VERSION "dbc-export 1 2025.20.8"

NS_ :

BS_:

BU_: APP APS DAS EPAS3S EPASTS ESP GTW IBST IDB PARK RADC RCM RCM3 RCU TPMS USM

BO_ 1045 APP_backupDashCamStatus: 1 APP
 SG_ APP_backupDashCamFeedGood : 0|1@1+ (1,0) [0|1] "" Vector__XXX
 SG_ APP_backupDashCamFrameRate : 1|7@1+ (1,0) [0|127] "" Vector__XXX

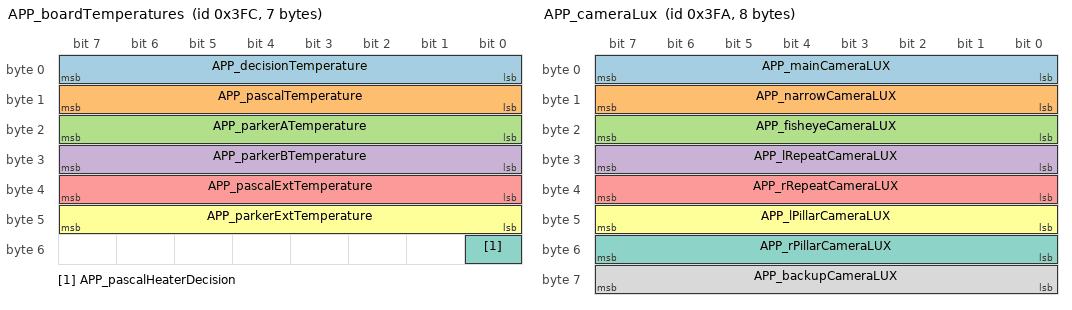
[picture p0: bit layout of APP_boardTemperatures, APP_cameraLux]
BO_ 1020 APP_boardTemperatures: 7 APP
 SG_ APP_decisionTemperature : 0|8@1+ (1,-128) [-128|127] "C" Vector__XXX
 SG_ APP_pascalTemperature : 8|8@1+ (1,-128) [-128|127] "C" Vector__XXX
 SG_ APP_parkerATemperature : 16|8@1+ (1,-128) [-128|127] "C" Vector__XXX
 SG_ APP_parkerBTemperature : 24|8@1+ (1,-128) [-128|127] "C" Vector__XXX
 SG_ APP_pascalExtTemperature : 32|8@1+ (1,-128) [-128|127] "C" Vector__XXX
 SG_ APP_parkerExtTemperature : 40|8@1+ (1,-128) [-128|127] "C" Vector__XXX
 SG_ APP_pascalHeaterDecision : 48|1@1+ (1,0) [0|1] "" Vector__XXX

BO_ 1018 APP_cameraLux: 8 APP
 SG_ APP_mainCameraLUX : 0|8@1+ (0.5,0) [0|127] "lux^0.5" Vector__XXX
 SG_ APP_narrowCameraLUX : 8|8@1+ (0.5,0) [0|127] "lux^0.5" Vector__XXX
 SG_ APP_fisheyeCameraLUX : 16|8@1+ (0.5,0) [0|127] "lux^0.5" Vector__XXX
 SG_ APP_lRepeatCameraLUX : 24|8@1+ (0.5,0) [0|127] "lux^0.5" Vector__XXX
 SG_ APP_rRepeatCameraLUX : 32|8@1+ (0.5,0) [0|127] "lux^0.5" Vector__XXX
 SG_ APP_lPillarCameraLUX : 40|8@1+ (0.5,0) [0|127] "lux^0.5" Vector__XXX
 SG_ APP_rPillarCameraLUX : 48|8@1+ (0.5,0) [0|127] "lux^0.5" Vector__XXX
 SG_ APP_backupCameraLUX : 56|8@1+ (0.5,0) [0|127] "lux^0.5" Vector__XXX

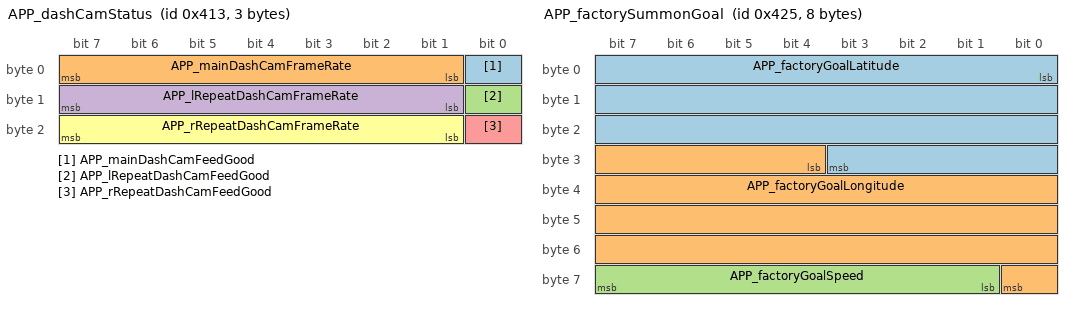
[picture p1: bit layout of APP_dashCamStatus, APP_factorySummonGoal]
BO_ 1043 APP_dashCamStatus: 3 APP
 SG_ APP_mainDashCamFeedGood : 0|1@1+ (1,0) [0|1] "" Vector__XXX
 SG_ APP_mainDashCamFrameRate : 1|7@1+ (1,0) [0|127] "" Vector__XXX
 SG_ APP_lRepeatDashCamFeedGood : 8|1@1+ (1,0) [0|1] "" Vector__XXX
 SG_ APP_lRepeatDashCamFrameRate : 9|7@1+ (1,0) [0|127] "" Vector__XXX
 SG_ APP_rRepeatDashCamFeedGood : 16|1@1+ (1,0) [0|1] "" Vector__XXX
 SG_ APP_rRepeatDashCamFrameRate : 17|7@1+ (1,0) [0|127] "" Vector__XXX

BO_ 1061 APP_factorySummonGoal: 8 APP
 SG_ APP_factoryGoalLatitude : 0|28@1- (1.0e-06,0) [-134.217728|134.217727] "deg" Vector__XXX
 SG_ APP_factoryGoalLongitude : 28|29@1- (1.0e-06,0) [-268.435456|268.435454] "deg" Vector__XXX
 SG_ APP_factoryGoalSpeed : 57|7@1+ (1,0) [0|100] "mph" Vector__XXX

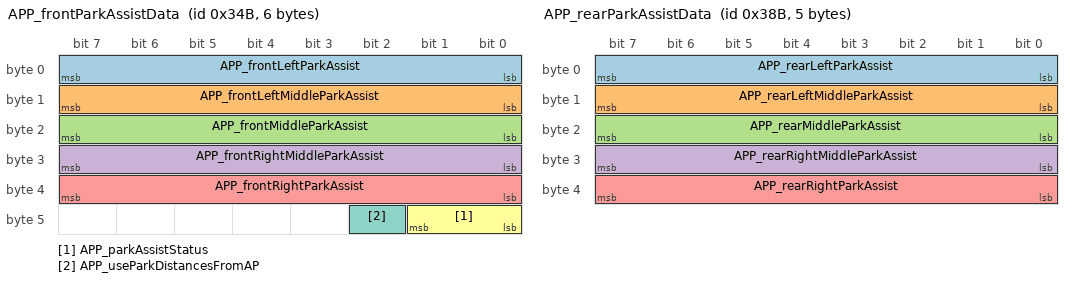
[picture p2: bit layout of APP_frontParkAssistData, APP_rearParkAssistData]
BO_ 843 APP_frontParkAssistData: 6 APP
 SG_ APP_frontLeftParkAssist : 0|8@1+ (1,0) [0|254] "cm" Vector__XXX
 SG_ APP_frontLeftMiddleParkAssist : 8|8@1+ (1,0) [0|254] "cm" Vector__XXX
 SG_ APP_frontMiddleParkAssist : 16|8@1+ (1,0) [0|254] "cm" Vector__XXX
 SG_ APP_frontRightMiddleParkAssist : 24|8@1+ (1,0) [0|254] "cm" Vector__XXX
 SG_ APP_frontRightParkAssist : 32|8@1+ (1,0) [0|254] "cm" Vector__XXX
 SG_ APP_parkAssistStatus : 40|2@1+ (1,0) [0|2] "" Vector__XXX
 SG_ APP_useParkDistancesFromAP : 42|1@1+ (1,0) [0|1] "" Vector__XXX

BO_ 1353 APP_info: 8 APP
 SG_ APP_infoIndex M : 0|8@1+ (1,0) [0|255] "" Vector__XXX
 SG_ APP_buildType m0 : 8|8@1+ (1,0) [0|255] "" Vector__XXX

BO_ 907 APP_rearParkAssistData: 5 APP
 SG_ APP_rearLeftParkAssist : 0|8@1+ (1,0) [0|254] "cm" Vector__XXX
 SG_ APP_rearLeftMiddleParkAssist : 8|8@1+ (1,0) [0|254] "cm" Vector__XXX
 SG_ APP_rearMiddleParkAssist : 16|8@1+ (1,0) [0|254] "cm" Vector__XXX
 SG_ APP_rearRightMiddleParkAssist : 24|8@1+ (1,0) [0|254] "cm" Vector__XXX
 SG_ APP_rearRightParkAssist : 32|8@1+ (1,0) [0|254] "cm" Vector__XXX

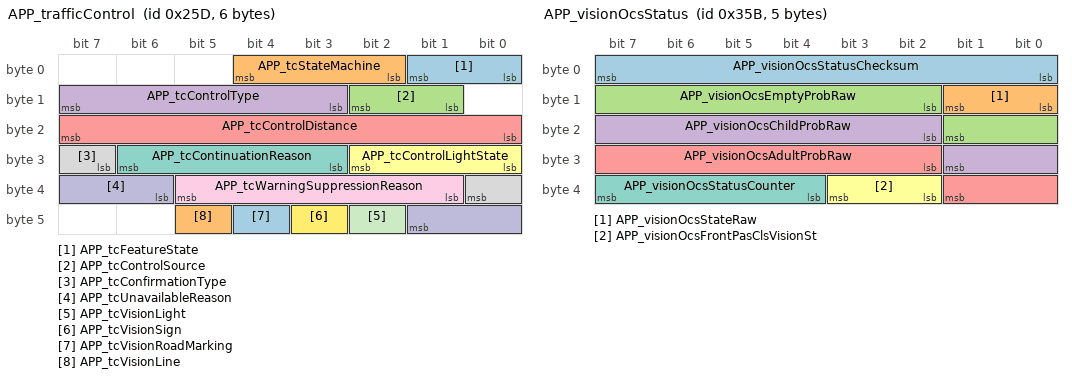
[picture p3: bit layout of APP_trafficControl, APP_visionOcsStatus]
BO_ 605 APP_trafficControl: 6 APP
 SG_ APP_tcFeatureState : 0|2@1+ (1,0) [0|3] "" Vector__XXX
 SG_ APP_tcStateMachine : 2|3@1+ (1,0) [0|7] "" Vector__XXX
 SG_ APP_tcControlSource : 9|2@1+ (1,0) [0|3] "" Vector__XXX
 SG_ APP_tcControlType : 11|5@1+ (1,0) [0|31] "" Vector__XXX
 SG_ APP_tcControlDistance : 16|8@1+ (1,0) [0|254] "m" Vector__XXX
 SG_ APP_tcControlLightState : 24|3@1+ (1,0) [0|7] "" Vector__XXX
 SG_ APP_tcContinuationReason : 27|4@1+ (1,0) [0|15] "" Vector__XXX
 SG_ APP_tcConfirmationType : 31|2@1+ (1,0) [0|3] "" Vector__XXX
 SG_ APP_tcWarningSuppressionReason : 33|5@1+ (1,0) [0|31] "" Vector__XXX
 SG_ APP_tcUnavailableReason : 38|4@1+ (1,0) [0|15] "" Vector__XXX
 SG_ APP_tcVisionLight : 42|1@1+ (1,0) [0|1] "" Vector__XXX
 SG_ APP_tcVisionSign : 43|1@1+ (1,0) [0|1] "" Vector__XXX
 SG_ APP_tcVisionRoadMarking : 44|1@1+ (1,0) [0|1] "" Vector__XXX
 SG_ APP_tcVisionLine : 45|1@1+ (1,0) [0|1] "" Vector__XXX

BO_ 859 APP_visionOcsStatus: 5 APP
 SG_ APP_visionOcsStatusChecksum : 0|8@1+ (1,0) [0|255] "" Vector__XXX
 SG_ APP_visionOcsStateRaw : 8|2@1+ (1,0) [0|3] "" Vector__XXX
 SG_ APP_visionOcsEmptyProbRaw : 10|8@1+ (0.004,0) [0|1.016] "points" Vector__XXX
 SG_ APP_visionOcsChildProbRaw : 18|8@1+ (0.004,0) [0|1.016] "points" Vector__XXX
 SG_ APP_visionOcsAdultProbRaw : 26|8@1+ (0.004,0) [0|1.016] "points" Vector__XXX
 SG_ APP_visionOcsFrontPasClsVisionSt : 34|2@1+ (1,0) [0|3] "" Vector__XXX
 SG_ APP_visionOcsStatusCounter : 36|4@1+ (1,0) [0|15] "" Vector__XXX

BO_ 809 APP_warningMatrix0: 8 APP
 SG_ APP_w001_DEPRECATED : 0|1@1+ (1,0) [0|1] "" Vector__XXX
 SG_ APP_w002_ldwDisabled : 1|1@1+ (1,0) [0|1] "" Vector__XXX
 SG_ APP_w003_isaDisabled : 2|1@1+ (1,0) [0|1] "" Vector__XXX
 SG_ APP_w004_accDisabled : 3|1@1+ (1,0) [0|1] "" Vector__XXX
 SG_ APP_w005_fcwCancelled : 4|1@1+ (1,0) [0|1] "" Vector__XXX
 SG_ APP_w006_aebCancelled : 5|1@1+ (1,0) [0|1] "" Vector__XXX
 SG_ APP_w007_ahlbDisabled : 6|1@1+ (1,0) [0|1] "" Vector__XXX
 SG_ APP_w008_parkDisabled : 7|1@1+ (1,0) [0|1] "" Vector__XXX
 SG_ APP_w009_aebFault : 8|1@1+ (1,0) [0|1] "" Vector__XXX
 SG_ APP_w010_radcCalibIssue : 9|1@1+ (1,0) [0|1] "" Vector__XXX
 SG_ APP_w011_scaEvent : 10|1@1+ (1,0) [0|1] "" Vector__XXX
 SG_ APP_w012_Cam_BootFailure : 11|1@1+ (1,0) [0|1] "" Vector__XXX
 SG_ APP_w013_Cam_Watchdog : 12|1@1+ (1,0) [0|1] "" Vector__XXX
 SG_ APP_w014_swAssert : 13|1@1+ (1,0) [0|1] "" Vector__XXX
 SG_ APP_w015_Camera_Failsafes : 14|1@1+ (1,0) [0|1] "" Vector__XXX
 SG_ APP_w016_aeb_e_event : 15|1@1+ (1,0) [0|1] "" Vector__XXX
 SG_ APP_w017_Cam_Msg_MIA : 16|1@1+ (1,0) [0|1] "" Vector__XXX
 SG_ APP_w018_ECU_Power_Issue : 17|1@1+ (1,0) [0|1] "" Vector__XXX
 SG_ APP_w019_ECU_Stack_Overflow : 18|1@1+ (1,0) [0|1] "" Vector__XXX
 SG_ APP_w020_ECU_checkstopError : 19|1@1+ (1,0) [0|1] "" Vector__XXX
 SG_ APP_w021_ECU_Temperature_Issue : 20|1@1+ (1,0) [0|1] "" Vector__XXX
 SG_ APP_w022_ECU_EEPROM_Failure : 21|1@1+ (1,0) [0|1] "" Vector__XXX
 SG_ APP_w023_ECU_Cam_Statemismatc : 22|1@1+ (1,0) [0|1] "" Vector__XXX
 SG_ APP_w024_ECU_Watchdog_Reset : 23|1@1+ (1,0) [0|1] "" Vector__XXX
 SG_ APP_w025_LC_Steering_Override : 24|1@1+ (1,0) [0|1] "" Vector__XXX
 SG_ APP_w026_ECU_timingIssue : 25|1@1+ (1,0) [0|1] "" Vector__XXX
 SG_ APP_w027_ECU_Reset_Fault : 26|1@1+ (1,0) [0|1] "" Vector__XXX
 SG_ APP_w028_spi_rx_error : 27|1@1+ (1,0) [0|1] "" Vector__XXX
 SG_ APP_w029_spi_tx_error : 28|1@1+ (1,0) [0|1] "" Vector__XXX
 SG_ APP_w030_Heater_Issue : 29|1@1+ (1,0) [0|1] "" Vector__XXX
 SG_ APP_w031_canRxError : 30|1@1+ (1,0) [0|1] "" Vector__XXX
 SG_ APP_w032_canTxError : 31|1@1+ (1,0) [0|1] "" Vector__XXX
 SG_ APP_w033_gtwMia : 32|1@1+ (1,0) [0|1] "" Vector__XXX
 SG_ APP_w034_sccmMia : 33|1@1+ (1,0) [0|1] "" Vector__XXX
 SG_ APP_w035_espMia : 34|1@1+ (1,0) [0|1] "" Vector__XXX
 SG_ APP_w036_bdyMia : 35|1@1+ (1,0) [0|1] "" Vector__XXX
 SG_ APP_w037_camTacIssue : 36|1@1+ (1,0) [0|1] "" Vector__XXX
 SG_ APP_w038_camFailure : 37|1@1+ (1,0) [0|1] "" Vector__XXX
 SG_ APP_w039_sdm_rcm_Mia : 38|1@1+ (1,0) [0|1] "" Vector__XXX
 SG_ APP_w040_autopilotAngleSaturated : 39|1@1+ (1,0) [0|1] "" Vector__XXX
 SG_ APP_w041_autopilotRateSaturated : 40|1@1+ (1,0) [0|1] "" Vector__XXX
 SG_ APP_w042_autopilotAborting : 41|1@1+ (1,0) [0|1] "" Vector__XXX
 SG_ APP_w043_camLongRunTime : 42|1@1+ (1,0) [0|1] "" Vector__XXX
 SG_ APP_w044_appMobileyeFailure : 43|1@1+ (1,0) [0|1] "" Vector__XXX
 SG_ APP_w045_radMia : 44|1@1+ (1,0) [0|1] "" Vector__XXX
 SG_ APP_w046_eepromRecordAbsent : 45|1@1+ (1,0) [0|1] "" Vector__XXX
 SG_ APP_w047_edrEvent : 46|1@1+ (1,0) [0|1] "" Vector__XXX
 SG_ APP_w048_APP_Features_Disabled : 47|1@1+ (1,0) [0|1] "" Vector__XXX
 SG_ APP_w049_eyeqVersionMismatch : 48|1@1+ (1,0) [0|1] "" Vector__XXX
 SG_ APP_w050_aeb_event : 49|1@1+ (1,0) [0|1] "" Vector__XXX
 SG_ APP_w051_radcEcuIssue : 50|1@1+ (1,0) [0|1] "" Vector__XXX
 SG_ APP_w052_radcSensorIssue : 51|1@1+ (1,0) [0|1] "" Vector__XXX
 SG_ APP_w053_radcCommIssue : 52|1@1+ (1,0) [0|1] "" Vector__XXX
 SG_ APP_w054_camAutofix : 53|1@1+ (1,0) [0|1] "" Vector__XXX
 SG_ APP_w055_radcVersionMismatch : 54|1@1+ (1,0) [0|1] "" Vector__XXX
 SG_ APP_w056_diMia : 55|1@1+ (1,0) [0|1] "" Vector__XXX
 SG_ APP_w057_mcuMia : 56|1@1+ (1,0) [0|1] "" Vector__XXX
 SG_ APP_w058_epbMia : 57|1@1+ (1,0) [0|1] "" Vector__XXX
 SG_ APP_w059_parkMia : 58|1@1+ (1,0) [0|1] "" Vector__XXX
 SG_ APP_w060_fcw_event : 59|1@1+ (1,0) [0|1] "" Vector__XXX
 SG_ APP_w061_airSuspensionMia : 60|1@1+ (1,0) [0|1] "" Vector__XXX
 SG_ APP_w062_radcAlignment : 61|1@1+ (1,0) [0|1] "" Vector__XXX
 SG_ APP_w063_parkVersionMismatch : 62|1@1+ (1,0) [0|1] "" Vector__XXX
 SG_ APP_w064_epasMia : 63|1@1+ (1,0) [0|1] "" Vector__XXX

BO_ 873 APP_warningMatrix1: 8 APP
 SG_ APP_w065_deserializerOvercurrent : 0|1@1+ (1,0) [0|1] "" Vector__XXX
 SG_ APP_w066_deserializerLockLost : 1|1@1+ (1,0) [0|1] "" Vector__XXX
 SG_ APP_w067_steeringAlignment : 2|1@1+ (1,0) [0|1] "" Vector__XXX
 SG_ APP_w068_vlInconsistency : 3|1@1+ (1,0) [0|1] "" Vector__XXX
 SG_ APP_w069_apcSpaceMasked : 4|1@1+ (1,0) [0|1] "" Vector__XXX
 SG_ APP_w070_apcIncompleteCal : 5|1@1+ (1,0) [0|1] "" Vector__XXX
 SG_ APP_w071_selfparkStarted : 6|1@1+ (1,0) [0|1] "" Vector__XXX
 SG_ APP_w072_selfparkComplete : 7|1@1+ (1,0) [0|1] "" Vector__XXX
 SG_ APP_w073_issueEscalatedLDW : 8|1@1+ (1,0) [0|1] "" Vector__XXX
 SG_ APP_w074_inPathStationaryObst : 9|1@1+ (1,0) [0|1] "" Vector__XXX
 SG_ APP_w075_scMia : 10|1@1+ (1,0) [0|1] "" Vector__XXX
 SG_ APP_w076_mobilEyeSetC : 11|1@1+ (1,0) [0|1] "" Vector__XXX
 SG_ APP_w077_pmmActive : 12|1@1+ (1,0) [0|1] "" Vector__XXX
 SG_ APP_w078_pmmActive2 : 13|1@1+ (1,0) [0|1] "" Vector__XXX
 SG_ APP_w079_edrAvailable : 14|1@1+ (1,0) [0|1] "" Vector__XXX
 SG_ APP_w080_accFailedActivation : 15|1@1+ (1,0) [0|1] "" Vector__XXX
 SG_ APP_w081_pmmActiveBraking : 16|1@1+ (1,0) [0|1] "" Vector__XXX
 SG_ APP_w082_inPathFSviolation : 17|1@1+ (1,0) [0|1] "" Vector__XXX
 SG_ APP_w083_inPathRADObject : 18|1@1+ (1,0) [0|1] "" Vector__XXX
 SG_ APP_w084_pmmIPSO : 19|1@1+ (1,0) [0|1] "" Vector__XXX
 SG_ APP_w085_pmmSteering : 20|1@1+ (1,0) [0|1] "" Vector__XXX
 SG_ APP_w086_robCollision : 21|1@1+ (1,0) [0|1] "" Vector__XXX
 SG_ APP_w087_DEPRECATED : 22|1@1+ (1,0) [0|1] "" Vector__XXX
 SG_ APP_w088_DEPRECATED : 23|1@1+ (1,0) [0|1] "" Vector__XXX
 SG_ APP_w089_DEPRECATED : 24|1@1+ (1,0) [0|1] "" Vector__XXX
 SG_ APP_w090_DEPRECATED : 25|1@1+ (1,0) [0|1] "" Vector__XXX
 SG_ APP_w091_DEPRECATED : 26|1@1+ (1,0) [0|1] "" Vector__XXX
 SG_ APP_w092_DEPRECATED : 27|1@1+ (1,0) [0|1] "" Vector__XXX
 SG_ APP_w093_DEPRECATED : 28|1@1+ (1,0) [0|1] "" Vector__XXX
 SG_ APP_w094_DEPRECATED : 29|1@1+ (1,0) [0|1] "" Vector__XXX
 SG_ APP_w095_DEPRECATED : 30|1@1+ (1,0) [0|1] "" Vector__XXX
 SG_ APP_w096_DEPRECATED : 31|1@1+ (1,0) [0|1] "" Vector__XXX
 SG_ APP_w097_DEPRECATED : 32|1@1+ (1,0) [0|1] "" Vector__XXX
 SG_ APP_w098_DEPRECATED : 33|1@1+ (1,0) [0|1] "" Vector__XXX
 SG_ APP_w099_DEPRECATED : 34|1@1+ (1,0) [0|1] "" Vector__XXX
 SG_ APP_w100_DEPRECATED : 35|1@1+ (1,0) [0|1] "" Vector__XXX
 SG_ APP_w101_DEPRECATED : 36|1@1+ (1,0) [0|1] "" Vector__XXX
 SG_ APP_w102_DEPRECATED : 37|1@1+ (1,0) [0|1] "" Vector__XXX
 SG_ APP_w103_robExperimentalAEB : 38|1@1+ (1,0) [0|1] "" Vector__XXX
 SG_ APP_w104_DEPRECATED : 39|1@1+ (1,0) [0|1] "" Vector__XXX
 SG_ APP_w105_DEPRECATED : 40|1@1+ (1,0) [0|1] "" Vector__XXX
 SG_ APP_w106_torsionBarOffset : 41|1@1+ (1,0) [0|1] "" Vector__XXX

BO_ 1065 APP_warningMatrix2: 8 APP
 SG_ APP_w129_mainCamExtNotCal : 0|1@1+ (1,0) [0|1] "" Vector__XXX
 SG_ APP_w130_narrowCamExtNotCal : 1|1@1+ (1,0) [0|1] "" Vector__XXX
 SG_ APP_w131_mainCamCalSaved : 2|1@1+ (1,0) [0|1] "" Vector__XXX
 SG_ APP_w132_narrowCamCalSaved : 3|1@1+ (1,0) [0|1] "" Vector__XXX
 SG_ APP_w133_mainCamInitFault : 4|1@1+ (1,0) [0|1] "" Vector__XXX
 SG_ APP_w134_narrowCamInitFault : 5|1@1+ (1,0) [0|1] "" Vector__XXX
 SG_ APP_w135_fisheyeCamInitFault : 6|1@1+ (1,0) [0|1] "" Vector__XXX
 SG_ APP_w136_lPillarCamInitFault : 7|1@1+ (1,0) [0|1] "" Vector__XXX
 SG_ APP_w137_rPillarCamInitFault : 8|1@1+ (1,0) [0|1] "" Vector__XXX
 SG_ APP_w138_lRepeatCamInitFault : 9|1@1+ (1,0) [0|1] "" Vector__XXX
 SG_ APP_w139_rRepeatCamInitFault : 10|1@1+ (1,0) [0|1] "" Vector__XXX
 SG_ APP_w140_backupCamInitFault : 11|1@1+ (1,0) [0|1] "" Vector__XXX
 SG_ APP_w141_ECU_Thermal_Issue : 12|1@1+ (1,0) [0|1] "" Vector__XXX
 SG_ APP_w142_fwdCamPitchProblem : 13|1@1+ (1,0) [0|1] "" Vector__XXX
 SG_ APP_w143_IDF_event : 14|1@1+ (1,0) [0|1] "" Vector__XXX
 SG_ APP_w144_fanctrldError : 15|1@1+ (1,0) [0|1] "" Vector__XXX
 SG_ APP_w145_camSelfCalIssue : 16|1@1+ (1,0) [0|1] "" Vector__XXX
 SG_ APP_w146_telemetryProblem : 17|1@1+ (1,0) [0|1] "" Vector__XXX
 SG_ APP_w147_selfieCamInitFault : 18|1@1+ (1,0) [0|1] "" Vector__XXX
 SG_ APP_w148_overlayActive : 19|1@1+ (1,0) [0|1] "" Vector__XXX
 SG_ APP_w149_diskFull : 20|1@1+ (1,0) [0|1] "" Vector__XXX
 SG_ APP_w150_diMiaPartyBus : 21|1@1+ (1,0) [0|1] "" Vector__XXX
 SG_ APP_w151_epasMiaPartyBus : 22|1@1+ (1,0) [0|1] "" Vector__XXX
 SG_ APP_w152_espMiaPartyBus : 23|1@1+ (1,0) [0|1] "" Vector__XXX
 SG_ APP_w153_rcmMiaPartyBus : 24|1@1+ (1,0) [0|1] "" Vector__XXX
 SG_ APP_w154_vcleftMiaPartyBus : 25|1@1+ (1,0) [0|1] "" Vector__XXX
 SG_ APP_w155_vcrightMiaPartyBus : 26|1@1+ (1,0) [0|1] "" Vector__XXX
 SG_ APP_w156_epblMiaVehBus : 27|1@1+ (1,0) [0|1] "" Vector__XXX
 SG_ APP_w157_sccmMiaVehBus : 28|1@1+ (1,0) [0|1] "" Vector__XXX
 SG_ APP_w158_vcfrontMiaVehBus : 29|1@1+ (1,0) [0|1] "" Vector__XXX
 SG_ APP_w159_vcleftMiaVehBus : 30|1@1+ (1,0) [0|1] "" Vector__XXX
 SG_ APP_w160_vcrightMiaVehBus : 31|1@1+ (1,0) [0|1] "" Vector__XXX
 SG_ APP_w161_backupCameraUnavailable : 32|1@1+ (1,0) [0|1] "" Vector__XXX
 SG_ APP_w162_mainCameraTypeError : 33|1@1+ (1,0) [0|1] "" Vector__XXX
 SG_ APP_w163_narrowCameraTypeError : 34|1@1+ (1,0) [0|1] "" Vector__XXX
 SG_ APP_w164_fisheyeCameraTypeError : 35|1@1+ (1,0) [0|1] "" Vector__XXX
 SG_ APP_w165_lPillarCameraTypeError : 36|1@1+ (1,0) [0|1] "" Vector__XXX
 SG_ APP_w166_rPillarCameraTypeError : 37|1@1+ (1,0) [0|1] "" Vector__XXX
 SG_ APP_w167_lRepeatCameraTypeError : 38|1@1+ (1,0) [0|1] "" Vector__XXX
 SG_ APP_w168_rRepeatCameraTypeError : 39|1@1+ (1,0) [0|1] "" Vector__XXX
 SG_ APP_w169_backupCameraTypeError : 40|1@1+ (1,0) [0|1] "" Vector__XXX
 SG_ APP_w170_selfieCameraTypeError : 41|1@1+ (1,0) [0|1] "" Vector__XXX
 SG_ APP_w171_appHighCoolantFlowReq : 42|1@1+ (1,0) [0|1] "" Vector__XXX
 SG_ APP_w172_fisheyeCamExtNotCal : 43|1@1+ (1,0) [0|1] "" Vector__XXX
 SG_ APP_w173_lPillarCamExtNotCal : 44|1@1+ (1,0) [0|1] "" Vector__XXX
 SG_ APP_w174_rPillarCamExtNotCal : 45|1@1+ (1,0) [0|1] "" Vector__XXX
 SG_ APP_w175_lRepeatCamExtNotCal : 46|1@1+ (1,0) [0|1] "" Vector__XXX
 SG_ APP_w176_rRepeatCamExtNotCal : 47|1@1+ (1,0) [0|1] "" Vector__XXX
 SG_ APP_w177_fisheyeCamCalSaved : 48|1@1+ (1,0) [0|1] "" Vector__XXX
 SG_ APP_w178_lPillarCamCalSaved : 49|1@1+ (1,0) [0|1] "" Vector__XXX
 SG_ APP_w179_rPillarCamCalSaved : 50|1@1+ (1,0) [0|1] "" Vector__XXX
 SG_ APP_w180_lRepeatCamCalSaved : 51|1@1+ (1,0) [0|1] "" Vector__XXX
 SG_ APP_w181_rRepeatCamCalSaved : 52|1@1+ (1,0) [0|1] "" Vector__XXX
 SG_ APP_w182_mainCameraStreamExit : 53|1@1+ (1,0) [0|1] "" Vector__XXX
 SG_ APP_w183_narrowCameraStreamExit : 54|1@1+ (1,0) [0|1] "" Vector__XXX
 SG_ APP_w184_fisheyeCameraStreamExit : 55|1@1+ (1,0) [0|1] "" Vector__XXX
 SG_ APP_w185_lPillarCameraStreamExit : 56|1@1+ (1,0) [0|1] "" Vector__XXX
 SG_ APP_w186_rPillarCameraStreamExit : 57|1@1+ (1,0) [0|1] "" Vector__XXX
 SG_ APP_w187_lRepeatCameraStreamExit : 58|1@1+ (1,0) [0|1] "" Vector__XXX
 SG_ APP_w188_rRepeatCameraStreamExit : 59|1@1+ (1,0) [0|1] "" Vector__XXX
 SG_ APP_w189_backupCameraStreamExit : 60|1@1+ (1,0) [0|1] "" Vector__XXX
 SG_ APP_w190_selfieCameraStreamExit : 61|1@1+ (1,0) [0|1] "" Vector__XXX
 SG_ APP_w191_autopilotAborting : 62|1@1+ (1,0) [0|1] "" Vector__XXX
 SG_ APP_w192_emergencySpeakerFail : 63|1@1+ (1,0) [0|1] "" Vector__XXX

BO_ 1097 APP_warningMatrix4: 8 APP
 SG_ APP_w257_brakeJerkEvent : 0|1@1+ (1,0) [0|1] "" Vector__XXX
 SG_ APP_w258_aebEvent : 1|1@1+ (1,0) [0|1] "" Vector__XXX
 SG_ APP_w259_aebOverrideEvent : 2|1@1+ (1,0) [0|1] "" Vector__XXX
 SG_ APP_w260_collisionWarningEvent : 3|1@1+ (1,0) [0|1] "" Vector__XXX
 SG_ APP_w261_pcieHardwareErrors : 4|1@1+ (1,0) [0|1] "" Vector__XXX
 SG_ APP_w262_apeCalibMode : 5|1@1+ (1,0) [0|1] "" Vector__XXX
 SG_ APP_w263_lssAbort : 6|1@1+ (1,0) [0|1] "" Vector__XXX
 SG_ APP_w264_lssFault : 7|1@1+ (1,0) [0|1] "" Vector__XXX
 SG_ APP_w265_drvOnNavUnavailable : 8|1@1+ (1,0) [0|1] "" Vector__XXX
 SG_ APP_w266_visionScheduleFallback : 9|1@1+ (1,0) [0|1] "" Vector__XXX
 SG_ APP_w267_benchtopEcu : 10|1@1+ (1,0) [0|1] "" Vector__XXX
 SG_ APP_w268_backupCamExtNotCal : 11|1@1+ (1,0) [0|1] "" Vector__XXX
 SG_ APP_w269_autopilotLimited : 12|1@1+ (1,0) [0|1] "" Vector__XXX
 SG_ APP_w270_blindspotRestricted : 13|1@1+ (1,0) [0|1] "" Vector__XXX
 SG_ APP_w271_laneChangeAborted : 14|1@1+ (1,0) [0|1] "" Vector__XXX
 SG_ APP_w272_laneChangeUnavailable : 15|1@1+ (1,0) [0|1] "" Vector__XXX
 SG_ APP_w273_lssEvent : 16|1@1+ (1,0) [0|1] "" Vector__XXX
 SG_ APP_w274_mainCameraStreamErr : 17|1@1+ (1,0) [0|1] "" Vector__XXX
 SG_ APP_w275_narrowCameraStreamErr : 18|1@1+ (1,0) [0|1] "" Vector__XXX
 SG_ APP_w276_fisheyeCameraStreamErr : 19|1@1+ (1,0) [0|1] "" Vector__XXX
 SG_ APP_w277_lPillarCameraStreamErr : 20|1@1+ (1,0) [0|1] "" Vector__XXX
 SG_ APP_w278_rPillarCameraStreamErr : 21|1@1+ (1,0) [0|1] "" Vector__XXX
 SG_ APP_w279_lRepeatCameraStreamErr : 22|1@1+ (1,0) [0|1] "" Vector__XXX
 SG_ APP_w280_rRepeatCameraStreamErr : 23|1@1+ (1,0) [0|1] "" Vector__XXX
 SG_ APP_w281_backupCameraStreamErr : 24|1@1+ (1,0) [0|1] "" Vector__XXX
 SG_ APP_w282_selfieCameraStreamErr : 25|1@1+ (1,0) [0|1] "" Vector__XXX
 SG_ APP_w283_enhancedSummonAbort : 26|1@1+ (1,0) [0|1] "" Vector__XXX
 SG_ APP_w284_gpsAntennaDisconnected : 27|1@1+ (1,0) [0|1] "" Vector__XXX
 SG_ APP_w285_gpsFaultReset : 28|1@1+ (1,0) [0|1] "" Vector__XXX
 SG_ APP_w286_gpsComIssue : 29|1@1+ (1,0) [0|1] "" Vector__XXX
 SG_ APP_w287_gpsFusionStatus : 30|1@1+ (1,0) [0|1] "" Vector__XXX
 SG_ APP_w288_trafficLightWarning : 31|1@1+ (1,0) [0|1] "" Vector__XXX
 SG_ APP_w289_dramCorrEccErrors : 32|1@1+ (1,0) [0|1] "" Vector__XXX
 SG_ APP_w290_dramUncorrEccErrors : 33|1@1+ (1,0) [0|1] "" Vector__XXX
 SG_ APP_w291_stopSignWarning : 34|1@1+ (1,0) [0|1] "" Vector__XXX
 SG_ APP_w293_mainCameraSyncFailed : 36|1@1+ (1,0) [0|1] "" Vector__XXX
 SG_ APP_w294_narrowCameraSyncFailed : 37|1@1+ (1,0) [0|1] "" Vector__XXX
 SG_ APP_w295_fisheyeCameraSyncFailed : 38|1@1+ (1,0) [0|1] "" Vector__XXX
 SG_ APP_w296_lPillarCameraSyncFailed : 39|1@1+ (1,0) [0|1] "" Vector__XXX
 SG_ APP_w297_rPillarCameraSyncFailed : 40|1@1+ (1,0) [0|1] "" Vector__XXX
 SG_ APP_w298_lRepeatCameraSyncFailed : 41|1@1+ (1,0) [0|1] "" Vector__XXX
 SG_ APP_w299_rRepeatCameraSyncFailed : 42|1@1+ (1,0) [0|1] "" Vector__XXX
 SG_ APP_w300_backupCameraSyncFailed : 43|1@1+ (1,0) [0|1] "" Vector__XXX
 SG_ APP_w301_selfieCameraSyncFailed : 44|1@1+ (1,0) [0|1] "" Vector__XXX
 SG_ APP_w302_vcfrontMiaPartyBus : 45|1@1+ (1,0) [0|1] "" Vector__XXX
 SG_ APP_w303_imuIrational : 46|1@1+ (1,0) [0|1] "" Vector__XXX
 SG_ APP_w304_lssCamBlockedStatus : 47|1@1+ (1,0) [0|1] "" Vector__XXX
 SG_ APP_w305_lssCamStreamExit : 48|1@1+ (1,0) [0|1] "" Vector__XXX
 SG_ APP_w306_lssUltrasonicsBlocked : 49|1@1+ (1,0) [0|1] "" Vector__XXX
 SG_ APP_w307_lssTurnSignalFault : 50|1@1+ (1,0) [0|1] "" Vector__XXX
 SG_ APP_w308_iboosterMia : 51|1@1+ (1,0) [0|1] "" Vector__XXX
 SG_ APP_w309_selfieDisabledOnCar : 52|1@1+ (1,0) [0|1] "" Vector__XXX
 SG_ APP_w310_eth0FrameErrors : 53|1@1+ (1,0) [0|1] "" Vector__XXX
 SG_ APP_w311_eth1FrameErrors : 54|1@1+ (1,0) [0|1] "" Vector__XXX
 SG_ APP_w312_mainCamTypeMismatch : 55|1@1+ (1,0) [0|1] "" Vector__XXX
 SG_ APP_w313_narrowCamTypeMismatch : 56|1@1+ (1,0) [0|1] "" Vector__XXX
 SG_ APP_w314_fisheyeCamTypeMismatch : 57|1@1+ (1,0) [0|1] "" Vector__XXX
 SG_ APP_w315_lPillarCamTypeMismatch : 58|1@1+ (1,0) [0|1] "" Vector__XXX
 SG_ APP_w316_rPillarCamTypeMismatch : 59|1@1+ (1,0) [0|1] "" Vector__XXX
 SG_ APP_w317_lRepeatCamTypeMismatch : 60|1@1+ (1,0) [0|1] "" Vector__XXX
 SG_ APP_w318_rRepeatCamTypeMismatch : 61|1@1+ (1,0) [0|1] "" Vector__XXX
 SG_ APP_w319_backupCamTypeMismatch : 62|1@1+ (1,0) [0|1] "" Vector__XXX
 SG_ APP_w320_selfieCamTypeMismatch : 63|1@1+ (1,0) [0|1] "" Vector__XXX

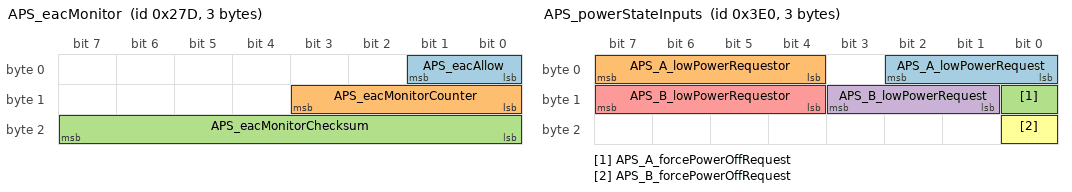
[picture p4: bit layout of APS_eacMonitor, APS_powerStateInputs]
BO_ 637 APS_eacMonitor: 3 APS
 SG_ APS_eacAllow : 0|2@1+ (1,0) [0|2] "" Vector__XXX
 SG_ APS_eacMonitorCounter : 8|4@1+ (1,0) [0|15] "" Vector__XXX
 SG_ APS_eacMonitorChecksum : 16|8@1+ (1,0) [0|255] "" Vector__XXX

BO_ 992 APS_powerStateInputs: 3 APS
 SG_ APS_A_lowPowerRequest : 0|3@1+ (1,0) [0|7] "" Vector__XXX
 SG_ APS_A_lowPowerRequestor : 4|4@1+ (1,0) [0|15] "" Vector__XXX
 SG_ APS_A_forcePowerOffRequest : 8|1@1+ (1,0) [0|1] "" Vector__XXX
 SG_ APS_B_lowPowerRequest : 9|3@1+ (1,0) [0|7] "" Vector__XXX
 SG_ APS_B_lowPowerRequestor : 12|4@1+ (1,0) [0|15] "" Vector__XXX
 SG_ APS_B_forcePowerOffRequest : 16|1@1+ (1,0) [0|1] "" Vector__XXX

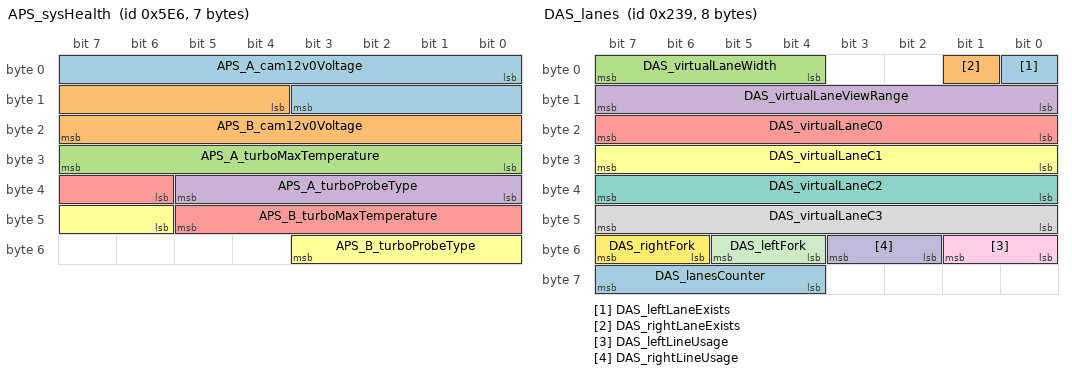
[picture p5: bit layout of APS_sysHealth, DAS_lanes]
BO_ 1510 APS_sysHealth: 7 APS
 SG_ APS_A_cam12v0Voltage : 0|12@1+ (0.0048,0) [0|19.44] "V" Vector__XXX
 SG_ APS_B_cam12v0Voltage : 12|12@1+ (0.0048,0) [0|19.44] "V" Vector__XXX
 SG_ APS_A_turboMaxTemperature : 24|8@1- (1,0) [-128|127] "degC" Vector__XXX
 SG_ APS_A_turboProbeType : 32|6@1+ (1,0) [0|62] "" Vector__XXX
 SG_ APS_B_turboMaxTemperature : 38|8@1- (1,0) [-128|127] "degC" Vector__XXX
 SG_ APS_B_turboProbeType : 46|6@1+ (1,0) [0|62] "" Vector__XXX

BO_ 811 APS_warningMatrix0: 8 APS
 SG_ APS_w001_DEPRECATED : 0|1@1+ (1,0) [0|1] "" Vector__XXX
 SG_ APS_w002_ldwDisabled : 1|1@1+ (1,0) [0|1] "" Vector__XXX
 SG_ APS_w003_isaDisabled : 2|1@1+ (1,0) [0|1] "" Vector__XXX
 SG_ APS_w004_accDisabled : 3|1@1+ (1,0) [0|1] "" Vector__XXX
 SG_ APS_w005_fcwCancelled : 4|1@1+ (1,0) [0|1] "" Vector__XXX
 SG_ APS_w006_aebCancelled : 5|1@1+ (1,0) [0|1] "" Vector__XXX
 SG_ APS_w007_ahlbDisabled : 6|1@1+ (1,0) [0|1] "" Vector__XXX
 SG_ APS_w008_parkDisabled : 7|1@1+ (1,0) [0|1] "" Vector__XXX
 SG_ APS_w009_aebFault : 8|1@1+ (1,0) [0|1] "" Vector__XXX
 SG_ APS_w010_radcCalibIssue : 9|1@1+ (1,0) [0|1] "" Vector__XXX
 SG_ APS_w011_scaEvent : 10|1@1+ (1,0) [0|1] "" Vector__XXX
 SG_ APS_w012_Cam_BootFailure : 11|1@1+ (1,0) [0|1] "" Vector__XXX
 SG_ APS_w013_Cam_Watchdog : 12|1@1+ (1,0) [0|1] "" Vector__XXX
 SG_ APS_w014_swAssert : 13|1@1+ (1,0) [0|1] "" Vector__XXX
 SG_ APS_w015_Camera_Failsafes : 14|1@1+ (1,0) [0|1] "" Vector__XXX
 SG_ APS_w016_aeb_e_event : 15|1@1+ (1,0) [0|1] "" Vector__XXX
 SG_ APS_w017_Cam_Msg_MIA : 16|1@1+ (1,0) [0|1] "" Vector__XXX
 SG_ APS_w018_ECU_Power_Issue : 17|1@1+ (1,0) [0|1] "" Vector__XXX
 SG_ APS_w019_ECU_Stack_Overflow : 18|1@1+ (1,0) [0|1] "" Vector__XXX
 SG_ APS_w020_ECU_checkstopError : 19|1@1+ (1,0) [0|1] "" Vector__XXX
 SG_ APS_w021_ECU_Temperature_Issue : 20|1@1+ (1,0) [0|1] "" Vector__XXX
 SG_ APS_w022_ECU_EEPROM_Failure : 21|1@1+ (1,0) [0|1] "" Vector__XXX
 SG_ APS_w023_ECU_Cam_Statemismatc : 22|1@1+ (1,0) [0|1] "" Vector__XXX
 SG_ APS_w024_ECU_Watchdog_Reset : 23|1@1+ (1,0) [0|1] "" Vector__XXX
 SG_ APS_w025_LC_Steering_Override : 24|1@1+ (1,0) [0|1] "" Vector__XXX
 SG_ APS_w026_ECU_timingIssue : 25|1@1+ (1,0) [0|1] "" Vector__XXX
 SG_ APS_w027_ECU_Reset_Fault : 26|1@1+ (1,0) [0|1] "" Vector__XXX
 SG_ APS_w028_spi_rx_error : 27|1@1+ (1,0) [0|1] "" Vector__XXX
 SG_ APS_w029_spi_tx_error : 28|1@1+ (1,0) [0|1] "" Vector__XXX
 SG_ APS_w030_Heater_Issue : 29|1@1+ (1,0) [0|1] "" Vector__XXX
 SG_ APS_w031_canRxError : 30|1@1+ (1,0) [0|1] "" Vector__XXX
 SG_ APS_w032_canTxError : 31|1@1+ (1,0) [0|1] "" Vector__XXX
 SG_ APS_w033_gtwMia : 32|1@1+ (1,0) [0|1] "" Vector__XXX
 SG_ APS_w034_sccmMia : 33|1@1+ (1,0) [0|1] "" Vector__XXX
 SG_ APS_w035_espMia : 34|1@1+ (1,0) [0|1] "" Vector__XXX
 SG_ APS_w036_bdyMia : 35|1@1+ (1,0) [0|1] "" Vector__XXX
 SG_ APS_w037_camTacIssue : 36|1@1+ (1,0) [0|1] "" Vector__XXX
 SG_ APS_w038_camFailure : 37|1@1+ (1,0) [0|1] "" Vector__XXX
 SG_ APS_w039_sdm_rcm_Mia : 38|1@1+ (1,0) [0|1] "" Vector__XXX
 SG_ APS_w040_autopilotAngleSaturated : 39|1@1+ (1,0) [0|1] "" Vector__XXX
 SG_ APS_w041_autopilotRateSaturated : 40|1@1+ (1,0) [0|1] "" Vector__XXX
 SG_ APS_w042_autopilotAborting : 41|1@1+ (1,0) [0|1] "" Vector__XXX
 SG_ APS_w043_camLongRunTime : 42|1@1+ (1,0) [0|1] "" Vector__XXX
 SG_ APS_w044_appMobileyeFailure : 43|1@1+ (1,0) [0|1] "" Vector__XXX
 SG_ APS_w045_radMia : 44|1@1+ (1,0) [0|1] "" Vector__XXX
 SG_ APS_w046_eepromRecordAbsent : 45|1@1+ (1,0) [0|1] "" Vector__XXX
 SG_ APS_w047_edrEvent : 46|1@1+ (1,0) [0|1] "" Vector__XXX
 SG_ APS_w048_DAS_Features_Disabled : 47|1@1+ (1,0) [0|1] "" Vector__XXX
 SG_ APS_w049_eyeqVersionMismatch : 48|1@1+ (1,0) [0|1] "" Vector__XXX
 SG_ APS_w050_aeb_event : 49|1@1+ (1,0) [0|1] "" Vector__XXX
 SG_ APS_w051_radcEcuIssue : 50|1@1+ (1,0) [0|1] "" Vector__XXX
 SG_ APS_w052_radcSensorIssue : 51|1@1+ (1,0) [0|1] "" Vector__XXX
 SG_ APS_w053_radcCommIssue : 52|1@1+ (1,0) [0|1] "" Vector__XXX
 SG_ APS_w054_camAutofix : 53|1@1+ (1,0) [0|1] "" Vector__XXX
 SG_ APS_w055_radcVersionMismatch : 54|1@1+ (1,0) [0|1] "" Vector__XXX
 SG_ APS_w056_diMia : 55|1@1+ (1,0) [0|1] "" Vector__XXX
 SG_ APS_w057_mcuMia : 56|1@1+ (1,0) [0|1] "" Vector__XXX
 SG_ APS_w058_epbMia : 57|1@1+ (1,0) [0|1] "" Vector__XXX
 SG_ APS_w059_parkMia : 58|1@1+ (1,0) [0|1] "" Vector__XXX
 SG_ APS_w060_fcw_event : 59|1@1+ (1,0) [0|1] "" Vector__XXX
 SG_ APS_w061_tasMia : 60|1@1+ (1,0) [0|1] "" Vector__XXX
 SG_ APS_w062_radcAlignment : 61|1@1+ (1,0) [0|1] "" Vector__XXX
 SG_ APS_w063_parkVersionMismatch : 62|1@1+ (1,0) [0|1] "" Vector__XXX
 SG_ APS_w064_epasMia : 63|1@1+ (1,0) [0|1] "" Vector__XXX

BO_ 876 APS_warningMatrix1: 8 APS
 SG_ APS_w065_deserializerOvercurrent : 0|1@1+ (1,0) [0|1] "" Vector__XXX
 SG_ APS_w066_deserializerLockLost : 1|1@1+ (1,0) [0|1] "" Vector__XXX
 SG_ APS_w067_steeringAlignment : 2|1@1+ (1,0) [0|1] "" Vector__XXX
 SG_ APS_w068_vlInconsistency : 3|1@1+ (1,0) [0|1] "" Vector__XXX
 SG_ APS_w069_apcSpaceMasked : 4|1@1+ (1,0) [0|1] "" Vector__XXX
 SG_ APS_w070_apcIncompleteCal : 5|1@1+ (1,0) [0|1] "" Vector__XXX
 SG_ APS_w071_selfparkStarted : 6|1@1+ (1,0) [0|1] "" Vector__XXX
 SG_ APS_w072_selfparkComplete : 7|1@1+ (1,0) [0|1] "" Vector__XXX
 SG_ APS_w073_issueEscalatedLDW : 8|1@1+ (1,0) [0|1] "" Vector__XXX
 SG_ APS_w074_inPathStationaryObst : 9|1@1+ (1,0) [0|1] "" Vector__XXX
 SG_ APS_w075_scMia : 10|1@1+ (1,0) [0|1] "" Vector__XXX
 SG_ APS_w076_mobilEyeSetC : 11|1@1+ (1,0) [0|1] "" Vector__XXX
 SG_ APS_w077_pmmActive : 12|1@1+ (1,0) [0|1] "" Vector__XXX
 SG_ APS_w078_pmmActive2 : 13|1@1+ (1,0) [0|1] "" Vector__XXX
 SG_ APS_w079_edrAvailable : 14|1@1+ (1,0) [0|1] "" Vector__XXX
 SG_ APS_w080_accFailedActivation : 15|1@1+ (1,0) [0|1] "" Vector__XXX
 SG_ APS_w081_pmmActiveBraking : 16|1@1+ (1,0) [0|1] "" Vector__XXX
 SG_ APS_w082_inPathFSviolation : 17|1@1+ (1,0) [0|1] "" Vector__XXX
 SG_ APS_w083_inPathRADObject : 18|1@1+ (1,0) [0|1] "" Vector__XXX
 SG_ APS_w084_pmmIPSO : 19|1@1+ (1,0) [0|1] "" Vector__XXX
 SG_ APS_w085_pmmSteering : 20|1@1+ (1,0) [0|1] "" Vector__XXX
 SG_ APS_w086_robCollision : 21|1@1+ (1,0) [0|1] "" Vector__XXX
 SG_ APS_w087_DEPRECATED : 22|1@1+ (1,0) [0|1] "" Vector__XXX
 SG_ APS_w088_DEPRECATED : 23|1@1+ (1,0) [0|1] "" Vector__XXX
 SG_ APS_w089_DEPRECATED : 24|1@1+ (1,0) [0|1] "" Vector__XXX
 SG_ APS_w090_DEPRECATED : 25|1@1+ (1,0) [0|1] "" Vector__XXX
 SG_ APS_w091_DEPRECATED : 26|1@1+ (1,0) [0|1] "" Vector__XXX
 SG_ APS_w092_DEPRECATED : 27|1@1+ (1,0) [0|1] "" Vector__XXX
 SG_ APS_w093_DEPRECATED : 28|1@1+ (1,0) [0|1] "" Vector__XXX
 SG_ APS_w094_DEPRECATED : 29|1@1+ (1,0) [0|1] "" Vector__XXX
 SG_ APS_w095_DEPRECATED : 30|1@1+ (1,0) [0|1] "" Vector__XXX
 SG_ APS_w096_DEPRECATED : 31|1@1+ (1,0) [0|1] "" Vector__XXX
 SG_ APS_w097_DEPRECATED : 32|1@1+ (1,0) [0|1] "" Vector__XXX
 SG_ APS_w098_DEPRECATED : 33|1@1+ (1,0) [0|1] "" Vector__XXX
 SG_ APS_w099_DEPRECATED : 34|1@1+ (1,0) [0|1] "" Vector__XXX
 SG_ APS_w100_DEPRECATED : 35|1@1+ (1,0) [0|1] "" Vector__XXX
 SG_ APS_w101_DEPRECATED : 36|1@1+ (1,0) [0|1] "" Vector__XXX
 SG_ APS_w102_DEPRECATED : 37|1@1+ (1,0) [0|1] "" Vector__XXX
 SG_ APS_w103_robExperimentalAEB : 38|1@1+ (1,0) [0|1] "" Vector__XXX
 SG_ APS_w104_DEPRECATED : 39|1@1+ (1,0) [0|1] "" Vector__XXX
 SG_ APS_w105_DEPRECATED : 40|1@1+ (1,0) [0|1] "" Vector__XXX
 SG_ APS_w106_torsionBarOffset : 41|1@1+ (1,0) [0|1] "" Vector__XXX

BO_ 1113 APS_warningMatrix2: 8 APS
 SG_ APS_w129_ECU_Power_Issue : 0|1@1+ (1,0) [0|1] "" Vector__XXX
 SG_ APS_w130_ECU_Thermal_Issue : 1|1@1+ (1,0) [0|1] "" Vector__XXX
 SG_ APS_w131_trap_exception : 2|1@1+ (1,0) [0|1] "" Vector__XXX
 SG_ APS_w132_appVersionMismatch : 3|1@1+ (1,0) [0|1] "" Vector__XXX
 SG_ APS_w133_ETHSwitchError : 4|1@1+ (1,0) [0|1] "" Vector__XXX
 SG_ APS_w134_appMia : 5|1@1+ (1,0) [0|1] "" Vector__XXX
 SG_ APS_w135_appCritical : 6|1@1+ (1,0) [0|1] "" Vector__XXX
 SG_ APS_w136_gpsDisabled : 7|1@1+ (1,0) [0|1] "" Vector__XXX
 SG_ APS_w137_gpsFaultReset : 8|1@1+ (1,0) [0|1] "" Vector__XXX
 SG_ APS_w138_gpsComIssue : 9|1@1+ (1,0) [0|1] "" Vector__XXX
 SG_ APS_w139_udpBufferOverflow : 10|1@1+ (1,0) [0|1] "" Vector__XXX
 SG_ APS_w140_vcfrontMiaVehicleBus : 11|1@1+ (1,0) [0|1] "" Vector__XXX
 SG_ APS_w141_rcmMiaPartyBus : 12|1@1+ (1,0) [0|1] "" Vector__XXX
 SG_ APS_w142_diMiaPartyBus : 13|1@1+ (1,0) [0|1] "" Vector__XXX
 SG_ APS_w143_espMiaPartyBus : 14|1@1+ (1,0) [0|1] "" Vector__XXX
 SG_ APS_w144_vcleftMiaPartyBus : 15|1@1+ (1,0) [0|1] "" Vector__XXX
 SG_ APS_w145_vcrightMiaPartyBus : 16|1@1+ (1,0) [0|1] "" Vector__XXX
 SG_ APS_w146_epas3pMiaPartyBus : 17|1@1+ (1,0) [0|1] "" Vector__XXX
 SG_ APS_w147_vcleftMiaVehBus : 18|1@1+ (1,0) [0|1] "" Vector__XXX
 SG_ APS_w148_vcrightMiaVehBus : 19|1@1+ (1,0) [0|1] "" Vector__XXX
 SG_ APS_w149_epblMiaVehBus : 20|1@1+ (1,0) [0|1] "" Vector__XXX
 SG_ APS_w150_sccmMiaVehBus : 21|1@1+ (1,0) [0|1] "" Vector__XXX
 SG_ APS_w151_apRecovered : 22|1@1+ (1,0) [0|1] "" Vector__XXX
 SG_ APS_w152_gpsFusionStatus : 23|1@1+ (1,0) [0|1] "" Vector__XXX
 SG_ APS_w153_eacInhibit : 24|1@1+ (1,0) [0|1] "" Vector__XXX
 SG_ APS_w155_ethLwipError : 26|1@1+ (1,0) [0|1] "" Vector__XXX
 SG_ APS_w156_lwipAssert : 27|1@1+ (1,0) [0|1] "" Vector__XXX
 SG_ APS_w157_autopilotReboot : 28|1@1+ (1,0) [0|1] "" Vector__XXX
 SG_ APS_w158_apbMia : 29|1@1+ (1,0) [0|1] "" Vector__XXX
 SG_ APS_w159_apbCritical : 30|1@1+ (1,0) [0|1] "" Vector__XXX
 SG_ APS_w160_apbVersionMismatch : 31|1@1+ (1,0) [0|1] "" Vector__XXX
 SG_ APS_w161_gpsAntennaDisconnected : 32|1@1+ (1,0) [0|1] "" Vector__XXX
 SG_ APS_w162_TurboA_DisRegPgoodErr : 33|1@1+ (1,0) [0|1] "" Vector__XXX
 SG_ APS_w163_TurboA_DisRegNFault : 34|1@1+ (1,0) [0|1] "" Vector__XXX
 SG_ APS_w164_TurboA_12VFuseFault : 35|1@1+ (1,0) [0|1] "" Vector__XXX
 SG_ APS_w165_TurboA_Temp_NOS : 36|1@1+ (1,0) [0|1] "" Vector__XXX
 SG_ APS_w166_TurboA_SMSLockStepErr : 37|1@1+ (1,0) [0|1] "" Vector__XXX
 SG_ APS_w167_TurboA_TMU_Throttle : 38|1@1+ (1,0) [0|1] "" Vector__XXX
 SG_ APS_w168_TurboA_SMS_WDOG : 39|1@1+ (1,0) [0|1] "" Vector__XXX
 SG_ APS_w169_TurboA_SCS_LKUP : 40|1@1+ (1,0) [0|1] "" Vector__XXX
 SG_ APS_w170_TurboA_A72_watchdog : 41|1@1+ (1,0) [0|1] "" Vector__XXX
 SG_ APS_w171_TurboA_SMS_taskUtilErr : 42|1@1+ (1,0) [0|1] "" Vector__XXX
 SG_ APS_w172_apFeaturesUnavailable : 43|1@1+ (1,0) [0|1] "" Vector__XXX
 SG_ APS_w178_TurboB_DisRegPgoodErr : 49|1@1+ (1,0) [0|1] "" Vector__XXX
 SG_ APS_w179_TurboB_DisRegNFault : 50|1@1+ (1,0) [0|1] "" Vector__XXX
 SG_ APS_w180_TurboB_12VFuseFault : 51|1@1+ (1,0) [0|1] "" Vector__XXX
 SG_ APS_w181_TurboB_Temp_NOS : 52|1@1+ (1,0) [0|1] "" Vector__XXX
 SG_ APS_w182_TurboB_SMSLockStepErr : 53|1@1+ (1,0) [0|1] "" Vector__XXX
 SG_ APS_w183_TurboB_TMU_Throttle : 54|1@1+ (1,0) [0|1] "" Vector__XXX
 SG_ APS_w184_TurboB_SMS_WDOG : 55|1@1+ (1,0) [0|1] "" Vector__XXX
 SG_ APS_w185_TurboB_SCS_LKUP : 56|1@1+ (1,0) [0|1] "" Vector__XXX
 SG_ APS_w186_TurboB_A72_watchdog : 57|1@1+ (1,0) [0|1] "" Vector__XXX
 SG_ APS_w187_TurboB_SMS_taskUtilErr : 58|1@1+ (1,0) [0|1] "" Vector__XXX
 SG_ APS_w188_otherTurboUartMIA : 59|1@1+ (1,0) [0|1] "" Vector__XXX
 SG_ APS_w189_vcfrontMiaPartyBus : 60|1@1+ (1,0) [0|1] "" Vector__XXX
 SG_ APS_w190_iboosterMia : 61|1@1+ (1,0) [0|1] "" Vector__XXX
 SG_ APS_w191_timesyncError : 62|1@1+ (1,0) [0|1] "" Vector__XXX
 SG_ APS_w192_CANFault : 63|1@1+ (1,0) [0|1] "" Vector__XXX

BO_ 848 APS_warningMatrix3: 8 APS
 SG_ APS_w193_camWindshieldUnclean : 0|1@1+ (1,0) [0|1] "" Vector__XXX
 SG_ APS_w194_accDriverResumeRqrd : 1|1@1+ (1,0) [0|1] "" Vector__XXX
 SG_ APS_w195_scwUnavailable : 2|1@1+ (1,0) [0|1] "" Vector__XXX
 SG_ APS_w196_stopSignWarning : 3|1@1+ (1,0) [0|1] "" Vector__XXX
 SG_ APS_w197_redLightWarning : 4|1@1+ (1,0) [0|1] "" Vector__XXX
 SG_ APS_w198_tsrUnavailable : 5|1@1+ (1,0) [0|1] "" Vector__XXX
 SG_ APS_w199_apcAbort : 6|1@1+ (1,0) [0|1] "" Vector__XXX
 SG_ APS_w200_lcSlowdown : 7|1@1+ (1,0) [0|1] "" Vector__XXX
 SG_ APS_w201_lcAborting : 8|1@1+ (1,0) [0|1] "" Vector__XXX
 SG_ APS_w202_scwNoisyEnvironment : 9|1@1+ (1,0) [0|1] "" Vector__XXX
 SG_ APS_w203_apcActivation : 10|1@1+ (1,0) [0|1] "" Vector__XXX
 SG_ APS_w204_apcFinalFront : 11|1@1+ (1,0) [0|1] "" Vector__XXX
 SG_ APS_w205_apcFinalRear : 12|1@1+ (1,0) [0|1] "" Vector__XXX
 SG_ APS_w206_autosteerNotEnabled : 13|1@1+ (1,0) [0|1] "" Vector__XXX
 SG_ APS_w207_autosteerUnavailable : 14|1@1+ (1,0) [0|1] "" Vector__XXX
 SG_ APS_w208_rackDetected : 15|1@1+ (1,0) [0|1] "" Vector__XXX
 SG_ APS_w209_autoSummonRequest : 16|1@1+ (1,0) [0|1] "" Vector__XXX
 SG_ APS_w210_camObstrcted : 17|1@1+ (1,0) [0|1] "" Vector__XXX
 SG_ APS_w211_accNoSeatBelt : 18|1@1+ (1,0) [0|1] "" Vector__XXX
 SG_ APS_w212_lcUnavailableStrikeOut : 19|1@1+ (1,0) [0|1] "" Vector__XXX
 SG_ APS_w213_autosteerStruckOut : 20|1@1+ (1,0) [0|1] "" Vector__XXX
 SG_ APS_w214_driverNotIntracting : 21|1@1+ (1,0) [0|1] "" Vector__XXX
 SG_ APS_w215_contDriverNotIntracting : 22|1@1+ (1,0) [0|1] "" Vector__XXX
 SG_ APS_w216_driverOverriding : 23|1@1+ (1,0) [0|1] "" Vector__XXX
 SG_ APS_w217_lcUnavailableSpeeding : 24|1@1+ (1,0) [0|1] "" Vector__XXX
 SG_ APS_w218_lcSpeedExceededLimit : 25|1@1+ (1,0) [0|1] "" Vector__XXX
 SG_ APS_w219_lcTempUnavailableSpeed : 26|1@1+ (1,0) [0|1] "" Vector__XXX
 SG_ APS_w220_lcTempUnavailableRoad : 27|1@1+ (1,0) [0|1] "" Vector__XXX
 SG_ APS_w221_accRadarBlind : 28|1@1+ (1,0) [0|1] "" Vector__XXX
 SG_ APS_w222_accCameraBlind : 29|1@1+ (1,0) [0|1] "" Vector__XXX
 SG_ APS_w223_accObjectInPath : 30|1@1+ (1,0) [0|1] "" Vector__XXX
 SG_ APS_w224_accCameraCalibration : 31|1@1+ (1,0) [0|1] "" Vector__XXX
 SG_ APS_w225_lcDegradedVisSpeedLmt : 32|1@1+ (1,0) [0|1] "" Vector__XXX
 SG_ APS_w226_lcCamCalNeededSpeedLmt : 33|1@1+ (1,0) [0|1] "" Vector__XXX
 SG_ APS_w227_virtualWallBlocked : 34|1@1+ (1,0) [0|1] "" Vector__XXX
 SG_ APS_w228_DEPRECATED : 35|1@1+ (1,0) [0|1] "" Vector__XXX
 SG_ APS_w229_alcUltrasoundDamaged : 36|1@1+ (1,0) [0|1] "" Vector__XXX
 SG_ APS_w230_alcUltrasoundBlocked : 37|1@1+ (1,0) [0|1] "" Vector__XXX
 SG_ APS_w231_idfEvent : 38|1@1+ (1,0) [0|1] "" Vector__XXX
 SG_ APS_w232_laneChangeRequested : 39|1@1+ (1,0) [0|1] "" Vector__XXX
 SG_ APS_w235_a72LoopDetected : 42|1@1+ (1,0) [0|1] "" Vector__XXX
 SG_ APS_w236_canSharedMemError : 43|1@1+ (1,0) [0|1] "" Vector__XXX
 SG_ APS_w237_faultMgrEventDetected : 44|1@1+ (1,0) [0|1] "" Vector__XXX
 SG_ APS_w238_resetReason : 45|1@1+ (1,0) [0|1] "" Vector__XXX
 SG_ APS_w241_ddrInitFailures : 48|1@1+ (1,0) [0|1] "" Vector__XXX
 SG_ APS_w242_tripMBISTFailure : 49|1@1+ (1,0) [0|1] "" Vector__XXX
 SG_ APS_w243_tripHWErrorStatus : 50|1@1+ (1,0) [0|1] "" Vector__XXX
 SG_ APS_w244_gpuHWFaultStatus : 51|1@1+ (1,0) [0|1] "" Vector__XXX
 SG_ APS_w245_eloopRxFromUnexpectedSo : 52|1@1+ (1,0) [0|1] "" Vector__XXX
 SG_ APS_w246_ethloopSwitchPortLinkDo : 53|1@1+ (1,0) [0|1] "" Vector__XXX
 SG_ APS_w247_ethernetFrameError : 54|1@1+ (1,0) [0|1] "" Vector__XXX
 SG_ APS_w248_ethloopSwitchPoorSqi : 55|1@1+ (1,0) [0|1] "" Vector__XXX
 SG_ APS_w249_ufsFailures : 56|1@1+ (1,0) [0|1] "" Vector__XXX
 SG_ APS_w250_ethloopSwitchMemUsageTo : 57|1@1+ (1,0) [0|1] "" Vector__XXX
 SG_ APS_w251_ethloopSwitchMemUsageTo : 58|1@1+ (1,0) [0|1] "" Vector__XXX
 SG_ APS_w252_ethSwitchPortLinkDown : 59|1@1+ (1,0) [0|1] "" Vector__XXX
 SG_ APS_w253_powerStateTimeout : 60|1@1+ (1,0) [0|1] "" Vector__XXX
 SG_ APS_w254_sleepStateTimeout : 61|1@1+ (1,0) [0|1] "" Vector__XXX
 SG_ APS_w255_bootHealth : 62|1@1+ (1,0) [0|1] "" Vector__XXX

BO_ 1465 DAS_alertLog: 8 DAS
 SG_ DAS_alertID M : 0|15@1+ (1,0) [0|32767] "" Vector__XXX
 SG_ DAS_alertState : 15|1@1+ (1,0) [0|1] "" Vector__XXX
 SG_ DAS_sw073_escalateLDWs m73 : 16|1@1+ (1,0) [0|1] "" Vector__XXX
 SG_ DAS_sw073_silentEscalatedLDW m73 : 17|1@1+ (1,0) [0|1] "" Vector__XXX
 SG_ DAS_sw073_escalateLDWreason m73 : 18|3@1+ (1,0) [0|7] "" Vector__XXX
 SG_ DAS_sw073_rawMobileyeLDW m73 : 21|2@1+ (1,0) [0|3] "" Vector__XXX
 SG_ DAS_sw073_freespaceLDW m73 : 24|2@1+ (1,0) [0|3] "" Vector__XXX
 SG_ DAS_sw073_freespaceLeftC0 m73 : 26|7@1+ (0.2,-12.8) [-12.8|12.6] "m" Vector__XXX
 SG_ DAS_sw073_freespaceRightC0 m73 : 33|7@1+ (0.2,-12.8) [-12.8|12.6] "m" Vector__XXX
 SG_ DAS_sw073_freespaceLeftC1 m73 : 40|8@1+ (0.0016,-0.2) [-0.2|0.208] "rad" Vector__XXX
 SG_ DAS_sw073_freespaceRightC1 m73 : 48|8@1+ (0.0016,-0.2) [-0.2|0.208] "rad" Vector__XXX
 SG_ DAS_sw073_freespaceLeftFarZ m73 : 56|4@1+ (4,0) [0|60] "m" Vector__XXX
 SG_ DAS_sw073_freespaceRightFarZ m73 : 60|4@1+ (4,0) [0|60] "m" Vector__XXX
 SG_ DAS_sw230_sensor1Blocked m230 : 16|1@1+ (1,0) [0|1] "" Vector__XXX
 SG_ DAS_sw230_sensor2Blocked m230 : 17|1@1+ (1,0) [0|1] "" Vector__XXX
 SG_ DAS_sw230_sensor3Blocked m230 : 18|1@1+ (1,0) [0|1] "" Vector__XXX
 SG_ DAS_sw230_sensor4Blocked m230 : 19|1@1+ (1,0) [0|1] "" Vector__XXX
 SG_ DAS_sw230_sensor5Blocked m230 : 20|1@1+ (1,0) [0|1] "" Vector__XXX
 SG_ DAS_sw230_sensor6Blocked m230 : 21|1@1+ (1,0) [0|1] "" Vector__XXX
 SG_ DAS_sw230_sensor7Blocked m230 : 22|1@1+ (1,0) [0|1] "" Vector__XXX
 SG_ DAS_sw230_sensor8Blocked m230 : 23|1@1+ (1,0) [0|1] "" Vector__XXX
 SG_ DAS_sw230_sensor9Blocked m230 : 24|1@1+ (1,0) [0|1] "" Vector__XXX
 SG_ DAS_sw230_sensor10Blocked m230 : 25|1@1+ (1,0) [0|1] "" Vector__XXX
 SG_ DAS_sw230_sensor11Blocked m230 : 26|1@1+ (1,0) [0|1] "" Vector__XXX
 SG_ DAS_sw230_sensor12Blocked m230 : 27|1@1+ (1,0) [0|1] "" Vector__XXX

BO_ 1497 DAS_carLog: 8 DAS
 SG_ DAS_carLogMultiplexer M : 0|4@1+ (1,0) [0|15] "" Vector__XXX
 SG_ DAS_radarTarget5_dx m1 : 4|12@1+ (0.0625,0) [0|255.9375] "m" Vector__XXX
 SG_ DAS_radarTarget1_dx m1 : 24|12@1+ (0.0625,0) [0|255.9375] "m" Vector__XXX
 SG_ DAS_radarTarget1_VxRel m1 : 36|8@1+ (0.2,-25.6) [-25.6|25.4] "m/s" Vector__XXX
 SG_ DAS_mobileyeVehAebFlag m2 : 4|1@1+ (1,0) [0|1] "" Vector__XXX
 SG_ DAS_mobileyePedAebFlag m2 : 5|1@1+ (1,0) [0|1] "" Vector__XXX
 SG_ DAS_mobileyeIPSOapproved m2 : 6|1@1+ (1,0) [0|1] "" Vector__XXX
 SG_ DAS_fcmSteeringOverride m2 : 7|1@1+ (1,0) [0|1] "" Vector__XXX
 SG_ DAS_fcmCollisionStage3Checks m2 : 8|8@1+ (1,0) [0|255] "" Vector__XXX
 SG_ DAS_fcmThreatAssesmentMode m2 : 16|3@1+ (1,0) [0|7] "" Vector__XXX
 SG_ DAS_constructionArea m2 : 19|2@1+ (1,0) [0|3] "" Vector__XXX
 SG_ DAS_restrictionLowSpeedTraffic m2 : 21|1@1+ (1,0) [0|1] "" Vector__XXX
 SG_ DAS_associated_rad_object m2 : 22|2@1+ (1,0) [0|3] "" Vector__XXX
 SG_ DAS_LC_handsOnReason m2 : 24|6@1+ (1,0) [0|63] "" Vector__XXX
 SG_ DAS_ACC_camStatus m2 : 30|2@1+ (1,0) [0|3] "" Vector__XXX
 SG_ DAS_aeb_not_activating_reason m2 : 32|5@1+ (1,0) [0|31] "" Vector__XXX
 SG_ DAS_handsOnDetected m2 : 38|2@1+ (1,0) [1|3] "" Vector__XXX
 SG_ DAS_driveOnNavUnavailableReason m2 : 40|5@1+ (1,0) [0|31] "" Vector__XXX
 SG_ DAS_accUnavailableReason m2 : 46|7@1+ (1,0) [0|127] "" Vector__XXX
 SG_ DAS_pmmNotActivatingReason m2 : 53|5@1+ (1,0) [0|31] "" Vector__XXX
 SG_ DAS_desiredTarget_dx m3 : 16|8@1+ (0.5,0) [0|127] "m" Vector__XXX
 SG_ DAS_radarTarget2_dx m3 : 24|12@1+ (0.0625,0) [0|255.9375] "m" Vector__XXX
 SG_ DAS_radarTarget3_dx m3 : 36|12@1+ (0.0625,0) [0|255.9375] "m" Vector__XXX
 SG_ DAS_radarTarget4_dx m3 : 48|12@1+ (0.0625,0) [0|255.9375] "m" Vector__XXX
 SG_ DAS_closestInLaneTargetDx m4 : 4|12@1+ (0.0625,0) [0|255.9375] "m" Vector__XXX
 SG_ DAS_secondInLaneTargetDx m4 : 16|12@1+ (0.0625,0) [0|255.9375] "m" Vector__XXX
 SG_ DAS_closestLeftLaneTargetDx m4 : 28|12@1+ (0.0625,0) [0|255.9375] "m" Vector__XXX
 SG_ DAS_closestRightLaneTargetDx m4 : 40|12@1+ (0.0625,0) [0|255.9375] "m" Vector__XXX
 SG_ DAS_closestInLaneTargetVxRel m4 : 52|10@1+ (0.1,-51.1) [-51.1|51.2] "m/s" Vector__XXX

BO_ 1337 DAS_info: 8 DAS
 SG_ DAS_infoIndex M : 0|8@1+ (1,0) [0|255] "" Vector__XXX
 SG_ DAS_infoBuildType m10 : 8|8@1+ (1,0) [0|255] "" Vector__XXX
 SG_ DAS_infoBuildConfigID m10 : 16|16@1+ (1,0) [0|65535] "" Vector__XXX
 SG_ DAS_infoHardwareID m10 : 32|16@1+ (1,0) [0|65535] "" Vector__XXX
 SG_ DAS_infoComponentID m10 : 48|16@1+ (1,0) [0|65535] "" Vector__XXX
 SG_ DAS_infoPcbaID m11 : 16|8@1+ (1,0) [0|255] "" Vector__XXX
 SG_ DAS_infoAssemblyID m11 : 24|8@1+ (1,0) [0|255] "" Vector__XXX
 SG_ DAS_infoUsageID m11 : 32|16@1+ (1,0) [0|65535] "" Vector__XXX
 SG_ DAS_infoSubUsageID m11 : 48|16@1+ (1,0) [0|65535] "" Vector__XXX
 SG_ DAS_infoApplicationCRC m13 : 32|32@1+ (1,0) [0|4294967295] "" Vector__XXX
 SG_ DAS_infoAppGitHashBytes m17 : 8|56@1+ (1,0) [0|7.20575940379e+16] "" Vector__XXX
 SG_ DAS_infoBootGitHashBytes m18 : 8|56@1+ (1,0) [0|7.20575940379e+16] "" Vector__XXX

BO_ 569 DAS_lanes: 8 DAS
 SG_ DAS_leftLaneExists : 0|1@1+ (1,0) [0|1] "" Vector__XXX
 SG_ DAS_rightLaneExists : 1|1@1+ (1,0) [0|1] "" Vector__XXX
 SG_ DAS_virtualLaneWidth : 4|4@1+ (0.3125,2) [2|6.6875] "m" Vector__XXX
 SG_ DAS_virtualLaneViewRange : 8|8@1+ (1,0) [0|160] "m" Vector__XXX
 SG_ DAS_virtualLaneC0 : 16|8@1+ (0.035,-3.5) [-3.5|3.5] "m" Vector__XXX
 SG_ DAS_virtualLaneC1 : 24|8@1+ (0.0016,-0.2) [-0.2|0.2] "rad" Vector__XXX
 SG_ DAS_virtualLaneC2 : 32|8@1+ (2.0e-05,-0.0025) [-0.0025|0.0025] "m-1" Vector__XXX
 SG_ DAS_virtualLaneC3 : 40|8@1+ (2.4e-07,-3.0e-05) [-3.0e-05|3.0e-05] "m-2" Vector__XXX
 SG_ DAS_leftLineUsage : 48|2@1+ (1,0) [0|3] "" Vector__XXX
 SG_ DAS_rightLineUsage : 50|2@1+ (1,0) [0|3] "" Vector__XXX
 SG_ DAS_leftFork : 52|2@1+ (1,0) [0|3] "" Vector__XXX
 SG_ DAS_rightFork : 54|2@1+ (1,0) [0|3] "" Vector__XXX
 SG_ DAS_lanesCounter : 60|4@1+ (1,0) [0|15] "" Vector__XXX

BO_ 921 DAS_status: 8 DAS
 SG_ DAS_autopilotState : 0|4@1+ (1,0) [0|14] "" Vector__XXX
 SG_ DAS_blindSpotRearLeft : 4|2@1+ (1,0) [0|2] "" Vector__XXX
 SG_ DAS_blindSpotRearRight : 6|2@1+ (1,0) [0|2] "" Vector__XXX
 SG_ DAS_fusedSpeedLimit : 8|5@1+ (5,0) [5|150] "kph/mph" Vector__XXX
 SG_ DAS_suppressSpeedWarning : 13|1@1+ (1,0) [0|1] "" Vector__XXX
 SG_ DAS_summonObstacle : 14|1@1+ (1,0) [0|1] "" Vector__XXX
 SG_ DAS_summonClearedGate : 15|1@1+ (1,0) [0|1] "" Vector__XXX
 SG_ DAS_visionOnlySpeedLimit : 16|5@1+ (5,0) [5|150] "kph/mph" Vector__XXX
 SG_ DAS_heaterState : 21|1@1+ (1,0) [0|1] "" Vector__XXX
 SG_ DAS_forwardCollisionWarning : 22|2@1+ (1,0) [0|2] "" Vector__XXX
 SG_ DAS_autoparkReady : 24|1@1+ (1,0) [0|1] "" Vector__XXX
 SG_ DAS_autoParked : 25|1@1+ (1,0) [0|1] "" Vector__XXX
 SG_ DAS_autoparkActive : 26|1@1+ (1,0) [0|1] "" Vector__XXX
 SG_ DAS_summonFwdLeashReached : 27|1@1+ (1,0) [0|1] "" Vector__XXX
 SG_ DAS_summonRvsLeashReached : 28|1@1+ (1,0) [0|1] "" Vector__XXX
 SG_ DAS_lssState : 29|3@1+ (1,0) [0|7] "" Vector__XXX
 SG_ DAS_sideCollisionAvoid : 32|2@1+ (1,0) [0|2] "" Vector__XXX
 SG_ DAS_sideCollisionWarning : 34|2@1+ (1,0) [0|3] "" Vector__XXX
 SG_ DAS_sideCollisionInhibit : 36|1@1+ (1,0) [0|1] "" Vector__XXX
 SG_ DAS_laneDepartureWarning : 37|3@1+ (1,0) [0|7] "" Vector__XXX
 SG_ DAS_fleetSpeedState : 40|2@1+ (1,0) [0|3] "" Vector__XXX
 SG_ DAS_autopilotHandsOnState : 42|4@1+ (1,0) [0|14] "" Vector__XXX
 SG_ DAS_autoLaneChangeState : 46|5@1+ (1,0) [0|30] "" Vector__XXX
 SG_ DAS_summonAvailable : 51|1@1+ (1,0) [0|1] "" Vector__XXX
 SG_ DAS_statusCounter : 52|4@1+ (1,0) [0|15] "" Vector__XXX
 SG_ DAS_statusChecksum : 56|8@1+ (1,0) [0|255] "" Vector__XXX

BO_ 905 DAS_status2: 8 DAS
 SG_ DAS_accSpeedLimit : 0|9@1+ (0.4,0) [0|200] "mph" Vector__XXX
 SG_ DAS_versionIdentifier : 9|1@1+ (1,0) [0|1] "" Vector__XXX
 SG_ DAS_pmmObstacleSeverity : 10|3@1+ (1,0) [0|6] "" Vector__XXX
 SG_ DAS_pmmLoggingRequest : 13|1@1+ (1,0) [0|1] "" Vector__XXX
 SG_ DAS_activationFailureStatus : 14|2@1+ (1,0) [0|3] "" Vector__XXX
 SG_ DAS_pmmUltrasonicsFaultReason : 16|3@1+ (1,0) [0|7] "" Vector__XXX
 SG_ DAS_pmmRadarFaultReason : 19|2@1+ (1,0) [0|3] "" Vector__XXX
 SG_ DAS_pmmSysFaultReason : 21|3@1+ (1,0) [0|7] "" Vector__XXX
 SG_ DAS_pmmCameraFaultReason : 24|2@1+ (1,0) [0|3] "" Vector__XXX
 SG_ DAS_ACC_report : 26|5@1+ (1,0) [0|31] "" Vector__XXX
 SG_ DAS_relaxCruiseLimits : 31|1@1+ (1,0) [0|1] "" Vector__XXX
 SG_ DAS_csaState : 32|2@1+ (1,0) [0|3] "" Vector__XXX
 SG_ DAS_radarTelemetry : 34|2@1+ (1,0) [0|3] "" Vector__XXX
 SG_ DAS_robState : 36|2@1+ (1,0) [0|3] "" Vector__XXX
 SG_ DAS_driverInteractionLevel : 38|2@1+ (1,0) [0|3] "" Vector__XXX
 SG_ DAS_ppOffsetDesiredRamp : 40|8@1+ (0.01,-1.28) [-1.28|1.27] "m" Vector__XXX
 SG_ DAS_longCollisionWarning : 48|4@1+ (1,0) [0|14] "" Vector__XXX
 SG_ DAS_status2Counter : 52|4@1+ (1,0) [0|15] "" Vector__XXX
 SG_ DAS_status2Checksum : 56|8@1+ (1,0) [0|255] "" Vector__XXX

BO_ 586 DAS_visualDebug: 8 DAS
 SG_ DAS_autosteerVehiclesUsage : 4|2@1+ (1,0) [0|3] "" Vector__XXX
 SG_ DAS_autosteerHPPUsage : 6|2@1+ (1,0) [0|3] "" Vector__XXX
 SG_ DAS_autosteerNavigationUsage : 8|2@1+ (1,0) [0|3] "" Vector__XXX
 SG_ DAS_autosteerModelUsage : 10|2@1+ (1,0) [0|3] "" Vector__XXX
 SG_ DAS_autosteerBottsDotsUsage : 12|2@1+ (1,0) [0|3] "" Vector__XXX
 SG_ DAS_offsetSide : 14|2@1+ (1,0) [0|3] "" Vector__XXX
 SG_ DAS_roadSurfaceType : 16|2@1+ (1,0) [1|3] "" Vector__XXX
 SG_ DAS_autosteerHealthAnomalyLevel : 18|3@1+ (1,0) [0|7] "" Vector__XXX
 SG_ DAS_autosteerHealthState : 21|3@1+ (1,0) [0|7] "" Vector__XXX
 SG_ DAS_lastLinePreferenceReason : 24|4@1+ (1,0) [0|15] "" Vector__XXX
 SG_ DAS_plannerState : 28|4@1+ (1,0) [0|15] "" Vector__XXX
 SG_ DAS_lastAutosteerAbortReason : 32|6@1+ (1,0) [0|63] "" Vector__XXX
 SG_ DAS_devAppInterfaceEnabled : 38|1@1+ (1,0) [0|1] "" Vector__XXX
 SG_ DAS_navAvailable : 39|1@1+ (1,0) [0|1] "" Vector__XXX
 SG_ DAS_navDistance : 40|8@1+ (100,0) [0|25500] "km" Vector__XXX
 SG_ DAS_accSmartSpeedActive : 48|1@1+ (1,0) [0|1] "" Vector__XXX
 SG_ DAS_accSmartSpeedState : 49|3@1+ (1,0) [0|6] "" Vector__XXX
 SG_ DAS_ulcInProgress : 52|1@1+ (1,0) [0|1] "" Vector__XXX
 SG_ DAS_trafficAwareSetSpeedInUse : 53|1@1+ (1,0) [0|1] "" Vector__XXX
 SG_ DAS_isaSystemState : 54|2@1+ (1,0) [0|3] "" Vector__XXX
 SG_ DAS_behaviorType : 56|2@1+ (1,0) [0|3] "" Vector__XXX
 SG_ DAS_ulcType : 58|2@1+ (1,0) [0|3] "" Vector__XXX
 SG_ DAS_rearVehDetectedThisCycle : 60|1@1+ (1,0) [0|1] "" Vector__XXX
 SG_ DAS_rearLeftVehDetectedCurrent : 61|1@1+ (1,0) [0|1] "" Vector__XXX
 SG_ DAS_rearRightVehDetectedTrip : 62|1@1+ (1,0) [0|1] "" Vector__XXX
 SG_ DAS_rearLeftVehDetectedTrip : 63|1@1+ (1,0) [0|1] "" Vector__XXX

BO_ 810 DAS_warningMatrix0: 8 DAS
 SG_ DAS_w002_ldwDisabled : 1|1@1+ (1,0) [0|1] "" Vector__XXX
 SG_ DAS_w003_isaDisabled : 2|1@1+ (1,0) [0|1] "" Vector__XXX
 SG_ DAS_w004_accDisabled : 3|1@1+ (1,0) [0|1] "" Vector__XXX
 SG_ DAS_w005_fcwCancelled : 4|1@1+ (1,0) [0|1] "" Vector__XXX
 SG_ DAS_w006_aebCancelled : 5|1@1+ (1,0) [0|1] "" Vector__XXX
 SG_ DAS_w007_ahlbDisabled : 6|1@1+ (1,0) [0|1] "" Vector__XXX
 SG_ DAS_w008_parkDisabled : 7|1@1+ (1,0) [0|1] "" Vector__XXX
 SG_ DAS_w009_aebFault : 8|1@1+ (1,0) [0|1] "" Vector__XXX
 SG_ DAS_w010_radcCalibIssue : 9|1@1+ (1,0) [0|1] "" Vector__XXX
 SG_ DAS_w011_scaEvent : 10|1@1+ (1,0) [0|1] "" Vector__XXX
 SG_ DAS_w012_Cam_BootFailure : 11|1@1+ (1,0) [0|1] "" Vector__XXX
 SG_ DAS_w013_Cam_Watchdog : 12|1@1+ (1,0) [0|1] "" Vector__XXX
 SG_ DAS_w014_swAssert : 13|1@1+ (1,0) [0|1] "" Vector__XXX
 SG_ DAS_w015_Camera_Failsafes : 14|1@1+ (1,0) [0|1] "" Vector__XXX
 SG_ DAS_w016_aeb_e_event : 15|1@1+ (1,0) [0|1] "" Vector__XXX
 SG_ DAS_w017_Cam_Msg_MIA : 16|1@1+ (1,0) [0|1] "" Vector__XXX
 SG_ DAS_w018_ECU_Power_Issue : 17|1@1+ (1,0) [0|1] "" Vector__XXX
 SG_ DAS_w019_ECU_Stack_Overflow : 18|1@1+ (1,0) [0|1] "" Vector__XXX
 SG_ DAS_w020_ECU_checkstopError : 19|1@1+ (1,0) [0|1] "" Vector__XXX
 SG_ DAS_w021_ECU_Temperature_Issue : 20|1@1+ (1,0) [0|1] "" Vector__XXX
 SG_ DAS_w022_ECU_EEPROM_Failure : 21|1@1+ (1,0) [0|1] "" Vector__XXX
 SG_ DAS_w023_ECU_Cam_Statemismatc : 22|1@1+ (1,0) [0|1] "" Vector__XXX
 SG_ DAS_w024_ECU_Watchdog_Reset : 23|1@1+ (1,0) [0|1] "" Vector__XXX
 SG_ DAS_w025_LC_Steering_Override : 24|1@1+ (1,0) [0|1] "" Vector__XXX
 SG_ DAS_w026_ECU_timingIssue : 25|1@1+ (1,0) [0|1] "" Vector__XXX
 SG_ DAS_w027_ECU_Reset_Fault : 26|1@1+ (1,0) [0|1] "" Vector__XXX
 SG_ DAS_w028_spi_rx_error : 27|1@1+ (1,0) [0|1] "" Vector__XXX
 SG_ DAS_w029_spi_tx_error : 28|1@1+ (1,0) [0|1] "" Vector__XXX
 SG_ DAS_w030_Heater_Issue : 29|1@1+ (1,0) [0|1] "" Vector__XXX
 SG_ DAS_w031_canRxError : 30|1@1+ (1,0) [0|1] "" Vector__XXX
 SG_ DAS_w032_canTxError : 31|1@1+ (1,0) [0|1] "" Vector__XXX
 SG_ DAS_w033_gtwMia : 32|1@1+ (1,0) [0|1] "" Vector__XXX
 SG_ DAS_w034_sccmMia : 33|1@1+ (1,0) [0|1] "" Vector__XXX
 SG_ DAS_w035_espMia : 34|1@1+ (1,0) [0|1] "" Vector__XXX
 SG_ DAS_w036_bdyMia : 35|1@1+ (1,0) [0|1] "" Vector__XXX
 SG_ DAS_w037_camTacIssue : 36|1@1+ (1,0) [0|1] "" Vector__XXX
 SG_ DAS_w038_camFailure : 37|1@1+ (1,0) [0|1] "" Vector__XXX
 SG_ DAS_w039_sdm_rcm_Mia : 38|1@1+ (1,0) [0|1] "" Vector__XXX
 SG_ DAS_w040_autopilotAngleSaturated : 39|1@1+ (1,0) [0|1] "" Vector__XXX
 SG_ DAS_w041_autopilotRateSaturated : 40|1@1+ (1,0) [0|1] "" Vector__XXX
 SG_ DAS_w042_autopilotAborting : 41|1@1+ (1,0) [0|1] "" Vector__XXX
 SG_ DAS_w043_camLongRunTime : 42|1@1+ (1,0) [0|1] "" Vector__XXX
 SG_ DAS_w044_appMobileyeFailure : 43|1@1+ (1,0) [0|1] "" Vector__XXX
 SG_ DAS_w045_radMia : 44|1@1+ (1,0) [0|1] "" Vector__XXX
 SG_ DAS_w046_eepromRecordAbsent : 45|1@1+ (1,0) [0|1] "" Vector__XXX
 SG_ DAS_w047_edrEvent : 46|1@1+ (1,0) [0|1] "" Vector__XXX
 SG_ DAS_w048_DAS_Features_Disabled : 47|1@1+ (1,0) [0|1] "" Vector__XXX
 SG_ DAS_w049_eyeqVersionMismatch : 48|1@1+ (1,0) [0|1] "" Vector__XXX
 SG_ DAS_w050_aeb_event : 49|1@1+ (1,0) [0|1] "" Vector__XXX
 SG_ DAS_w051_radcEcuIssue : 50|1@1+ (1,0) [0|1] "" Vector__XXX
 SG_ DAS_w052_radcSensorIssue : 51|1@1+ (1,0) [0|1] "" Vector__XXX
 SG_ DAS_w053_radcCommIssue : 52|1@1+ (1,0) [0|1] "" Vector__XXX
 SG_ DAS_w054_camAutofix : 53|1@1+ (1,0) [0|1] "" Vector__XXX
 SG_ DAS_w055_radcVersionMismatch : 54|1@1+ (1,0) [0|1] "" Vector__XXX
 SG_ DAS_w056_diMia : 55|1@1+ (1,0) [0|1] "" Vector__XXX
 SG_ DAS_w057_mcuMia : 56|1@1+ (1,0) [0|1] "" Vector__XXX
 SG_ DAS_w058_epbMia : 57|1@1+ (1,0) [0|1] "" Vector__XXX
 SG_ DAS_w059_parkMia : 58|1@1+ (1,0) [0|1] "" Vector__XXX
 SG_ DAS_w060_fcw_event : 59|1@1+ (1,0) [0|1] "" Vector__XXX
 SG_ DAS_w061_airSuspensionMia : 60|1@1+ (1,0) [0|1] "" Vector__XXX
 SG_ DAS_w062_radcAlignment : 61|1@1+ (1,0) [0|1] "" Vector__XXX
 SG_ DAS_w063_parkVersionMismatch : 62|1@1+ (1,0) [0|1] "" Vector__XXX
 SG_ DAS_w064_epasMia : 63|1@1+ (1,0) [0|1] "" Vector__XXX

BO_ 874 DAS_warningMatrix1: 8 DAS
 SG_ DAS_w065_deserializerOvercurrent : 0|1@1+ (1,0) [0|1] "" Vector__XXX
 SG_ DAS_w066_deserializerLockLost : 1|1@1+ (1,0) [0|1] "" Vector__XXX
 SG_ DAS_w067_steeringAlignment : 2|1@1+ (1,0) [0|1] "" Vector__XXX
 SG_ DAS_w068_vlInconsistency : 3|1@1+ (1,0) [0|1] "" Vector__XXX
 SG_ DAS_w069_apcSpaceMasked : 4|1@1+ (1,0) [0|1] "" Vector__XXX
 SG_ DAS_w070_apcIncompleteCal : 5|1@1+ (1,0) [0|1] "" Vector__XXX
 SG_ DAS_w071_selfparkStarted : 6|1@1+ (1,0) [0|1] "" Vector__XXX
 SG_ DAS_w072_selfparkComplete : 7|1@1+ (1,0) [0|1] "" Vector__XXX
 SG_ DAS_w073_issueEscalatedLDW : 8|1@1+ (1,0) [0|1] "" Vector__XXX
 SG_ DAS_w074_inPathStationaryObst : 9|1@1+ (1,0) [0|1] "" Vector__XXX
 SG_ DAS_w075_scMia : 10|1@1+ (1,0) [0|1] "" Vector__XXX
 SG_ DAS_w076_mobilEyeSetC : 11|1@1+ (1,0) [0|1] "" Vector__XXX
 SG_ DAS_w077_pmmActive : 12|1@1+ (1,0) [0|1] "" Vector__XXX
 SG_ DAS_w078_pmmActive2 : 13|1@1+ (1,0) [0|1] "" Vector__XXX
 SG_ DAS_w079_edrAvailable : 14|1@1+ (1,0) [0|1] "" Vector__XXX
 SG_ DAS_w080_accFailedActivation : 15|1@1+ (1,0) [0|1] "" Vector__XXX
 SG_ DAS_w081_pmmActiveBraking : 16|1@1+ (1,0) [0|1] "" Vector__XXX
 SG_ DAS_w082_inPathFSviolation : 17|1@1+ (1,0) [0|1] "" Vector__XXX
 SG_ DAS_w083_inPathRADObject : 18|1@1+ (1,0) [0|1] "" Vector__XXX
 SG_ DAS_w084_pmmIPSO : 19|1@1+ (1,0) [0|1] "" Vector__XXX
 SG_ DAS_w085_pmmSteering : 20|1@1+ (1,0) [0|1] "" Vector__XXX
 SG_ DAS_w086_robCollision : 21|1@1+ (1,0) [0|1] "" Vector__XXX
 SG_ DAS_w087_DEPRECATED : 22|1@1+ (1,0) [0|1] "" Vector__XXX
 SG_ DAS_w088_DEPRECATED : 23|1@1+ (1,0) [0|1] "" Vector__XXX
 SG_ DAS_w089_DEPRECATED : 24|1@1+ (1,0) [0|1] "" Vector__XXX
 SG_ DAS_w090_DEPRECATED : 25|1@1+ (1,0) [0|1] "" Vector__XXX
 SG_ DAS_w091_DEPRECATED : 26|1@1+ (1,0) [0|1] "" Vector__XXX
 SG_ DAS_w092_DEPRECATED : 27|1@1+ (1,0) [0|1] "" Vector__XXX
 SG_ DAS_w093_DEPRECATED : 28|1@1+ (1,0) [0|1] "" Vector__XXX
 SG_ DAS_w094_DEPRECATED : 29|1@1+ (1,0) [0|1] "" Vector__XXX
 SG_ DAS_w095_DEPRECATED : 30|1@1+ (1,0) [0|1] "" Vector__XXX
 SG_ DAS_w096_DEPRECATED : 31|1@1+ (1,0) [0|1] "" Vector__XXX
 SG_ DAS_w097_DEPRECATED : 32|1@1+ (1,0) [0|1] "" Vector__XXX
 SG_ DAS_w098_DEPRECATED : 33|1@1+ (1,0) [0|1] "" Vector__XXX
 SG_ DAS_w099_DEPRECATED : 34|1@1+ (1,0) [0|1] "" Vector__XXX
 SG_ DAS_w100_DEPRECATED : 35|1@1+ (1,0) [0|1] "" Vector__XXX
 SG_ DAS_w101_DEPRECATED : 36|1@1+ (1,0) [0|1] "" Vector__XXX
 SG_ DAS_w102_DEPRECATED : 37|1@1+ (1,0) [0|1] "" Vector__XXX
 SG_ DAS_w103_robExperimentalAEB : 38|1@1+ (1,0) [0|1] "" Vector__XXX
 SG_ DAS_w104_DEPRECATED : 39|1@1+ (1,0) [0|1] "" Vector__XXX
 SG_ DAS_w105_DEPRECATED : 40|1@1+ (1,0) [0|1] "" Vector__XXX
 SG_ DAS_w106_torsionBarCalibrated : 41|1@1+ (1,0) [0|1] "" Vector__XXX

BO_TX_BU_ 1045 : APP;
BO_TX_BU_ 1020 : APP;
BO_TX_BU_ 1018 : APP;
BO_TX_BU_ 1043 : APP;
BO_TX_BU_ 1061 : APP;
BO_TX_BU_ 843 : APP;
BO_TX_BU_ 1353 : APP;
BO_TX_BU_ 907 : APP;
BO_TX_BU_ 605 : APP;
BO_TX_BU_ 859 : APP;
BO_TX_BU_ 809 : APP;
BO_TX_BU_ 873 : APP;
BO_TX_BU_ 1065 : APP;
BO_TX_BU_ 1097 : APP;
BO_TX_BU_ 637 : APS;
BO_TX_BU_ 992 : APS;
BO_TX_BU_ 1510 : APS;
BO_TX_BU_ 811 : APS;
BO_TX_BU_ 876 : APS;
BO_TX_BU_ 1113 : APS;
BO_TX_BU_ 848 : APS;
BO_TX_BU_ 1465 : DAS;
BO_TX_BU_ 1497 : DAS;
BO_TX_BU_ 1337 : DAS;
BO_TX_BU_ 569 : DAS;
BO_TX_BU_ 921 : DAS;
BO_TX_BU_ 905 : DAS;
BO_TX_BU_ 586 : DAS;
BO_TX_BU_ 810 : DAS;
BO_TX_BU_ 874 : DAS;

CM_ "Tesla Model 3 / Model Y CAN bus database; bus CH (chassis CAN); firmware 2025.20.8. Decoded CAN signal definitions (layout, scaling, units, value tables).";
CM_ BU_ APP "Driver assistance computer (primary)";
CM_ BU_ APS "Driver assistance computer (secondary)";
CM_ BU_ DAS "Driver assistance computer";
CM_ BU_ EPAS3S "Electric power steering (secondary)";
CM_ BU_ EPASTS "EPASTS ECU";
CM_ BU_ ESP "Electronic stability control";
CM_ BU_ GTW "Gateway";
CM_ BU_ IBST "Electric brake booster";
CM_ BU_ IDB "IDB ECU";
CM_ BU_ PARK "Parking assist sensors";
CM_ BU_ RADC "Radar";
CM_ BU_ RCM "Restraint control module";
CM_ BU_ RCM3 "RCM3 ECU";
CM_ BU_ RCU "RCU ECU";
CM_ BU_ TPMS "Tire pressure monitoring";
CM_ BU_ USM "USM ECU";
CM_ BO_ 1045 "Driver assistance computer (primary) message: backup dash cam status; frame length from the layout, not yet observed on a vehicle bus";
CM_ SG_ 1045 APP_backupDashCamFeedGood "Indicates if the backup dash cam stream is healthy.";
CM_ SG_ 1045 APP_backupDashCamFrameRate "The backup dash cam frame rate.";
CM_ BO_ 1020 "Driver assistance computer (primary) message: board temperatures; frame length from the layout, not yet observed on a vehicle bus";
CM_ SG_ 1020 APP_decisionTemperature "Rolling average of Parker and Pascal temperature.";
CM_ SG_ 1020 APP_pascalTemperature "Temperature of Autopilot GPU";
CM_ SG_ 1020 APP_parkerATemperature "Temperature of Autopilot CPU(1)";
CM_ SG_ 1020 APP_parkerBTemperature "Temperature of Autopilot CPU(1)";
CM_ SG_ 1020 APP_pascalExtTemperature "External temperature of Autopilot GPU";
CM_ SG_ 1020 APP_parkerExtTemperature "External temperature of Parker";
CM_ SG_ 1020 APP_pascalHeaterDecision "Pascal heater descision on/off";
CM_ BO_ 1018 "Driver assistance computer (primary) message: camera lux; frame length from the layout, not yet observed on a vehicle bus";
CM_ SG_ 1018 APP_mainCameraLUX "Amount of illuminance seen by the main camera; raw 255 = signal not available (SNA)";
CM_ SG_ 1018 APP_narrowCameraLUX "Driver assistance computer (primary): narrow camera LUX; raw 255 = signal not available (SNA)";
CM_ SG_ 1018 APP_fisheyeCameraLUX "Driver assistance computer (primary): fisheye camera LUX; raw 255 = signal not available (SNA)";
CM_ SG_ 1018 APP_lRepeatCameraLUX "Driver assistance computer (primary): l repeat camera LUX; raw 255 = signal not available (SNA)";
CM_ SG_ 1018 APP_rRepeatCameraLUX "Driver assistance computer (primary): r repeat camera LUX; raw 255 = signal not available (SNA)";
CM_ SG_ 1018 APP_lPillarCameraLUX "Driver assistance computer (primary): l pillar camera LUX; raw 255 = signal not available (SNA)";
CM_ SG_ 1018 APP_rPillarCameraLUX "Driver assistance computer (primary): r pillar camera LUX; raw 255 = signal not available (SNA)";
CM_ SG_ 1018 APP_backupCameraLUX "Driver assistance computer (primary): backup camera LUX; raw 255 = signal not available (SNA)";
CM_ BO_ 1043 "Driver assistance computer (primary) message: dash cam status; frame length from the layout, not yet observed on a vehicle bus";
CM_ SG_ 1043 APP_mainDashCamFeedGood "Indicates if the main dash cam stream is healthy.";
CM_ SG_ 1043 APP_mainDashCamFrameRate "The main dash cam frame rate.";
CM_ SG_ 1043 APP_lRepeatDashCamFeedGood "Indicates if the left repeater dash cam stream is healthy.";
CM_ SG_ 1043 APP_lRepeatDashCamFrameRate "The left repeater dash cam frame rate.";
CM_ SG_ 1043 APP_rRepeatDashCamFeedGood "Indicates if the right repeater dash cam stream is healthy.";
CM_ SG_ 1043 APP_rRepeatDashCamFrameRate "The right repeater dash cam frame rate.";
CM_ BO_ 1061 "Driver assistance computer (primary) message: factory summon goal; frame length from the layout, not yet observed on a vehicle bus";
CM_ SG_ 1061 APP_factoryGoalLatitude "Driver assistance computer (primary): factory goal latitude";
CM_ SG_ 1061 APP_factoryGoalLongitude "Driver assistance computer (primary): factory goal longitude";
CM_ SG_ 1061 APP_factoryGoalSpeed "Driver assistance computer (primary): factory goal speed";
CM_ BO_ 843 "Driver assistance computer (primary) message: front park assist data; frame length from the layout, not yet observed on a vehicle bus";
CM_ SG_ 843 APP_frontLeftParkAssist "Driver assistance computer (primary): front left park assist; raw 255 = signal not available (SNA)";
CM_ SG_ 843 APP_frontLeftMiddleParkAssist "Driver assistance computer (primary): front left middle park assist; raw 255 = signal not available (SNA)";
CM_ SG_ 843 APP_frontMiddleParkAssist "Driver assistance computer (primary): front middle park assist; raw 255 = signal not available (SNA)";
CM_ SG_ 843 APP_frontRightMiddleParkAssist "Driver assistance computer (primary): front right middle park assist; raw 255 = signal not available (SNA)";
CM_ SG_ 843 APP_frontRightParkAssist "Driver assistance computer (primary): front right park assist; raw 255 = signal not available (SNA)";
CM_ SG_ 843 APP_parkAssistStatus "Driver assistance computer (primary): park assist status; raw 3 = signal not available (SNA)";
CM_ SG_ 843 APP_useParkDistancesFromAP "Driver assistance computer (primary): use park distances from AP";
CM_ BO_ 1353 "Driver assistance computer (primary) message: info; frame length from the layout, not yet observed on a vehicle bus";
CM_ SG_ 1353 APP_infoIndex "Driver assistance computer (primary): info index";
CM_ SG_ 1353 APP_buildType "Driver assistance computer (primary): build type";
CM_ BO_ 907 "Driver assistance computer (primary) message: rear park assist data; frame length from the layout, not yet observed on a vehicle bus";
CM_ SG_ 907 APP_rearLeftParkAssist "Driver assistance computer (primary): rear left park assist; raw 255 = signal not available (SNA)";
CM_ SG_ 907 APP_rearLeftMiddleParkAssist "Driver assistance computer (primary): rear left middle park assist; raw 255 = signal not available (SNA)";
CM_ SG_ 907 APP_rearMiddleParkAssist "Driver assistance computer (primary): rear middle park assist; raw 255 = signal not available (SNA)";
CM_ SG_ 907 APP_rearRightMiddleParkAssist "Driver assistance computer (primary): rear right middle park assist; raw 255 = signal not available (SNA)";
CM_ SG_ 907 APP_rearRightParkAssist "Driver assistance computer (primary): rear right park assist; raw 255 = signal not available (SNA)";
CM_ BO_ 605 "Driver assistance computer (primary) message: traffic control; frame length from the layout, not yet observed on a vehicle bus";
CM_ SG_ 605 APP_tcFeatureState "The feature level state of stopping for traffic controls";
CM_ SG_ 605 APP_tcStateMachine "The traffic control state machine's internal control state.";
CM_ SG_ 605 APP_tcControlSource "The input data source for the traffic control object";
CM_ SG_ 605 APP_tcControlType "The specific type of traffic control, note not all are control worthy.";
CM_ SG_ 605 APP_tcControlDistance "The distance to the nearest critical traffic control object; raw 255 = signal not available (SNA)";
CM_ SG_ 605 APP_tcControlLightState "Driver assistance computer (primary): tc control light state";
CM_ SG_ 605 APP_tcContinuationReason "The reason the traffic control state machine entered the continue state.";
CM_ SG_ 605 APP_tcConfirmationType "The mechanism of how the driver confirmed the traffic control.";
CM_ SG_ 605 APP_tcWarningSuppressionReason "The suppression reason for the traffic control warning feature.";
CM_ SG_ 605 APP_tcUnavailableReason "The reason why the traffic control feature is currently unavailable.";
CM_ SG_ 605 APP_tcVisionLight "Whether or not the traffic light has a vision measurement.";
CM_ SG_ 605 APP_tcVisionSign "Whether or not the traffic sign has a vision measurement.";
CM_ SG_ 605 APP_tcVisionRoadMarking "Whether or not the road marking has a vision measurement.";
CM_ SG_ 605 APP_tcVisionLine "Whether or not the traffic control line has a vision measurement.";
CM_ BO_ 859 "Driver assistance computer (primary) message: vision ocs status; frame length from the layout, not yet observed on a vehicle bus";
CM_ SG_ 859 APP_visionOcsStatusChecksum "Driver assistance computer (primary): vision ocs status checksum";
CM_ SG_ 859 APP_visionOcsStateRaw "Reports classification state raw signal for front passenger from interior camera.";
CM_ SG_ 859 APP_visionOcsEmptyProbRaw "Driver assistance computer (primary): vision ocs empty prob raw; raw 255 = signal not available (SNA)";
CM_ SG_ 859 APP_visionOcsChildProbRaw "Driver assistance computer (primary): vision ocs child prob raw; raw 255 = signal not available (SNA)";
CM_ SG_ 859 APP_visionOcsAdultProbRaw "Driver assistance computer (primary): vision ocs adult prob raw; raw 255 = signal not available (SNA)";
CM_ SG_ 859 APP_visionOcsFrontPasClsVisionSt "Reports classification state of front passenger seat after Bayesian filter.";
CM_ SG_ 859 APP_visionOcsStatusCounter "Driver assistance computer (primary): vision ocs status counter";
CM_ BO_ 809 "Driver assistance computer (primary) message: warning matrix0; frame length from the layout, not yet observed on a vehicle bus";
CM_ SG_ 809 APP_w001_DEPRECATED "Driver assistance computer (primary): w001 DEPRECATED";
CM_ SG_ 809 APP_w002_ldwDisabled "Driver assistance computer (primary): w002 ldw disabled";
CM_ SG_ 809 APP_w003_isaDisabled "Driver assistance computer (primary): w003 isa disabled";
CM_ SG_ 809 APP_w004_accDisabled "Driver assistance computer (primary): w004 acc disabled";
CM_ SG_ 809 APP_w005_fcwCancelled "Driver assistance computer (primary): w005 fcw cancelled";
CM_ SG_ 809 APP_w006_aebCancelled "Driver assistance computer (primary): w006 aeb cancelled";
CM_ SG_ 809 APP_w007_ahlbDisabled "Driver assistance computer (primary): w007 ahlb disabled";
CM_ SG_ 809 APP_w008_parkDisabled "Driver assistance computer (primary): w008 park disabled";
CM_ SG_ 809 APP_w009_aebFault "Driver assistance computer (primary): w009 aeb fault";
CM_ SG_ 809 APP_w010_radcCalibIssue "Driver assistance computer (primary): w010 radc calib issue";
CM_ SG_ 809 APP_w011_scaEvent "Driver assistance computer (primary): w011 sca event";
CM_ SG_ 809 APP_w012_Cam_BootFailure "Driver assistance computer (primary): w012 cam boot failure";
CM_ SG_ 809 APP_w013_Cam_Watchdog "Driver assistance computer (primary): w013 cam watchdog";
CM_ SG_ 809 APP_w014_swAssert "Driver assistance computer (primary): w014 sw assert";
CM_ SG_ 809 APP_w015_Camera_Failsafes "Driver assistance computer (primary): w015 camera failsafes";
CM_ SG_ 809 APP_w016_aeb_e_event "Driver assistance computer (primary): w016 aeb e event";
CM_ SG_ 809 APP_w017_Cam_Msg_MIA "Driver assistance computer (primary): w017 cam msg MIA";
CM_ SG_ 809 APP_w018_ECU_Power_Issue "Driver assistance computer (primary): w018 ECU power issue";
CM_ SG_ 809 APP_w019_ECU_Stack_Overflow "Driver assistance computer (primary): w019 ECU stack overflow";
CM_ SG_ 809 APP_w020_ECU_checkstopError "Driver assistance computer (primary): w020 ECU checkstop error";
CM_ SG_ 809 APP_w021_ECU_Temperature_Issue "Driver assistance computer (primary): w021 ECU temperature issue";
CM_ SG_ 809 APP_w022_ECU_EEPROM_Failure "Driver assistance computer (primary): w022 ECU EEPROM failure";
CM_ SG_ 809 APP_w023_ECU_Cam_Statemismatc "Driver assistance computer (primary): w023 ECU cam statemismatc";
CM_ SG_ 809 APP_w024_ECU_Watchdog_Reset "Driver assistance computer (primary): w024 ECU watchdog reset";
CM_ SG_ 809 APP_w025_LC_Steering_Override "Driver assistance computer (primary): w025 LC steering override";
CM_ SG_ 809 APP_w026_ECU_timingIssue "Driver assistance computer (primary): w026 ECU timing issue";
CM_ SG_ 809 APP_w027_ECU_Reset_Fault "Driver assistance computer (primary): w027 ECU reset fault";
CM_ SG_ 809 APP_w028_spi_rx_error "Driver assistance computer (primary): w028 spi rx error";
CM_ SG_ 809 APP_w029_spi_tx_error "Driver assistance computer (primary): w029 spi tx error";
CM_ SG_ 809 APP_w030_Heater_Issue "Driver assistance computer (primary): w030 heater issue";
CM_ SG_ 809 APP_w031_canRxError "Driver assistance computer (primary): w031 can rx error";
CM_ SG_ 809 APP_w032_canTxError "Driver assistance computer (primary): w032 can tx error";
CM_ SG_ 809 APP_w033_gtwMia "Driver assistance computer (primary): w033 gtw mia";
CM_ SG_ 809 APP_w034_sccmMia "Driver assistance computer (primary): w034 sccm mia";
CM_ SG_ 809 APP_w035_espMia "Driver assistance computer (primary): w035 esp mia";
CM_ SG_ 809 APP_w036_bdyMia "Driver assistance computer (primary): w036 bdy mia";
CM_ SG_ 809 APP_w037_camTacIssue "Driver assistance computer (primary): w037 cam tac issue";
CM_ SG_ 809 APP_w038_camFailure "Driver assistance computer (primary): w038 cam failure";
CM_ SG_ 809 APP_w039_sdm_rcm_Mia "Driver assistance computer (primary): w039 sdm rcm mia";
CM_ SG_ 809 APP_w040_autopilotAngleSaturated "Driver assistance computer (primary): w040 autopilot angle saturated";
CM_ SG_ 809 APP_w041_autopilotRateSaturated "Driver assistance computer (primary): w041 autopilot rate saturated";
CM_ SG_ 809 APP_w042_autopilotAborting "Driver assistance computer (primary): w042 autopilot aborting";
CM_ SG_ 809 APP_w043_camLongRunTime "Driver assistance computer (primary): w043 cam long run time";
CM_ SG_ 809 APP_w044_appMobileyeFailure "Driver assistance computer (primary): w044 app mobileye failure";
CM_ SG_ 809 APP_w045_radMia "Driver assistance computer (primary): w045 rad mia";
CM_ SG_ 809 APP_w046_eepromRecordAbsent "Driver assistance computer (primary): w046 eeprom record absent";
CM_ SG_ 809 APP_w047_edrEvent "Driver assistance computer (primary): w047 edr event";
CM_ SG_ 809 APP_w048_APP_Features_Disabled "Driver assistance computer (primary): w048 APP features disabled";
CM_ SG_ 809 APP_w049_eyeqVersionMismatch "Driver assistance computer (primary): w049 eyeq version mismatch";
CM_ SG_ 809 APP_w050_aeb_event "Driver assistance computer (primary): w050 aeb event";
CM_ SG_ 809 APP_w051_radcEcuIssue "Driver assistance computer (primary): w051 radc ecu issue";
CM_ SG_ 809 APP_w052_radcSensorIssue "Driver assistance computer (primary): w052 radc sensor issue";
CM_ SG_ 809 APP_w053_radcCommIssue "Driver assistance computer (primary): w053 radc comm issue";
CM_ SG_ 809 APP_w054_camAutofix "Driver assistance computer (primary): w054 cam autofix";
CM_ SG_ 809 APP_w055_radcVersionMismatch "Driver assistance computer (primary): w055 radc version mismatch";
CM_ SG_ 809 APP_w056_diMia "Driver assistance computer (primary): w056 di mia";
CM_ SG_ 809 APP_w057_mcuMia "Driver assistance computer (primary): w057 mcu mia";
CM_ SG_ 809 APP_w058_epbMia "Driver assistance computer (primary): w058 epb mia";
CM_ SG_ 809 APP_w059_parkMia "Driver assistance computer (primary): w059 park mia";
CM_ SG_ 809 APP_w060_fcw_event "Driver assistance computer (primary): w060 fcw event";
CM_ SG_ 809 APP_w061_airSuspensionMia "Driver assistance computer (primary): w061 air suspension mia";
CM_ SG_ 809 APP_w062_radcAlignment "Driver assistance computer (primary): w062 radc alignment";
CM_ SG_ 809 APP_w063_parkVersionMismatch "Driver assistance computer (primary): w063 park version mismatch";
CM_ SG_ 809 APP_w064_epasMia "Driver assistance computer (primary): w064 epas mia";
CM_ BO_ 873 "Driver assistance computer (primary) message: warning matrix1; frame length from the layout, not yet observed on a vehicle bus";
CM_ SG_ 873 APP_w065_deserializerOvercurrent "Driver assistance computer (primary): w065 deserializer overcurrent";
CM_ SG_ 873 APP_w066_deserializerLockLost "Driver assistance computer (primary): w066 deserializer lock lost";
CM_ SG_ 873 APP_w067_steeringAlignment "Driver assistance computer (primary): w067 steering alignment";
CM_ SG_ 873 APP_w068_vlInconsistency "Driver assistance computer (primary): w068 vl inconsistency";
CM_ SG_ 873 APP_w069_apcSpaceMasked "Driver assistance computer (primary): w069 apc space masked";
CM_ SG_ 873 APP_w070_apcIncompleteCal "Driver assistance computer (primary): w070 apc incomplete cal";
CM_ SG_ 873 APP_w071_selfparkStarted "Driver assistance computer (primary): w071 selfpark started";
CM_ SG_ 873 APP_w072_selfparkComplete "Driver assistance computer (primary): w072 selfpark complete";
CM_ SG_ 873 APP_w073_issueEscalatedLDW "Driver assistance computer (primary): w073 issue escalated LDW";
CM_ SG_ 873 APP_w074_inPathStationaryObst "Driver assistance computer (primary): w074 in path stationary obst";
CM_ SG_ 873 APP_w075_scMia "Driver assistance computer (primary): w075 sc mia";
CM_ SG_ 873 APP_w076_mobilEyeSetC "Driver assistance computer (primary): w076 mobil eye set c";
CM_ SG_ 873 APP_w077_pmmActive "Driver assistance computer (primary): w077 pmm active";
CM_ SG_ 873 APP_w078_pmmActive2 "Driver assistance computer (primary): w078 pmm active2";
CM_ SG_ 873 APP_w079_edrAvailable "Driver assistance computer (primary): w079 edr available";
CM_ SG_ 873 APP_w080_accFailedActivation "Driver assistance computer (primary): w080 acc failed activation";
CM_ SG_ 873 APP_w081_pmmActiveBraking "Driver assistance computer (primary): w081 pmm active braking";
CM_ SG_ 873 APP_w082_inPathFSviolation "Driver assistance computer (primary): w082 in path f sviolation";
CM_ SG_ 873 APP_w083_inPathRADObject "Driver assistance computer (primary): w083 in path RAD object";
CM_ SG_ 873 APP_w084_pmmIPSO "Driver assistance computer (primary): w084 pmm IPSO";
CM_ SG_ 873 APP_w085_pmmSteering "Driver assistance computer (primary): w085 pmm steering";
CM_ SG_ 873 APP_w086_robCollision "Driver assistance computer (primary): w086 rob collision";
CM_ SG_ 873 APP_w087_DEPRECATED "Driver assistance computer (primary): w087 DEPRECATED";
CM_ SG_ 873 APP_w088_DEPRECATED "Driver assistance computer (primary): w088 DEPRECATED";
CM_ SG_ 873 APP_w089_DEPRECATED "Driver assistance computer (primary): w089 DEPRECATED";
CM_ SG_ 873 APP_w090_DEPRECATED "Driver assistance computer (primary): w090 DEPRECATED";
CM_ SG_ 873 APP_w091_DEPRECATED "Driver assistance computer (primary): w091 DEPRECATED";
CM_ SG_ 873 APP_w092_DEPRECATED "Driver assistance computer (primary): w092 DEPRECATED";
CM_ SG_ 873 APP_w093_DEPRECATED "Driver assistance computer (primary): w093 DEPRECATED";
CM_ SG_ 873 APP_w094_DEPRECATED "Driver assistance computer (primary): w094 DEPRECATED";
CM_ SG_ 873 APP_w095_DEPRECATED "Driver assistance computer (primary): w095 DEPRECATED";
CM_ SG_ 873 APP_w096_DEPRECATED "Driver assistance computer (primary): w096 DEPRECATED";
CM_ SG_ 873 APP_w097_DEPRECATED "Driver assistance computer (primary): w097 DEPRECATED";
CM_ SG_ 873 APP_w098_DEPRECATED "Driver assistance computer (primary): w098 DEPRECATED";
CM_ SG_ 873 APP_w099_DEPRECATED "Driver assistance computer (primary): w099 DEPRECATED";
CM_ SG_ 873 APP_w100_DEPRECATED "Driver assistance computer (primary): w100 DEPRECATED";
CM_ SG_ 873 APP_w101_DEPRECATED "Driver assistance computer (primary): w101 DEPRECATED";
CM_ SG_ 873 APP_w102_DEPRECATED "Driver assistance computer (primary): w102 DEPRECATED";
CM_ SG_ 873 APP_w103_robExperimentalAEB "Driver assistance computer (primary): w103 rob experimental AEB";
CM_ SG_ 873 APP_w104_DEPRECATED "Driver assistance computer (primary): w104 DEPRECATED";
CM_ SG_ 873 APP_w105_DEPRECATED "Driver assistance computer (primary): w105 DEPRECATED";
CM_ SG_ 873 APP_w106_torsionBarOffset "Driver assistance computer (primary): w106 torsion bar offset";
CM_ BO_ 1065 "Driver assistance computer (primary) message: warning matrix2; frame length from the layout, not yet observed on a vehicle bus";
CM_ SG_ 1065 APP_w129_mainCamExtNotCal "Driver assistance computer (primary): w129 main cam ext not cal";
CM_ SG_ 1065 APP_w130_narrowCamExtNotCal "Driver assistance computer (primary): w130 narrow cam ext not cal";
CM_ SG_ 1065 APP_w131_mainCamCalSaved "Driver assistance computer (primary): w131 main cam cal saved";
CM_ SG_ 1065 APP_w132_narrowCamCalSaved "Driver assistance computer (primary): w132 narrow cam cal saved";
CM_ SG_ 1065 APP_w133_mainCamInitFault "Driver assistance computer (primary): w133 main cam init fault";
CM_ SG_ 1065 APP_w134_narrowCamInitFault "Driver assistance computer (primary): w134 narrow cam init fault";
CM_ SG_ 1065 APP_w135_fisheyeCamInitFault "Driver assistance computer (primary): w135 fisheye cam init fault";
CM_ SG_ 1065 APP_w136_lPillarCamInitFault "Driver assistance computer (primary): w136 l pillar cam init fault";
CM_ SG_ 1065 APP_w137_rPillarCamInitFault "Driver assistance computer (primary): w137 r pillar cam init fault";
CM_ SG_ 1065 APP_w138_lRepeatCamInitFault "Driver assistance computer (primary): w138 l repeat cam init fault";
CM_ SG_ 1065 APP_w139_rRepeatCamInitFault "Driver assistance computer (primary): w139 r repeat cam init fault";
CM_ SG_ 1065 APP_w140_backupCamInitFault "Driver assistance computer (primary): w140 backup cam init fault";
CM_ SG_ 1065 APP_w141_ECU_Thermal_Issue "Driver assistance computer (primary): w141 ECU thermal issue";
CM_ SG_ 1065 APP_w142_fwdCamPitchProblem "Driver assistance computer (primary): w142 fwd cam pitch problem";
CM_ SG_ 1065 APP_w143_IDF_event "Driver assistance computer (primary): w143 IDF event";
CM_ SG_ 1065 APP_w144_fanctrldError "Driver assistance computer (primary): w144 fanctrld error";
CM_ SG_ 1065 APP_w145_camSelfCalIssue "Driver assistance computer (primary): w145 cam self cal issue";
CM_ SG_ 1065 APP_w146_telemetryProblem "Driver assistance computer (primary): w146 telemetry problem";
CM_ SG_ 1065 APP_w147_selfieCamInitFault "Driver assistance computer (primary): w147 selfie cam init fault";
CM_ SG_ 1065 APP_w148_overlayActive "Driver assistance computer (primary): w148 overlay active";
CM_ SG_ 1065 APP_w149_diskFull "Driver assistance computer (primary): w149 disk full";
CM_ SG_ 1065 APP_w150_diMiaPartyBus "Driver assistance computer (primary): w150 di mia party bus";
CM_ SG_ 1065 APP_w151_epasMiaPartyBus "Driver assistance computer (primary): w151 epas mia party bus";
CM_ SG_ 1065 APP_w152_espMiaPartyBus "Driver assistance computer (primary): w152 esp mia party bus";
CM_ SG_ 1065 APP_w153_rcmMiaPartyBus "Driver assistance computer (primary): w153 rcm mia party bus";
CM_ SG_ 1065 APP_w154_vcleftMiaPartyBus "Driver assistance computer (primary): w154 vcleft mia party bus";
CM_ SG_ 1065 APP_w155_vcrightMiaPartyBus "Driver assistance computer (primary): w155 vcright mia party bus";
CM_ SG_ 1065 APP_w156_epblMiaVehBus "Driver assistance computer (primary): w156 epbl mia veh bus";
CM_ SG_ 1065 APP_w157_sccmMiaVehBus "Driver assistance computer (primary): w157 sccm mia veh bus";
CM_ SG_ 1065 APP_w158_vcfrontMiaVehBus "Driver assistance computer (primary): w158 vcfront mia veh bus";
CM_ SG_ 1065 APP_w159_vcleftMiaVehBus "Driver assistance computer (primary): w159 vcleft mia veh bus";
CM_ SG_ 1065 APP_w160_vcrightMiaVehBus "Driver assistance computer (primary): w160 vcright mia veh bus";
CM_ SG_ 1065 APP_w161_backupCameraUnavailable "Driver assistance computer (primary): w161 backup camera unavailable";
CM_ SG_ 1065 APP_w162_mainCameraTypeError "Driver assistance computer (primary): w162 main camera type error";
CM_ SG_ 1065 APP_w163_narrowCameraTypeError "Driver assistance computer (primary): w163 narrow camera type error";
CM_ SG_ 1065 APP_w164_fisheyeCameraTypeError "Driver assistance computer (primary): w164 fisheye camera type error";
CM_ SG_ 1065 APP_w165_lPillarCameraTypeError "Driver assistance computer (primary): w165 l pillar camera type error";
CM_ SG_ 1065 APP_w166_rPillarCameraTypeError "Driver assistance computer (primary): w166 r pillar camera type error";
CM_ SG_ 1065 APP_w167_lRepeatCameraTypeError "Driver assistance computer (primary): w167 l repeat camera type error";
CM_ SG_ 1065 APP_w168_rRepeatCameraTypeError "Driver assistance computer (primary): w168 r repeat camera type error";
CM_ SG_ 1065 APP_w169_backupCameraTypeError "Driver assistance computer (primary): w169 backup camera type error";
CM_ SG_ 1065 APP_w170_selfieCameraTypeError "Driver assistance computer (primary): w170 selfie camera type error";
CM_ SG_ 1065 APP_w171_appHighCoolantFlowReq "Driver assistance computer (primary): w171 app high coolant flow req";
CM_ SG_ 1065 APP_w172_fisheyeCamExtNotCal "Driver assistance computer (primary): w172 fisheye cam ext not cal";
CM_ SG_ 1065 APP_w173_lPillarCamExtNotCal "Driver assistance computer (primary): w173 l pillar cam ext not cal";
CM_ SG_ 1065 APP_w174_rPillarCamExtNotCal "Driver assistance computer (primary): w174 r pillar cam ext not cal";
CM_ SG_ 1065 APP_w175_lRepeatCamExtNotCal "Driver assistance computer (primary): w175 l repeat cam ext not cal";
CM_ SG_ 1065 APP_w176_rRepeatCamExtNotCal "Driver assistance computer (primary): w176 r repeat cam ext not cal";
CM_ SG_ 1065 APP_w177_fisheyeCamCalSaved "Driver assistance computer (primary): w177 fisheye cam cal saved";
CM_ SG_ 1065 APP_w178_lPillarCamCalSaved "Driver assistance computer (primary): w178 l pillar cam cal saved";
CM_ SG_ 1065 APP_w179_rPillarCamCalSaved "Driver assistance computer (primary): w179 r pillar cam cal saved";
CM_ SG_ 1065 APP_w180_lRepeatCamCalSaved "Driver assistance computer (primary): w180 l repeat cam cal saved";
CM_ SG_ 1065 APP_w181_rRepeatCamCalSaved "Driver assistance computer (primary): w181 r repeat cam cal saved";
CM_ SG_ 1065 APP_w182_mainCameraStreamExit "Driver assistance computer (primary): w182 main camera stream exit";
CM_ SG_ 1065 APP_w183_narrowCameraStreamExit "Driver assistance computer (primary): w183 narrow camera stream exit";
CM_ SG_ 1065 APP_w184_fisheyeCameraStreamExit "Driver assistance computer (primary): w184 fisheye camera stream exit";
CM_ SG_ 1065 APP_w185_lPillarCameraStreamExit "Driver assistance computer (primary): w185 l pillar camera stream exit";
CM_ SG_ 1065 APP_w186_rPillarCameraStreamExit "Driver assistance computer (primary): w186 r pillar camera stream exit";
CM_ SG_ 1065 APP_w187_lRepeatCameraStreamExit "Driver assistance computer (primary): w187 l repeat camera stream exit";
CM_ SG_ 1065 APP_w188_rRepeatCameraStreamExit "Driver assistance computer (primary): w188 r repeat camera stream exit";
CM_ SG_ 1065 APP_w189_backupCameraStreamExit "Driver assistance computer (primary): w189 backup camera stream exit";
CM_ SG_ 1065 APP_w190_selfieCameraStreamExit "Driver assistance computer (primary): w190 selfie camera stream exit";
CM_ SG_ 1065 APP_w191_autopilotAborting "Driver assistance computer (primary): w191 autopilot aborting";
CM_ SG_ 1065 APP_w192_emergencySpeakerFail "Driver assistance computer (primary): w192 emergency speaker fail";
CM_ BO_ 1097 "Driver assistance computer (primary) message: warning matrix4; frame length from the layout, not yet observed on a vehicle bus";
CM_ SG_ 1097 APP_w257_brakeJerkEvent "Driver assistance computer (primary): w257 brake jerk event";
CM_ SG_ 1097 APP_w258_aebEvent "Driver assistance computer (primary): w258 aeb event";
CM_ SG_ 1097 APP_w259_aebOverrideEvent "Driver assistance computer (primary): w259 aeb override event";
CM_ SG_ 1097 APP_w260_collisionWarningEvent "Driver assistance computer (primary): w260 collision warning event";
CM_ SG_ 1097 APP_w261_pcieHardwareErrors "Driver assistance computer (primary): w261 pcie hardware errors";
CM_ SG_ 1097 APP_w262_apeCalibMode "Driver assistance computer (primary): w262 ape calib mode";
CM_ SG_ 1097 APP_w263_lssAbort "Driver assistance computer (primary): w263 lss abort";
CM_ SG_ 1097 APP_w264_lssFault "Driver assistance computer (primary): w264 lss fault";
CM_ SG_ 1097 APP_w265_drvOnNavUnavailable "Driver assistance computer (primary): w265 drv on nav unavailable";
CM_ SG_ 1097 APP_w266_visionScheduleFallback "Driver assistance computer (primary): w266 vision schedule fallback";
CM_ SG_ 1097 APP_w267_benchtopEcu "Driver assistance computer (primary): w267 benchtop ecu";
CM_ SG_ 1097 APP_w268_backupCamExtNotCal "Driver assistance computer (primary): w268 backup cam ext not cal";
CM_ SG_ 1097 APP_w269_autopilotLimited "Driver assistance computer (primary): w269 autopilot limited";
CM_ SG_ 1097 APP_w270_blindspotRestricted "Driver assistance computer (primary): w270 blindspot restricted";
CM_ SG_ 1097 APP_w271_laneChangeAborted "Driver assistance computer (primary): w271 lane change aborted";
CM_ SG_ 1097 APP_w272_laneChangeUnavailable "Driver assistance computer (primary): w272 lane change unavailable";
CM_ SG_ 1097 APP_w273_lssEvent "Driver assistance computer (primary): w273 lss event";
CM_ SG_ 1097 APP_w274_mainCameraStreamErr "Driver assistance computer (primary): w274 main camera stream err";
CM_ SG_ 1097 APP_w275_narrowCameraStreamErr "Driver assistance computer (primary): w275 narrow camera stream err";
CM_ SG_ 1097 APP_w276_fisheyeCameraStreamErr "Driver assistance computer (primary): w276 fisheye camera stream err";
CM_ SG_ 1097 APP_w277_lPillarCameraStreamErr "Driver assistance computer (primary): w277 l pillar camera stream err";
CM_ SG_ 1097 APP_w278_rPillarCameraStreamErr "Driver assistance computer (primary): w278 r pillar camera stream err";
CM_ SG_ 1097 APP_w279_lRepeatCameraStreamErr "Driver assistance computer (primary): w279 l repeat camera stream err";
CM_ SG_ 1097 APP_w280_rRepeatCameraStreamErr "Driver assistance computer (primary): w280 r repeat camera stream err";
CM_ SG_ 1097 APP_w281_backupCameraStreamErr "Driver assistance computer (primary): w281 backup camera stream err";
CM_ SG_ 1097 APP_w282_selfieCameraStreamErr "Driver assistance computer (primary): w282 selfie camera stream err";
CM_ SG_ 1097 APP_w283_enhancedSummonAbort "Driver assistance computer (primary): w283 enhanced summon abort";
CM_ SG_ 1097 APP_w284_gpsAntennaDisconnected "Driver assistance computer (primary): w284 gps antenna disconnected";
CM_ SG_ 1097 APP_w285_gpsFaultReset "Driver assistance computer (primary): w285 gps fault reset";
CM_ SG_ 1097 APP_w286_gpsComIssue "Driver assistance computer (primary): w286 gps com issue";
CM_ SG_ 1097 APP_w287_gpsFusionStatus "Driver assistance computer (primary): w287 gps fusion status";
CM_ SG_ 1097 APP_w288_trafficLightWarning "Driver assistance computer (primary): w288 traffic light warning";
CM_ SG_ 1097 APP_w289_dramCorrEccErrors "Driver assistance computer (primary): w289 dram corr ecc errors";
CM_ SG_ 1097 APP_w290_dramUncorrEccErrors "Driver assistance computer (primary): w290 dram uncorr ecc errors";
CM_ SG_ 1097 APP_w291_stopSignWarning "Driver assistance computer (primary): w291 stop sign warning";
CM_ SG_ 1097 APP_w293_mainCameraSyncFailed "Driver assistance computer (primary): w293 main camera sync failed";
CM_ SG_ 1097 APP_w294_narrowCameraSyncFailed "Driver assistance computer (primary): w294 narrow camera sync failed";
CM_ SG_ 1097 APP_w295_fisheyeCameraSyncFailed "Driver assistance computer (primary): w295 fisheye camera sync failed";
CM_ SG_ 1097 APP_w296_lPillarCameraSyncFailed "Driver assistance computer (primary): w296 l pillar camera sync failed";
CM_ SG_ 1097 APP_w297_rPillarCameraSyncFailed "Driver assistance computer (primary): w297 r pillar camera sync failed";
CM_ SG_ 1097 APP_w298_lRepeatCameraSyncFailed "Driver assistance computer (primary): w298 l repeat camera sync failed";
CM_ SG_ 1097 APP_w299_rRepeatCameraSyncFailed "Driver assistance computer (primary): w299 r repeat camera sync failed";
CM_ SG_ 1097 APP_w300_backupCameraSyncFailed "Driver assistance computer (primary): w300 backup camera sync failed";
CM_ SG_ 1097 APP_w301_selfieCameraSyncFailed "Driver assistance computer (primary): w301 selfie camera sync failed";
CM_ SG_ 1097 APP_w302_vcfrontMiaPartyBus "Driver assistance computer (primary): w302 vcfront mia party bus";
CM_ SG_ 1097 APP_w303_imuIrational "Driver assistance computer (primary): w303 imu irational";
CM_ SG_ 1097 APP_w304_lssCamBlockedStatus "Driver assistance computer (primary): w304 lss cam blocked status";
CM_ SG_ 1097 APP_w305_lssCamStreamExit "Driver assistance computer (primary): w305 lss cam stream exit";
CM_ SG_ 1097 APP_w306_lssUltrasonicsBlocked "Driver assistance computer (primary): w306 lss ultrasonics blocked";
CM_ SG_ 1097 APP_w307_lssTurnSignalFault "Driver assistance computer (primary): w307 lss turn signal fault";
CM_ SG_ 1097 APP_w308_iboosterMia "Driver assistance computer (primary): w308 ibooster mia";
CM_ SG_ 1097 APP_w309_selfieDisabledOnCar "Driver assistance computer (primary): w309 selfie disabled on car";
CM_ SG_ 1097 APP_w310_eth0FrameErrors "Driver assistance computer (primary): w310 eth0 frame errors";
CM_ SG_ 1097 APP_w311_eth1FrameErrors "Driver assistance computer (primary): w311 eth1 frame errors";
CM_ SG_ 1097 APP_w312_mainCamTypeMismatch "Driver assistance computer (primary): w312 main cam type mismatch";
CM_ SG_ 1097 APP_w313_narrowCamTypeMismatch "Driver assistance computer (primary): w313 narrow cam type mismatch";
CM_ SG_ 1097 APP_w314_fisheyeCamTypeMismatch "Driver assistance computer (primary): w314 fisheye cam type mismatch";
CM_ SG_ 1097 APP_w315_lPillarCamTypeMismatch "Driver assistance computer (primary): w315 l pillar cam type mismatch";
CM_ SG_ 1097 APP_w316_rPillarCamTypeMismatch "Driver assistance computer (primary): w316 r pillar cam type mismatch";
CM_ SG_ 1097 APP_w317_lRepeatCamTypeMismatch "Driver assistance computer (primary): w317 l repeat cam type mismatch";
CM_ SG_ 1097 APP_w318_rRepeatCamTypeMismatch "Driver assistance computer (primary): w318 r repeat cam type mismatch";
CM_ SG_ 1097 APP_w319_backupCamTypeMismatch "Driver assistance computer (primary): w319 backup cam type mismatch";
CM_ SG_ 1097 APP_w320_selfieCamTypeMismatch "Driver assistance computer (primary): w320 selfie cam type mismatch";
CM_ BO_ 637 "Driver assistance computer (secondary) message: eac monitor; frame length from the layout, not yet observed on a vehicle bus";
CM_ SG_ 637 APS_eacAllow "Indicates whether or not the Aurix external angle control (EAC) monitor logic currently allows angle control for Autopilot functions; raw 3 = signal not available (SNA)";
CM_ SG_ 637 APS_eacMonitorCounter "Driver assistance computer (secondary): eac monitor counter";
CM_ SG_ 637 APS_eacMonitorChecksum "Driver assistance computer (secondary): eac monitor checksum";
CM_ BO_ 992 "Driver assistance computer (secondary) message: power state inputs; frame length from the layout, not yet observed on a vehicle bus";
CM_ SG_ 992 APS_A_lowPowerRequest "Indicates Autopilot Secondary Processor (APS) low power state request presence.";
CM_ SG_ 992 APS_A_lowPowerRequestor "Indicates who initiated the Autopilot Secondary Processor (APS) low power request.";
CM_ SG_ 992 APS_A_forcePowerOffRequest "Driver assistance computer (secondary): a force power off request";
CM_ SG_ 992 APS_B_lowPowerRequest "Indicates Autopilot Secondary Processor (APS) low power state request presence.";
CM_ SG_ 992 APS_B_lowPowerRequestor "Indicates who initiated the Autopilot Secondary Processor (APS) low power request.";
CM_ SG_ 992 APS_B_forcePowerOffRequest "Driver assistance computer (secondary): b force power off request";
CM_ BO_ 1510 "Driver assistance computer (secondary) message: sys health; frame length from the layout, not yet observed on a vehicle bus";
CM_ SG_ 1510 APS_A_cam12v0Voltage "Measures the 12V camera power supply voltage for Autopilot Secondary Processor (APS) Turbo A; raw 4095 = signal not available (SNA)";
CM_ SG_ 1510 APS_B_cam12v0Voltage "Measures the 12V camera power supply voltage for Autopilot Secondary Processor (APS) Turbo B; raw 4095 = signal not available (SNA)";
CM_ SG_ 1510 APS_A_turboMaxTemperature "Reports the maximum temperature recorded by Autopilot Secondary Processor (APS) unit A; raw 128 = signal not available (SNA)";
CM_ SG_ 1510 APS_A_turboProbeType "Driver assistance computer (secondary): a turbo probe type; raw 63 = signal not available (SNA)";
CM_ SG_ 1510 APS_B_turboMaxTemperature "Reports the maximum temperature recorded by Autopilot Secondary Processor (APS) unit B; raw 128 = signal not available (SNA)";
CM_ SG_ 1510 APS_B_turboProbeType "Driver assistance computer (secondary): b turbo probe type; raw 63 = signal not available (SNA)";
CM_ BO_ 811 "Driver assistance computer (secondary) message: warning matrix0; frame length from the layout, not yet observed on a vehicle bus";
CM_ SG_ 811 APS_w001_DEPRECATED "Driver assistance computer (secondary): w001 DEPRECATED";
CM_ SG_ 811 APS_w002_ldwDisabled "Driver assistance computer (secondary): w002 ldw disabled";
CM_ SG_ 811 APS_w003_isaDisabled "Driver assistance computer (secondary): w003 isa disabled";
CM_ SG_ 811 APS_w004_accDisabled "Driver assistance computer (secondary): w004 acc disabled";
CM_ SG_ 811 APS_w005_fcwCancelled "Driver assistance computer (secondary): w005 fcw cancelled";
CM_ SG_ 811 APS_w006_aebCancelled "Driver assistance computer (secondary): w006 aeb cancelled";
CM_ SG_ 811 APS_w007_ahlbDisabled "Driver assistance computer (secondary): w007 ahlb disabled";
CM_ SG_ 811 APS_w008_parkDisabled "Driver assistance computer (secondary): w008 park disabled";
CM_ SG_ 811 APS_w009_aebFault "Driver assistance computer (secondary): w009 aeb fault";
CM_ SG_ 811 APS_w010_radcCalibIssue "Driver assistance computer (secondary): w010 radc calib issue";
CM_ SG_ 811 APS_w011_scaEvent "Driver assistance computer (secondary): w011 sca event";
CM_ SG_ 811 APS_w012_Cam_BootFailure "Driver assistance computer (secondary): w012 cam boot failure";
CM_ SG_ 811 APS_w013_Cam_Watchdog "Driver assistance computer (secondary): w013 cam watchdog";
CM_ SG_ 811 APS_w014_swAssert "Driver assistance computer (secondary): w014 sw assert";
CM_ SG_ 811 APS_w015_Camera_Failsafes "Driver assistance computer (secondary): w015 camera failsafes";
CM_ SG_ 811 APS_w016_aeb_e_event "Driver assistance computer (secondary): w016 aeb e event";
CM_ SG_ 811 APS_w017_Cam_Msg_MIA "Driver assistance computer (secondary): w017 cam msg MIA";
CM_ SG_ 811 APS_w018_ECU_Power_Issue "Driver assistance computer (secondary): w018 ECU power issue";
CM_ SG_ 811 APS_w019_ECU_Stack_Overflow "Driver assistance computer (secondary): w019 ECU stack overflow";
CM_ SG_ 811 APS_w020_ECU_checkstopError "Driver assistance computer (secondary): w020 ECU checkstop error";
CM_ SG_ 811 APS_w021_ECU_Temperature_Issue "Driver assistance computer (secondary): w021 ECU temperature issue";
CM_ SG_ 811 APS_w022_ECU_EEPROM_Failure "Driver assistance computer (secondary): w022 ECU EEPROM failure";
CM_ SG_ 811 APS_w023_ECU_Cam_Statemismatc "Driver assistance computer (secondary): w023 ECU cam statemismatc";
CM_ SG_ 811 APS_w024_ECU_Watchdog_Reset "Driver assistance computer (secondary): w024 ECU watchdog reset";
CM_ SG_ 811 APS_w025_LC_Steering_Override "Driver assistance computer (secondary): w025 LC steering override";
CM_ SG_ 811 APS_w026_ECU_timingIssue "Driver assistance computer (secondary): w026 ECU timing issue";
CM_ SG_ 811 APS_w027_ECU_Reset_Fault "Driver assistance computer (secondary): w027 ECU reset fault";
CM_ SG_ 811 APS_w028_spi_rx_error "Driver assistance computer (secondary): w028 spi rx error";
CM_ SG_ 811 APS_w029_spi_tx_error "Driver assistance computer (secondary): w029 spi tx error";
CM_ SG_ 811 APS_w030_Heater_Issue "Driver assistance computer (secondary): w030 heater issue";
CM_ SG_ 811 APS_w031_canRxError "Driver assistance computer (secondary): w031 can rx error";
CM_ SG_ 811 APS_w032_canTxError "Driver assistance computer (secondary): w032 can tx error";
CM_ SG_ 811 APS_w033_gtwMia "Driver assistance computer (secondary): w033 gtw mia";
CM_ SG_ 811 APS_w034_sccmMia "Driver assistance computer (secondary): w034 sccm mia";
CM_ SG_ 811 APS_w035_espMia "Driver assistance computer (secondary): w035 esp mia";
CM_ SG_ 811 APS_w036_bdyMia "Driver assistance computer (secondary): w036 bdy mia";
CM_ SG_ 811 APS_w037_camTacIssue "Driver assistance computer (secondary): w037 cam tac issue";
CM_ SG_ 811 APS_w038_camFailure "Driver assistance computer (secondary): w038 cam failure";
CM_ SG_ 811 APS_w039_sdm_rcm_Mia "Driver assistance computer (secondary): w039 sdm rcm mia";
CM_ SG_ 811 APS_w040_autopilotAngleSaturated "Driver assistance computer (secondary): w040 autopilot angle saturated";
CM_ SG_ 811 APS_w041_autopilotRateSaturated "Driver assistance computer (secondary): w041 autopilot rate saturated";
CM_ SG_ 811 APS_w042_autopilotAborting "Driver assistance computer (secondary): w042 autopilot aborting";
CM_ SG_ 811 APS_w043_camLongRunTime "Driver assistance computer (secondary): w043 cam long run time";
CM_ SG_ 811 APS_w044_appMobileyeFailure "Driver assistance computer (secondary): w044 app mobileye failure";
CM_ SG_ 811 APS_w045_radMia "Driver assistance computer (secondary): w045 rad mia";
CM_ SG_ 811 APS_w046_eepromRecordAbsent "Driver assistance computer (secondary): w046 eeprom record absent";
CM_ SG_ 811 APS_w047_edrEvent "Driver assistance computer (secondary): w047 edr event";
CM_ SG_ 811 APS_w048_DAS_Features_Disabled "Driver assistance computer (secondary): w048 DAS features disabled";
CM_ SG_ 811 APS_w049_eyeqVersionMismatch "Driver assistance computer (secondary): w049 eyeq version mismatch";
CM_ SG_ 811 APS_w050_aeb_event "Driver assistance computer (secondary): w050 aeb event";
CM_ SG_ 811 APS_w051_radcEcuIssue "Driver assistance computer (secondary): w051 radc ecu issue";
CM_ SG_ 811 APS_w052_radcSensorIssue "Driver assistance computer (secondary): w052 radc sensor issue";
CM_ SG_ 811 APS_w053_radcCommIssue "Driver assistance computer (secondary): w053 radc comm issue";
CM_ SG_ 811 APS_w054_camAutofix "Driver assistance computer (secondary): w054 cam autofix";
CM_ SG_ 811 APS_w055_radcVersionMismatch "Driver assistance computer (secondary): w055 radc version mismatch";
CM_ SG_ 811 APS_w056_diMia "Driver assistance computer (secondary): w056 di mia";
CM_ SG_ 811 APS_w057_mcuMia "Driver assistance computer (secondary): w057 mcu mia";
CM_ SG_ 811 APS_w058_epbMia "Driver assistance computer (secondary): w058 epb mia";
CM_ SG_ 811 APS_w059_parkMia "Driver assistance computer (secondary): w059 park mia";
CM_ SG_ 811 APS_w060_fcw_event "Driver assistance computer (secondary): w060 fcw event";
CM_ SG_ 811 APS_w061_tasMia "Driver assistance computer (secondary): w061 tas mia";
CM_ SG_ 811 APS_w062_radcAlignment "Driver assistance computer (secondary): w062 radc alignment";
CM_ SG_ 811 APS_w063_parkVersionMismatch "Driver assistance computer (secondary): w063 park version mismatch";
CM_ SG_ 811 APS_w064_epasMia "Driver assistance computer (secondary): w064 epas mia";
CM_ BO_ 876 "Driver assistance computer (secondary) message: warning matrix1; frame length from the layout, not yet observed on a vehicle bus";
CM_ SG_ 876 APS_w065_deserializerOvercurrent "Driver assistance computer (secondary): w065 deserializer overcurrent";
CM_ SG_ 876 APS_w066_deserializerLockLost "Driver assistance computer (secondary): w066 deserializer lock lost";
CM_ SG_ 876 APS_w067_steeringAlignment "Driver assistance computer (secondary): w067 steering alignment";
CM_ SG_ 876 APS_w068_vlInconsistency "Driver assistance computer (secondary): w068 vl inconsistency";
CM_ SG_ 876 APS_w069_apcSpaceMasked "Driver assistance computer (secondary): w069 apc space masked";
CM_ SG_ 876 APS_w070_apcIncompleteCal "Driver assistance computer (secondary): w070 apc incomplete cal";
CM_ SG_ 876 APS_w071_selfparkStarted "Driver assistance computer (secondary): w071 selfpark started";
CM_ SG_ 876 APS_w072_selfparkComplete "Driver assistance computer (secondary): w072 selfpark complete";
CM_ SG_ 876 APS_w073_issueEscalatedLDW "Driver assistance computer (secondary): w073 issue escalated LDW";
CM_ SG_ 876 APS_w074_inPathStationaryObst "Driver assistance computer (secondary): w074 in path stationary obst";
CM_ SG_ 876 APS_w075_scMia "Driver assistance computer (secondary): w075 sc mia";
CM_ SG_ 876 APS_w076_mobilEyeSetC "Driver assistance computer (secondary): w076 mobil eye set c";
CM_ SG_ 876 APS_w077_pmmActive "Driver assistance computer (secondary): w077 pmm active";
CM_ SG_ 876 APS_w078_pmmActive2 "Driver assistance computer (secondary): w078 pmm active2";
CM_ SG_ 876 APS_w079_edrAvailable "Driver assistance computer (secondary): w079 edr available";
CM_ SG_ 876 APS_w080_accFailedActivation "Driver assistance computer (secondary): w080 acc failed activation";
CM_ SG_ 876 APS_w081_pmmActiveBraking "Driver assistance computer (secondary): w081 pmm active braking";
CM_ SG_ 876 APS_w082_inPathFSviolation "Driver assistance computer (secondary): w082 in path f sviolation";
CM_ SG_ 876 APS_w083_inPathRADObject "Driver assistance computer (secondary): w083 in path RAD object";
CM_ SG_ 876 APS_w084_pmmIPSO "Driver assistance computer (secondary): w084 pmm IPSO";
CM_ SG_ 876 APS_w085_pmmSteering "Driver assistance computer (secondary): w085 pmm steering";
CM_ SG_ 876 APS_w086_robCollision "Driver assistance computer (secondary): w086 rob collision";
CM_ SG_ 876 APS_w087_DEPRECATED "Driver assistance computer (secondary): w087 DEPRECATED";
CM_ SG_ 876 APS_w088_DEPRECATED "Driver assistance computer (secondary): w088 DEPRECATED";
CM_ SG_ 876 APS_w089_DEPRECATED "Driver assistance computer (secondary): w089 DEPRECATED";
CM_ SG_ 876 APS_w090_DEPRECATED "Driver assistance computer (secondary): w090 DEPRECATED";
CM_ SG_ 876 APS_w091_DEPRECATED "Driver assistance computer (secondary): w091 DEPRECATED";
CM_ SG_ 876 APS_w092_DEPRECATED "Driver assistance computer (secondary): w092 DEPRECATED";
CM_ SG_ 876 APS_w093_DEPRECATED "Driver assistance computer (secondary): w093 DEPRECATED";
CM_ SG_ 876 APS_w094_DEPRECATED "Driver assistance computer (secondary): w094 DEPRECATED";
CM_ SG_ 876 APS_w095_DEPRECATED "Driver assistance computer (secondary): w095 DEPRECATED";
CM_ SG_ 876 APS_w096_DEPRECATED "Driver assistance computer (secondary): w096 DEPRECATED";
CM_ SG_ 876 APS_w097_DEPRECATED "Driver assistance computer (secondary): w097 DEPRECATED";
CM_ SG_ 876 APS_w098_DEPRECATED "Driver assistance computer (secondary): w098 DEPRECATED";
CM_ SG_ 876 APS_w099_DEPRECATED "Driver assistance computer (secondary): w099 DEPRECATED";
CM_ SG_ 876 APS_w100_DEPRECATED "Driver assistance computer (secondary): w100 DEPRECATED";
CM_ SG_ 876 APS_w101_DEPRECATED "Driver assistance computer (secondary): w101 DEPRECATED";
CM_ SG_ 876 APS_w102_DEPRECATED "Driver assistance computer (secondary): w102 DEPRECATED";
CM_ SG_ 876 APS_w103_robExperimentalAEB "Driver assistance computer (secondary): w103 rob experimental AEB";
CM_ SG_ 876 APS_w104_DEPRECATED "Driver assistance computer (secondary): w104 DEPRECATED";
CM_ SG_ 876 APS_w105_DEPRECATED "Driver assistance computer (secondary): w105 DEPRECATED";
CM_ SG_ 876 APS_w106_torsionBarOffset "Driver assistance computer (secondary): w106 torsion bar offset";
CM_ BO_ 1113 "Driver assistance computer (secondary) message: warning matrix2; frame length from the layout, not yet observed on a vehicle bus";
CM_ SG_ 1113 APS_w129_ECU_Power_Issue "Driver assistance computer (secondary): w129 ECU power issue";
CM_ SG_ 1113 APS_w130_ECU_Thermal_Issue "Driver assistance computer (secondary): w130 ECU thermal issue";
CM_ SG_ 1113 APS_w131_trap_exception "Driver assistance computer (secondary): w131 trap exception";
CM_ SG_ 1113 APS_w132_appVersionMismatch "Driver assistance computer (secondary): w132 app version mismatch";
CM_ SG_ 1113 APS_w133_ETHSwitchError "Driver assistance computer (secondary): w133 ETH switch error";
CM_ SG_ 1113 APS_w134_appMia "Driver assistance computer (secondary): w134 app mia";
CM_ SG_ 1113 APS_w135_appCritical "Driver assistance computer (secondary): w135 app critical";
CM_ SG_ 1113 APS_w136_gpsDisabled "Driver assistance computer (secondary): w136 gps disabled";
CM_ SG_ 1113 APS_w137_gpsFaultReset "Driver assistance computer (secondary): w137 gps fault reset";
CM_ SG_ 1113 APS_w138_gpsComIssue "Driver assistance computer (secondary): w138 gps com issue";
CM_ SG_ 1113 APS_w139_udpBufferOverflow "Driver assistance computer (secondary): w139 udp buffer overflow";
CM_ SG_ 1113 APS_w140_vcfrontMiaVehicleBus "Driver assistance computer (secondary): w140 vcfront mia vehicle bus";
CM_ SG_ 1113 APS_w141_rcmMiaPartyBus "Driver assistance computer (secondary): w141 rcm mia party bus";
CM_ SG_ 1113 APS_w142_diMiaPartyBus "Driver assistance computer (secondary): w142 di mia party bus";
CM_ SG_ 1113 APS_w143_espMiaPartyBus "Driver assistance computer (secondary): w143 esp mia party bus";
CM_ SG_ 1113 APS_w144_vcleftMiaPartyBus "Driver assistance computer (secondary): w144 vcleft mia party bus";
CM_ SG_ 1113 APS_w145_vcrightMiaPartyBus "Driver assistance computer (secondary): w145 vcright mia party bus";
CM_ SG_ 1113 APS_w146_epas3pMiaPartyBus "Driver assistance computer (secondary): w146 epas3p mia party bus";
CM_ SG_ 1113 APS_w147_vcleftMiaVehBus "Driver assistance computer (secondary): w147 vcleft mia veh bus";
CM_ SG_ 1113 APS_w148_vcrightMiaVehBus "Driver assistance computer (secondary): w148 vcright mia veh bus";
CM_ SG_ 1113 APS_w149_epblMiaVehBus "Driver assistance computer (secondary): w149 epbl mia veh bus";
CM_ SG_ 1113 APS_w150_sccmMiaVehBus "Driver assistance computer (secondary): w150 sccm mia veh bus";
CM_ SG_ 1113 APS_w151_apRecovered "Driver assistance computer (secondary): w151 ap recovered";
CM_ SG_ 1113 APS_w152_gpsFusionStatus "Driver assistance computer (secondary): w152 gps fusion status";
CM_ SG_ 1113 APS_w153_eacInhibit "Driver assistance computer (secondary): w153 eac inhibit";
CM_ SG_ 1113 APS_w155_ethLwipError "Driver assistance computer (secondary): w155 eth lwip error";
CM_ SG_ 1113 APS_w156_lwipAssert "Driver assistance computer (secondary): w156 lwip assert";
CM_ SG_ 1113 APS_w157_autopilotReboot "Driver assistance computer (secondary): w157 autopilot reboot";
CM_ SG_ 1113 APS_w158_apbMia "Driver assistance computer (secondary): w158 apb mia";
CM_ SG_ 1113 APS_w159_apbCritical "Driver assistance computer (secondary): w159 apb critical";
CM_ SG_ 1113 APS_w160_apbVersionMismatch "Driver assistance computer (secondary): w160 apb version mismatch";
CM_ SG_ 1113 APS_w161_gpsAntennaDisconnected "Driver assistance computer (secondary): w161 gps antenna disconnected";
CM_ SG_ 1113 APS_w162_TurboA_DisRegPgoodErr "Driver assistance computer (secondary): w162 turbo a dis reg pgood err";
CM_ SG_ 1113 APS_w163_TurboA_DisRegNFault "Driver assistance computer (secondary): w163 turbo a dis reg n fault";
CM_ SG_ 1113 APS_w164_TurboA_12VFuseFault "Driver assistance computer (secondary): w164 turbo a 12 v fuse fault";
CM_ SG_ 1113 APS_w165_TurboA_Temp_NOS "Driver assistance computer (secondary): w165 turbo a temp NOS";
CM_ SG_ 1113 APS_w166_TurboA_SMSLockStepErr "Driver assistance computer (secondary): w166 turbo a SMS lock step err";
CM_ SG_ 1113 APS_w167_TurboA_TMU_Throttle "Driver assistance computer (secondary): w167 turbo a TMU throttle";
CM_ SG_ 1113 APS_w168_TurboA_SMS_WDOG "Driver assistance computer (secondary): w168 turbo a SMS WDOG";
CM_ SG_ 1113 APS_w169_TurboA_SCS_LKUP "Driver assistance computer (secondary): w169 turbo a SCS LKUP";
CM_ SG_ 1113 APS_w170_TurboA_A72_watchdog "Driver assistance computer (secondary): w170 turbo a A72 watchdog";
CM_ SG_ 1113 APS_w171_TurboA_SMS_taskUtilErr "Driver assistance computer (secondary): w171 turbo a SMS task util err";
CM_ SG_ 1113 APS_w172_apFeaturesUnavailable "Driver assistance computer (secondary): w172 ap features unavailable";
CM_ SG_ 1113 APS_w178_TurboB_DisRegPgoodErr "Driver assistance computer (secondary): w178 turbo b dis reg pgood err";
CM_ SG_ 1113 APS_w179_TurboB_DisRegNFault "Driver assistance computer (secondary): w179 turbo b dis reg n fault";
CM_ SG_ 1113 APS_w180_TurboB_12VFuseFault "Driver assistance computer (secondary): w180 turbo b 12 v fuse fault";
CM_ SG_ 1113 APS_w181_TurboB_Temp_NOS "Driver assistance computer (secondary): w181 turbo b temp NOS";
CM_ SG_ 1113 APS_w182_TurboB_SMSLockStepErr "Driver assistance computer (secondary): w182 turbo b SMS lock step err";
CM_ SG_ 1113 APS_w183_TurboB_TMU_Throttle "Driver assistance computer (secondary): w183 turbo b TMU throttle";
CM_ SG_ 1113 APS_w184_TurboB_SMS_WDOG "Driver assistance computer (secondary): w184 turbo b SMS WDOG";
CM_ SG_ 1113 APS_w185_TurboB_SCS_LKUP "Driver assistance computer (secondary): w185 turbo b SCS LKUP";
CM_ SG_ 1113 APS_w186_TurboB_A72_watchdog "Driver assistance computer (secondary): w186 turbo b A72 watchdog";
CM_ SG_ 1113 APS_w187_TurboB_SMS_taskUtilErr "Driver assistance computer (secondary): w187 turbo b SMS task util err";
CM_ SG_ 1113 APS_w188_otherTurboUartMIA "Driver assistance computer (secondary): w188 other turbo uart MIA";
CM_ SG_ 1113 APS_w189_vcfrontMiaPartyBus "Driver assistance computer (secondary): w189 vcfront mia party bus";
CM_ SG_ 1113 APS_w190_iboosterMia "Driver assistance computer (secondary): w190 ibooster mia";
CM_ SG_ 1113 APS_w191_timesyncError "Driver assistance computer (secondary): w191 timesync error";
CM_ SG_ 1113 APS_w192_CANFault "Driver assistance computer (secondary): w192 CAN fault";
CM_ BO_ 848 "Driver assistance computer (secondary) message: warning matrix3; frame length from the layout, not yet observed on a vehicle bus";
CM_ SG_ 848 APS_w193_camWindshieldUnclean "Driver assistance computer (secondary): w193 cam windshield unclean";
CM_ SG_ 848 APS_w194_accDriverResumeRqrd "Driver assistance computer (secondary): w194 acc driver resume rqrd";
CM_ SG_ 848 APS_w195_scwUnavailable "Driver assistance computer (secondary): w195 scw unavailable";
CM_ SG_ 848 APS_w196_stopSignWarning "Driver assistance computer (secondary): w196 stop sign warning";
CM_ SG_ 848 APS_w197_redLightWarning "Driver assistance computer (secondary): w197 red light warning";
CM_ SG_ 848 APS_w198_tsrUnavailable "Driver assistance computer (secondary): w198 tsr unavailable";
CM_ SG_ 848 APS_w199_apcAbort "Driver assistance computer (secondary): w199 apc abort";
CM_ SG_ 848 APS_w200_lcSlowdown "Driver assistance computer (secondary): w200 lc slowdown";
CM_ SG_ 848 APS_w201_lcAborting "Driver assistance computer (secondary): w201 lc aborting";
CM_ SG_ 848 APS_w202_scwNoisyEnvironment "Driver assistance computer (secondary): w202 scw noisy environment";
CM_ SG_ 848 APS_w203_apcActivation "Driver assistance computer (secondary): w203 apc activation";
CM_ SG_ 848 APS_w204_apcFinalFront "Driver assistance computer (secondary): w204 apc final front";
CM_ SG_ 848 APS_w205_apcFinalRear "Driver assistance computer (secondary): w205 apc final rear";
CM_ SG_ 848 APS_w206_autosteerNotEnabled "Driver assistance computer (secondary): w206 autosteer not enabled";
CM_ SG_ 848 APS_w207_autosteerUnavailable "Driver assistance computer (secondary): w207 autosteer unavailable";
CM_ SG_ 848 APS_w208_rackDetected "Driver assistance computer (secondary): w208 rack detected";
CM_ SG_ 848 APS_w209_autoSummonRequest "Driver assistance computer (secondary): w209 auto summon request";
CM_ SG_ 848 APS_w210_camObstrcted "Driver assistance computer (secondary): w210 cam obstrcted";
CM_ SG_ 848 APS_w211_accNoSeatBelt "Driver assistance computer (secondary): w211 acc no seat belt";
CM_ SG_ 848 APS_w212_lcUnavailableStrikeOut "Driver assistance computer (secondary): w212 lc unavailable strike out";
CM_ SG_ 848 APS_w213_autosteerStruckOut "Driver assistance computer (secondary): w213 autosteer struck out";
CM_ SG_ 848 APS_w214_driverNotIntracting "Driver assistance computer (secondary): w214 driver not intracting";
CM_ SG_ 848 APS_w215_contDriverNotIntracting "Driver assistance computer (secondary): w215 cont driver not intracting";
CM_ SG_ 848 APS_w216_driverOverriding "Driver assistance computer (secondary): w216 driver overriding";
CM_ SG_ 848 APS_w217_lcUnavailableSpeeding "Driver assistance computer (secondary): w217 lc unavailable speeding";
CM_ SG_ 848 APS_w218_lcSpeedExceededLimit "Driver assistance computer (secondary): w218 lc speed exceeded limit";
CM_ SG_ 848 APS_w219_lcTempUnavailableSpeed "Driver assistance computer (secondary): w219 lc temp unavailable speed";
CM_ SG_ 848 APS_w220_lcTempUnavailableRoad "Driver assistance computer (secondary): w220 lc temp unavailable road";
CM_ SG_ 848 APS_w221_accRadarBlind "Driver assistance computer (secondary): w221 acc radar blind";
CM_ SG_ 848 APS_w222_accCameraBlind "Driver assistance computer (secondary): w222 acc camera blind";
CM_ SG_ 848 APS_w223_accObjectInPath "Driver assistance computer (secondary): w223 acc object in path";
CM_ SG_ 848 APS_w224_accCameraCalibration "Driver assistance computer (secondary): w224 acc camera calibration";
CM_ SG_ 848 APS_w225_lcDegradedVisSpeedLmt "Driver assistance computer (secondary): w225 lc degraded vis speed lmt";
CM_ SG_ 848 APS_w226_lcCamCalNeededSpeedLmt "Driver assistance computer (secondary): w226 lc cam cal needed speed lmt";
CM_ SG_ 848 APS_w227_virtualWallBlocked "Driver assistance computer (secondary): w227 virtual wall blocked";
CM_ SG_ 848 APS_w228_DEPRECATED "Driver assistance computer (secondary): w228 DEPRECATED";
CM_ SG_ 848 APS_w229_alcUltrasoundDamaged "Driver assistance computer (secondary): w229 alc ultrasound damaged";
CM_ SG_ 848 APS_w230_alcUltrasoundBlocked "Driver assistance computer (secondary): w230 alc ultrasound blocked";
CM_ SG_ 848 APS_w231_idfEvent "Driver assistance computer (secondary): w231 idf event";
CM_ SG_ 848 APS_w232_laneChangeRequested "Driver assistance computer (secondary): w232 lane change requested";
CM_ SG_ 848 APS_w235_a72LoopDetected "Driver assistance computer (secondary): w235 a72 loop detected";
CM_ SG_ 848 APS_w236_canSharedMemError "Driver assistance computer (secondary): w236 can shared mem error";
CM_ SG_ 848 APS_w237_faultMgrEventDetected "Driver assistance computer (secondary): w237 fault mgr event detected";
CM_ SG_ 848 APS_w238_resetReason "Driver assistance computer (secondary): w238 reset reason";
CM_ SG_ 848 APS_w241_ddrInitFailures "Driver assistance computer (secondary): w241 ddr init failures";
CM_ SG_ 848 APS_w242_tripMBISTFailure "Driver assistance computer (secondary): w242 trip MBIST failure";
CM_ SG_ 848 APS_w243_tripHWErrorStatus "Driver assistance computer (secondary): w243 trip HW error status";
CM_ SG_ 848 APS_w244_gpuHWFaultStatus "Driver assistance computer (secondary): w244 gpu HW fault status";
CM_ SG_ 848 APS_w245_eloopRxFromUnexpectedSo "Driver assistance computer (secondary): w245 eloop rx from unexpected source MAC";
CM_ SG_ 848 APS_w246_ethloopSwitchPortLinkDo "Driver assistance computer (secondary): w246 ethloop switch port link down";
CM_ SG_ 848 APS_w247_ethernetFrameError "Driver assistance computer (secondary): w247 ethernet frame error";
CM_ SG_ 848 APS_w248_ethloopSwitchPoorSqi "Driver assistance computer (secondary): w248 ethloop switch poor sqi";
CM_ SG_ 848 APS_w249_ufsFailures "Driver assistance computer (secondary): w249 ufs failures";
CM_ SG_ 848 APS_w250_ethloopSwitchMemUsageTo "Driver assistance computer (secondary): w250 ethloop switch mem usage too high port2";
CM_ SG_ 848 APS_w251_ethloopSwitchMemUsageTo "Driver assistance computer (secondary): w251 ethloop switch mem usage too high port3";
CM_ SG_ 848 APS_w252_ethSwitchPortLinkDown "Driver assistance computer (secondary): w252 eth switch port link down";
CM_ SG_ 848 APS_w253_powerStateTimeout "Driver assistance computer (secondary): w253 power state timeout";
CM_ SG_ 848 APS_w254_sleepStateTimeout "Driver assistance computer (secondary): w254 sleep state timeout";
CM_ SG_ 848 APS_w255_bootHealth "Driver assistance computer (secondary): w255 boot health";
CM_ BO_ 1465 "Driver assistance computer message: alert log; frame length from the layout, not yet observed on a vehicle bus";
CM_ SG_ 1465 DAS_alertID "Driver assistance computer: alert ID";
CM_ SG_ 1465 DAS_alertState "Driver assistance computer: alert state";
CM_ SG_ 1465 DAS_sw073_escalateLDWs "Driver assistance computer: sw073 escalate LD ws";
CM_ SG_ 1465 DAS_sw073_silentEscalatedLDW "Driver assistance computer: sw073 silent escalated LDW";
CM_ SG_ 1465 DAS_sw073_escalateLDWreason "Driver assistance computer: sw073 escalate LD wreason";
CM_ SG_ 1465 DAS_sw073_rawMobileyeLDW "Driver assistance computer: sw073 raw mobileye LDW";
CM_ SG_ 1465 DAS_sw073_freespaceLDW "Driver assistance computer: sw073 freespace LDW";
CM_ SG_ 1465 DAS_sw073_freespaceLeftC0 "Driver assistance computer: sw073 freespace left C0";
CM_ SG_ 1465 DAS_sw073_freespaceRightC0 "Driver assistance computer: sw073 freespace right C0";
CM_ SG_ 1465 DAS_sw073_freespaceLeftC1 "Driver assistance computer: sw073 freespace left C1";
CM_ SG_ 1465 DAS_sw073_freespaceRightC1 "Driver assistance computer: sw073 freespace right C1";
CM_ SG_ 1465 DAS_sw073_freespaceLeftFarZ "Driver assistance computer: sw073 freespace left far z";
CM_ SG_ 1465 DAS_sw073_freespaceRightFarZ "Driver assistance computer: sw073 freespace right far z";
CM_ SG_ 1465 DAS_sw230_sensor1Blocked "Driver assistance computer: sw230 sensor1 blocked";
CM_ SG_ 1465 DAS_sw230_sensor2Blocked "Driver assistance computer: sw230 sensor2 blocked";
CM_ SG_ 1465 DAS_sw230_sensor3Blocked "Driver assistance computer: sw230 sensor3 blocked";
CM_ SG_ 1465 DAS_sw230_sensor4Blocked "Driver assistance computer: sw230 sensor4 blocked";
CM_ SG_ 1465 DAS_sw230_sensor5Blocked "Driver assistance computer: sw230 sensor5 blocked";
CM_ SG_ 1465 DAS_sw230_sensor6Blocked "Driver assistance computer: sw230 sensor6 blocked";
CM_ SG_ 1465 DAS_sw230_sensor7Blocked "Driver assistance computer: sw230 sensor7 blocked";
CM_ SG_ 1465 DAS_sw230_sensor8Blocked "Driver assistance computer: sw230 sensor8 blocked";
CM_ SG_ 1465 DAS_sw230_sensor9Blocked "Driver assistance computer: sw230 sensor9 blocked";
CM_ SG_ 1465 DAS_sw230_sensor10Blocked "Driver assistance computer: sw230 sensor10 blocked";
CM_ SG_ 1465 DAS_sw230_sensor11Blocked "Driver assistance computer: sw230 sensor11 blocked";
CM_ SG_ 1465 DAS_sw230_sensor12Blocked "Driver assistance computer: sw230 sensor12 blocked";
CM_ BO_ 1497 "Driver assistance computer message: car log; frame length from the layout, not yet observed on a vehicle bus";
CM_ SG_ 1497 DAS_carLogMultiplexer "Driver assistance computer: car log multiplexer";
CM_ SG_ 1497 DAS_radarTarget5_dx "Measures the longitudinal distance from the radar to the nearest in-path stationary radar target.";
CM_ SG_ 1497 DAS_radarTarget1_dx "The longitudinal distance from the radar to radar target 1 (closest in-path vehicle)";
CM_ SG_ 1497 DAS_radarTarget1_VxRel "Measures the relative longitudinal velocity to the Adaptive Cruise Control (ACC) radar target 1.";
CM_ SG_ 1497 DAS_mobileyeVehAebFlag "Driver assistance computer: mobileye veh aeb flag";
CM_ SG_ 1497 DAS_mobileyePedAebFlag "Driver assistance computer: mobileye ped aeb flag";
CM_ SG_ 1497 DAS_mobileyeIPSOapproved "Driver assistance computer: mobileye IPS oapproved";
CM_ SG_ 1497 DAS_fcmSteeringOverride "Driver assistance computer: fcm steering override";
CM_ SG_ 1497 DAS_fcmCollisionStage3Checks "Reports the cross checks in the forward collision monitor.";
CM_ SG_ 1497 DAS_fcmThreatAssesmentMode "Driver assistance computer: fcm threat assesment mode";
CM_ SG_ 1497 DAS_constructionArea "Identifies construction area using the output of the 'scene tag' neural net.";
CM_ SG_ 1497 DAS_restrictionLowSpeedTraffic "Reports lane change restriction for low speed traffic.";
CM_ SG_ 1497 DAS_associated_rad_object "Indicates which radar target is associated with the vision object for Forward Collision Mitigation (FCM).";
CM_ SG_ 1497 DAS_LC_handsOnReason "Detects which hands on reason triggered the visual or audible hands-on-warning.";
CM_ SG_ 1497 DAS_ACC_camStatus "Driver assistance computer: ACC cam status";
CM_ SG_ 1497 DAS_aeb_not_activating_reason "Indicates the underlying reason why the next gen LCM AEB did not activate (not yet relevant)";
CM_ SG_ 1497 DAS_handsOnDetected "Driver assistance computer: hands on detected; raw 0 = signal not available (SNA)";
CM_ SG_ 1497 DAS_driveOnNavUnavailableReason "The high level reason why Navigate on Autopilot is not available.";
CM_ SG_ 1497 DAS_accUnavailableReason "The high level reason why ACC is not available.";
CM_ SG_ 1497 DAS_pmmNotActivatingReason "The high level reason why PMM v2 is not activating.";
CM_ SG_ 1497 DAS_desiredTarget_dx "Measures the distance to lead vehicle, or vehicle in the ego lane; raw 255 = signal not available (SNA)";
CM_ SG_ 1497 DAS_radarTarget2_dx "Measures the longitudinal distance from the radar to radar target 2, the 2nd closest in-path vehicle.";
CM_ SG_ 1497 DAS_radarTarget3_dx "Measures the longitudinal distance from the radar to the nearest vehicle in the right lane.";
CM_ SG_ 1497 DAS_radarTarget4_dx "Measures the longitudinal distance from the radar to the nearest vehicle in the left lane.";
CM_ SG_ 1497 DAS_closestInLaneTargetDx "Measures the longitudinal distance from front fascia to closest in-path object.";
CM_ SG_ 1497 DAS_secondInLaneTargetDx "Measures the longitudinal distance from front fascia to 2nd closest in-path object.";
CM_ SG_ 1497 DAS_closestLeftLaneTargetDx "Measures the longitudinal distance from front fascia to closest object in the left lane.";
CM_ SG_ 1497 DAS_closestRightLaneTargetDx "Measures the longitudinal distance from front fascia to closest object in the right lane.";
CM_ SG_ 1497 DAS_closestInLaneTargetVxRel "Measures the relative longitudinal velocity of closest in-path object.";
CM_ BO_ 1337 "Driver assistance computer message: info; frame length from the layout, not yet observed on a vehicle bus";
CM_ SG_ 1337 DAS_infoIndex "Driver assistance computer: info index";
CM_ SG_ 1337 DAS_infoBuildType "Driver assistance computer: info build type";
CM_ SG_ 1337 DAS_infoBuildConfigID "Driver assistance computer: info build config ID";
CM_ SG_ 1337 DAS_infoHardwareID "Driver assistance computer: info hardware ID";
CM_ SG_ 1337 DAS_infoComponentID "Driver assistance computer: info component ID";
CM_ SG_ 1337 DAS_infoPcbaID "Driver assistance computer: info pcba ID";
CM_ SG_ 1337 DAS_infoAssemblyID "Driver assistance computer: info assembly ID";
CM_ SG_ 1337 DAS_infoUsageID "Driver assistance computer: info usage ID";
CM_ SG_ 1337 DAS_infoSubUsageID "Driver assistance computer: info sub usage ID";
CM_ SG_ 1337 DAS_infoApplicationCRC "Driver assistance computer: info application CRC";
CM_ SG_ 1337 DAS_infoAppGitHashBytes "Driver assistance computer: info app git hash bytes";
CM_ SG_ 1337 DAS_infoBootGitHashBytes "Driver assistance computer: info boot git hash bytes";
CM_ BO_ 569 "Driver assistance computer message: lanes; frame length from the layout, not yet observed on a vehicle bus";
CM_ SG_ 569 DAS_leftLaneExists "Driver assistance computer: left lane exists";
CM_ SG_ 569 DAS_rightLaneExists "Driver assistance computer: right lane exists";
CM_ SG_ 569 DAS_virtualLaneWidth "Driver assistance computer: virtual lane width";
CM_ SG_ 569 DAS_virtualLaneViewRange "Driver assistance computer: virtual lane view range";
CM_ SG_ 569 DAS_virtualLaneC0 "Driver assistance computer: virtual lane C0";
CM_ SG_ 569 DAS_virtualLaneC1 "Driver assistance computer: virtual lane C1";
CM_ SG_ 569 DAS_virtualLaneC2 "Driver assistance computer: virtual lane C2";
CM_ SG_ 569 DAS_virtualLaneC3 "Driver assistance computer: virtual lane C3";
CM_ SG_ 569 DAS_leftLineUsage "Driver assistance computer: left line usage";
CM_ SG_ 569 DAS_rightLineUsage "Driver assistance computer: right line usage";
CM_ SG_ 569 DAS_leftFork "Driver assistance computer: left fork";
CM_ SG_ 569 DAS_rightFork "Driver assistance computer: right fork";
CM_ SG_ 569 DAS_lanesCounter "Driver assistance computer: lanes counter";
CM_ BO_ 921 "Driver assistance computer message: status; frame length from the layout, not yet observed on a vehicle bus";
CM_ SG_ 921 DAS_autopilotState "Reports the high level autopilot state; raw 15 = signal not available (SNA)";
CM_ SG_ 921 DAS_blindSpotRearLeft "Reports rear left blind spot warning level; raw 3 = signal not available (SNA)";
CM_ SG_ 921 DAS_blindSpotRearRight "Reports rear right blind spot warning level; raw 3 = signal not available (SNA)";
CM_ SG_ 921 DAS_fusedSpeedLimit "Driver assistance computer: fused speed limit; raw 0 = signal not available (SNA)";
CM_ SG_ 921 DAS_suppressSpeedWarning "Driver assistance computer: suppress speed warning";
CM_ SG_ 921 DAS_summonObstacle "Driver assistance computer: summon obstacle";
CM_ SG_ 921 DAS_summonClearedGate "Driver assistance computer: summon cleared gate";
CM_ SG_ 921 DAS_visionOnlySpeedLimit "Driver assistance computer: vision only speed limit; raw 0 = signal not available (SNA)";
CM_ SG_ 921 DAS_heaterState "The state of the app which runs the front glass heater; raw 0 = signal not available (SNA)";
CM_ SG_ 921 DAS_forwardCollisionWarning "Driver assistance computer: forward collision warning; raw 3 = signal not available (SNA)";
CM_ SG_ 921 DAS_autoparkReady "Indicates if all the conditions for Autopark are met.";
CM_ SG_ 921 DAS_autoParked "Driver assistance computer: auto parked";
CM_ SG_ 921 DAS_autoparkActive "Reports whether Autopark is currently active.";
CM_ SG_ 921 DAS_summonFwdLeashReached "Driver assistance computer: summon fwd leash reached";
CM_ SG_ 921 DAS_summonRvsLeashReached "Driver assistance computer: summon rvs leash reached";
CM_ SG_ 921 DAS_lssState "Tracks lane support system state and whether it is controlling steering angle requests for LKA / ELKA.";
CM_ SG_ 921 DAS_sideCollisionAvoid "Reports if the side collision avoidance function is active on the left or right; raw 3 = signal not available (SNA)";
CM_ SG_ 921 DAS_sideCollisionWarning "Reports if the side collision warning function is active in the left or right.";
CM_ SG_ 921 DAS_sideCollisionInhibit "Driver assistance computer: side collision inhibit";
CM_ SG_ 921 DAS_laneDepartureWarning "Driver assistance computer: lane departure warning; raw 5 = signal not available (SNA)";
CM_ SG_ 921 DAS_fleetSpeedState "The state of the fleet speed algorithm.";
CM_ SG_ 921 DAS_autopilotHandsOnState "Reports the state of the hands on state machine; raw 15 = signal not available (SNA)";
CM_ SG_ 921 DAS_autoLaneChangeState "Reports the legacy Automatic Lane Change (ALC) state used to drive the instrument cluster User Interface (UI); raw 31 = signal not available (SNA)";
CM_ SG_ 921 DAS_summonAvailable "Driver assistance computer: summon available";
CM_ SG_ 921 DAS_statusCounter "Driver assistance computer: status counter";
CM_ SG_ 921 DAS_statusChecksum "Driver assistance computer: status checksum";
CM_ BO_ 905 "Driver assistance computer message: status2; frame length from the layout, not yet observed on a vehicle bus";
CM_ SG_ 905 DAS_accSpeedLimit "Reports the Adaptive Cruise Control (ACC) speed limit, which is derived from speed limits embedded in maps; raw 511 = signal not available (SNA)";
CM_ SG_ 905 DAS_versionIdentifier "Driver assistance computer: version identifier";
CM_ SG_ 905 DAS_pmmObstacleSeverity "Detects the output of the Pedal Misapplication Mitigation (PMM) function, which limits torque or applies the brake; raw 7 = signal not available (SNA)";
CM_ SG_ 905 DAS_pmmLoggingRequest "Driver assistance computer: pmm logging request";
CM_ SG_ 905 DAS_activationFailureStatus "Driver assistance computer: activation failure status";
CM_ SG_ 905 DAS_pmmUltrasonicsFaultReason "Reports if there is a reason Pedal Misapplication Mitigation (PMM) is disabled due to a condition with the ultrasonics.";
CM_ SG_ 905 DAS_pmmRadarFaultReason "Reports if there is a reason Pedal Misapplication Mitigation (PMM) is disabled due to a radar issue.";
CM_ SG_ 905 DAS_pmmSysFaultReason "Reports if there is a reason Pedal Misapplication Mitigation (PMM) is disabled due to a system malfunction.";
CM_ SG_ 905 DAS_pmmCameraFaultReason "Reports if there is a reason Pedal Misapplication Mitigation (PMM) is disabled due to camera issues.";
CM_ SG_ 905 DAS_ACC_report "Indicates what control target Traffic-Aware Cruise Control (TACC) is controlling for. Only relevant during TACC (not Autosteer).";
CM_ SG_ 905 DAS_relaxCruiseLimits "Indicates whether DI should relax accel limits";
CM_ SG_ 905 DAS_csaState "Reports the state of the curve speed adaption algorithm.";
CM_ SG_ 905 DAS_radarTelemetry "Driver assistance computer: radar telemetry";
CM_ SG_ 905 DAS_robState "Driver assistance computer: rob state";
CM_ SG_ 905 DAS_driverInteractionLevel "Driver assistance computer: driver interaction level";
CM_ SG_ 905 DAS_ppOffsetDesiredRamp "Driver assistance computer: pp offset desired ramp";
CM_ SG_ 905 DAS_longCollisionWarning "Driver assistance computer: long collision warning; raw 15 = signal not available (SNA)";
CM_ SG_ 905 DAS_status2Counter "Driver assistance computer: status2 counter";
CM_ SG_ 905 DAS_status2Checksum "Driver assistance computer: status2 checksum";
CM_ BO_ 586 "Driver assistance computer message: visual debug; frame length from the layout, not yet observed on a vehicle bus";
CM_ SG_ 586 DAS_autosteerVehiclesUsage "Driver assistance computer: autosteer vehicles usage";
CM_ SG_ 586 DAS_autosteerHPPUsage "Driver assistance computer: autosteer HPP usage";
CM_ SG_ 586 DAS_autosteerNavigationUsage "Driver assistance computer: autosteer navigation usage";
CM_ SG_ 586 DAS_autosteerModelUsage "Driver assistance computer: autosteer model usage";
CM_ SG_ 586 DAS_autosteerBottsDotsUsage "Driver assistance computer: autosteer botts dots usage";
CM_ SG_ 586 DAS_offsetSide "Driver assistance computer: offset side";
CM_ SG_ 586 DAS_roadSurfaceType "Driver assistance computer: road surface type; raw 0 = signal not available (SNA)";
CM_ SG_ 586 DAS_autosteerHealthAnomalyLevel "Driver assistance computer: autosteer health anomaly level";
CM_ SG_ 586 DAS_autosteerHealthState "Driver assistance computer: autosteer health state";
CM_ SG_ 586 DAS_lastLinePreferenceReason "Driver assistance computer: last line preference reason";
CM_ SG_ 586 DAS_plannerState "Driver assistance computer: planner state";
CM_ SG_ 586 DAS_lastAutosteerAbortReason "Driver assistance computer: last autosteer abort reason";
CM_ SG_ 586 DAS_devAppInterfaceEnabled "Driver assistance computer: dev app interface enabled";
CM_ SG_ 586 DAS_navAvailable "Driver assistance computer: nav available";
CM_ SG_ 586 DAS_navDistance "Driver assistance computer: nav distance";
CM_ SG_ 586 DAS_accSmartSpeedActive "Driver assistance computer: acc smart speed active";
CM_ SG_ 586 DAS_accSmartSpeedState "Driver assistance computer: acc smart speed state; raw 7 = signal not available (SNA)";
CM_ SG_ 586 DAS_ulcInProgress "Reports active lane changes that were not commanded.";
CM_ SG_ 586 DAS_trafficAwareSetSpeedInUse "Indicates that autopilot is using cruise set speed based on flow of traffic";
CM_ SG_ 586 DAS_isaSystemState "ISA system state";
CM_ SG_ 586 DAS_behaviorType "Driver assistance computer: behavior type";
CM_ SG_ 586 DAS_ulcType "Reports the underlying reason for the uncommanded lane change, whether for speed or route.";
CM_ SG_ 586 DAS_rearVehDetectedThisCycle "Driver assistance computer: rear veh detected this cycle";
CM_ SG_ 586 DAS_rearLeftVehDetectedCurrent "Driver assistance computer: rear left veh detected current";
CM_ SG_ 586 DAS_rearRightVehDetectedTrip "Driver assistance computer: rear right veh detected trip";
CM_ SG_ 586 DAS_rearLeftVehDetectedTrip "Driver assistance computer: rear left veh detected trip";
CM_ BO_ 810 "Driver assistance computer message: warning matrix0; frame length from the layout, not yet observed on a vehicle bus";
CM_ SG_ 810 DAS_w002_ldwDisabled "Driver assistance computer: w002 ldw disabled";
CM_ SG_ 810 DAS_w003_isaDisabled "Driver assistance computer: w003 isa disabled";
CM_ SG_ 810 DAS_w004_accDisabled "Driver assistance computer: w004 acc disabled";
CM_ SG_ 810 DAS_w005_fcwCancelled "Driver assistance computer: w005 fcw cancelled";
CM_ SG_ 810 DAS_w006_aebCancelled "Driver assistance computer: w006 aeb cancelled";
CM_ SG_ 810 DAS_w007_ahlbDisabled "Driver assistance computer: w007 ahlb disabled";
CM_ SG_ 810 DAS_w008_parkDisabled "Driver assistance computer: w008 park disabled";
CM_ SG_ 810 DAS_w009_aebFault "Driver assistance computer: w009 aeb fault";
CM_ SG_ 810 DAS_w010_radcCalibIssue "Driver assistance computer: w010 radc calib issue";
CM_ SG_ 810 DAS_w011_scaEvent "Driver assistance computer: w011 sca event";
CM_ SG_ 810 DAS_w012_Cam_BootFailure "Driver assistance computer: w012 cam boot failure";
CM_ SG_ 810 DAS_w013_Cam_Watchdog "Driver assistance computer: w013 cam watchdog";
CM_ SG_ 810 DAS_w014_swAssert "Driver assistance computer: w014 sw assert";
CM_ SG_ 810 DAS_w015_Camera_Failsafes "Driver assistance computer: w015 camera failsafes";
CM_ SG_ 810 DAS_w016_aeb_e_event "Driver assistance computer: w016 aeb e event";
CM_ SG_ 810 DAS_w017_Cam_Msg_MIA "Driver assistance computer: w017 cam msg MIA";
CM_ SG_ 810 DAS_w018_ECU_Power_Issue "Driver assistance computer: w018 ECU power issue";
CM_ SG_ 810 DAS_w019_ECU_Stack_Overflow "Driver assistance computer: w019 ECU stack overflow";
CM_ SG_ 810 DAS_w020_ECU_checkstopError "Driver assistance computer: w020 ECU checkstop error";
CM_ SG_ 810 DAS_w021_ECU_Temperature_Issue "Driver assistance computer: w021 ECU temperature issue";
CM_ SG_ 810 DAS_w022_ECU_EEPROM_Failure "Driver assistance computer: w022 ECU EEPROM failure";
CM_ SG_ 810 DAS_w023_ECU_Cam_Statemismatc "Driver assistance computer: w023 ECU cam statemismatc";
CM_ SG_ 810 DAS_w024_ECU_Watchdog_Reset "Driver assistance computer: w024 ECU watchdog reset";
CM_ SG_ 810 DAS_w025_LC_Steering_Override "Driver assistance computer: w025 LC steering override";
CM_ SG_ 810 DAS_w026_ECU_timingIssue "Driver assistance computer: w026 ECU timing issue";
CM_ SG_ 810 DAS_w027_ECU_Reset_Fault "Driver assistance computer: w027 ECU reset fault";
CM_ SG_ 810 DAS_w028_spi_rx_error "Driver assistance computer: w028 spi rx error";
CM_ SG_ 810 DAS_w029_spi_tx_error "Driver assistance computer: w029 spi tx error";
CM_ SG_ 810 DAS_w030_Heater_Issue "Driver assistance computer: w030 heater issue";
CM_ SG_ 810 DAS_w031_canRxError "Driver assistance computer: w031 can rx error";
CM_ SG_ 810 DAS_w032_canTxError "Driver assistance computer: w032 can tx error";
CM_ SG_ 810 DAS_w033_gtwMia "Driver assistance computer: w033 gtw mia";
CM_ SG_ 810 DAS_w034_sccmMia "Driver assistance computer: w034 sccm mia";
CM_ SG_ 810 DAS_w035_espMia "Driver assistance computer: w035 esp mia";
CM_ SG_ 810 DAS_w036_bdyMia "Driver assistance computer: w036 bdy mia";
CM_ SG_ 810 DAS_w037_camTacIssue "Driver assistance computer: w037 cam tac issue";
CM_ SG_ 810 DAS_w038_camFailure "Driver assistance computer: w038 cam failure";
CM_ SG_ 810 DAS_w039_sdm_rcm_Mia "Driver assistance computer: w039 sdm rcm mia";
CM_ SG_ 810 DAS_w040_autopilotAngleSaturated "Driver assistance computer: w040 autopilot angle saturated";
CM_ SG_ 810 DAS_w041_autopilotRateSaturated "Driver assistance computer: w041 autopilot rate saturated";
CM_ SG_ 810 DAS_w042_autopilotAborting "Driver assistance computer: w042 autopilot aborting";
CM_ SG_ 810 DAS_w043_camLongRunTime "Driver assistance computer: w043 cam long run time";
CM_ SG_ 810 DAS_w044_appMobileyeFailure "Driver assistance computer: w044 app mobileye failure";
CM_ SG_ 810 DAS_w045_radMia "Driver assistance computer: w045 rad mia";
CM_ SG_ 810 DAS_w046_eepromRecordAbsent "Driver assistance computer: w046 eeprom record absent";
CM_ SG_ 810 DAS_w047_edrEvent "Driver assistance computer: w047 edr event";
CM_ SG_ 810 DAS_w048_DAS_Features_Disabled "Driver assistance computer: w048 DAS features disabled";
CM_ SG_ 810 DAS_w049_eyeqVersionMismatch "Driver assistance computer: w049 eyeq version mismatch";
CM_ SG_ 810 DAS_w050_aeb_event "Driver assistance computer: w050 aeb event";
CM_ SG_ 810 DAS_w051_radcEcuIssue "Driver assistance computer: w051 radc ecu issue";
CM_ SG_ 810 DAS_w052_radcSensorIssue "Driver assistance computer: w052 radc sensor issue";
CM_ SG_ 810 DAS_w053_radcCommIssue "Driver assistance computer: w053 radc comm issue";
CM_ SG_ 810 DAS_w054_camAutofix "Driver assistance computer: w054 cam autofix";
CM_ SG_ 810 DAS_w055_radcVersionMismatch "Driver assistance computer: w055 radc version mismatch";
CM_ SG_ 810 DAS_w056_diMia "Driver assistance computer: w056 di mia";
CM_ SG_ 810 DAS_w057_mcuMia "Driver assistance computer: w057 mcu mia";
CM_ SG_ 810 DAS_w058_epbMia "Driver assistance computer: w058 epb mia";
CM_ SG_ 810 DAS_w059_parkMia "Driver assistance computer: w059 park mia";
CM_ SG_ 810 DAS_w060_fcw_event "Driver assistance computer: w060 fcw event";
CM_ SG_ 810 DAS_w061_airSuspensionMia "Driver assistance computer: w061 air suspension mia";
CM_ SG_ 810 DAS_w062_radcAlignment "Driver assistance computer: w062 radc alignment";
CM_ SG_ 810 DAS_w063_parkVersionMismatch "Driver assistance computer: w063 park version mismatch";
CM_ SG_ 810 DAS_w064_epasMia "Driver assistance computer: w064 epas mia";
CM_ BO_ 874 "Driver assistance computer message: warning matrix1; frame length from the layout, not yet observed on a vehicle bus";
CM_ SG_ 874 DAS_w065_deserializerOvercurrent "Driver assistance computer: w065 deserializer overcurrent";
CM_ SG_ 874 DAS_w066_deserializerLockLost "Driver assistance computer: w066 deserializer lock lost";
CM_ SG_ 874 DAS_w067_steeringAlignment "Driver assistance computer: w067 steering alignment";
CM_ SG_ 874 DAS_w068_vlInconsistency "Driver assistance computer: w068 vl inconsistency";
CM_ SG_ 874 DAS_w069_apcSpaceMasked "Driver assistance computer: w069 apc space masked";
CM_ SG_ 874 DAS_w070_apcIncompleteCal "Driver assistance computer: w070 apc incomplete cal";
CM_ SG_ 874 DAS_w071_selfparkStarted "Driver assistance computer: w071 selfpark started";
CM_ SG_ 874 DAS_w072_selfparkComplete "Driver assistance computer: w072 selfpark complete";
CM_ SG_ 874 DAS_w073_issueEscalatedLDW "Driver assistance computer: w073 issue escalated LDW";
CM_ SG_ 874 DAS_w074_inPathStationaryObst "Driver assistance computer: w074 in path stationary obst";
CM_ SG_ 874 DAS_w075_scMia "Driver assistance computer: w075 sc mia";
CM_ SG_ 874 DAS_w076_mobilEyeSetC "Driver assistance computer: w076 mobil eye set c";
CM_ SG_ 874 DAS_w077_pmmActive "Driver assistance computer: w077 pmm active";
CM_ SG_ 874 DAS_w078_pmmActive2 "Driver assistance computer: w078 pmm active2";
CM_ SG_ 874 DAS_w079_edrAvailable "Driver assistance computer: w079 edr available";
CM_ SG_ 874 DAS_w080_accFailedActivation "Driver assistance computer: w080 acc failed activation";
CM_ SG_ 874 DAS_w081_pmmActiveBraking "Driver assistance computer: w081 pmm active braking";
CM_ SG_ 874 DAS_w082_inPathFSviolation "Driver assistance computer: w082 in path f sviolation";
CM_ SG_ 874 DAS_w083_inPathRADObject "Driver assistance computer: w083 in path RAD object";
CM_ SG_ 874 DAS_w084_pmmIPSO "Driver assistance computer: w084 pmm IPSO";
CM_ SG_ 874 DAS_w085_pmmSteering "Driver assistance computer: w085 pmm steering";
CM_ SG_ 874 DAS_w086_robCollision "Driver assistance computer: w086 rob collision";
CM_ SG_ 874 DAS_w087_DEPRECATED "Driver assistance computer: w087 DEPRECATED";
CM_ SG_ 874 DAS_w088_DEPRECATED "Driver assistance computer: w088 DEPRECATED";
CM_ SG_ 874 DAS_w089_DEPRECATED "Driver assistance computer: w089 DEPRECATED";
CM_ SG_ 874 DAS_w090_DEPRECATED "Driver assistance computer: w090 DEPRECATED";
CM_ SG_ 874 DAS_w091_DEPRECATED "Driver assistance computer: w091 DEPRECATED";
CM_ SG_ 874 DAS_w092_DEPRECATED "Driver assistance computer: w092 DEPRECATED";
CM_ SG_ 874 DAS_w093_DEPRECATED "Driver assistance computer: w093 DEPRECATED";
CM_ SG_ 874 DAS_w094_DEPRECATED "Driver assistance computer: w094 DEPRECATED";
CM_ SG_ 874 DAS_w095_DEPRECATED "Driver assistance computer: w095 DEPRECATED";
CM_ SG_ 874 DAS_w096_DEPRECATED "Driver assistance computer: w096 DEPRECATED";
CM_ SG_ 874 DAS_w097_DEPRECATED "Driver assistance computer: w097 DEPRECATED";
CM_ SG_ 874 DAS_w098_DEPRECATED "Driver assistance computer: w098 DEPRECATED";
CM_ SG_ 874 DAS_w099_DEPRECATED "Driver assistance computer: w099 DEPRECATED";
CM_ SG_ 874 DAS_w100_DEPRECATED "Driver assistance computer: w100 DEPRECATED";
CM_ SG_ 874 DAS_w101_DEPRECATED "Driver assistance computer: w101 DEPRECATED";
CM_ SG_ 874 DAS_w102_DEPRECATED "Driver assistance computer: w102 DEPRECATED";
CM_ SG_ 874 DAS_w103_robExperimentalAEB "Driver assistance computer: w103 rob experimental AEB";
CM_ SG_ 874 DAS_w104_DEPRECATED "Driver assistance computer: w104 DEPRECATED";
CM_ SG_ 874 DAS_w105_DEPRECATED "Driver assistance computer: w105 DEPRECATED";
CM_ SG_ 874 DAS_w106_torsionBarCalibrated "Driver assistance computer: w106 torsion bar calibrated";
BA_DEF_ "BusType" STRING;
BA_DEF_ "DBName" STRING;
BA_DEF_ "Baudrate" INT 0 1000000;
BA_DEF_ "BaudrateCANFD" INT 0 16000000;
BA_DEF_ "Manufacturer" STRING;
BA_DEF_ "FirmwareVersion" STRING;
BA_DEF_ "VehicleModel" STRING;
BA_DEF_ BU_ "ECU" STRING;
BA_DEF_ BO_ "GenMsgCycleTime" INT 0 3600000;
BA_DEF_ BO_ "GenMsgSendType" ENUM "Cyclic","NotUsed","NotUsed","NotUsed","NotUsed","NotUsed","NotUsed","IfActive","NoMsgSendType","NotUsed";
BA_DEF_ BO_ "VFrameFormat" ENUM "StandardCAN","ExtendedCAN","reserved","J1939PG","reserved","reserved","reserved","reserved","reserved","reserved","reserved","reserved","reserved","reserved","StandardCAN_FD","ExtendedCAN_FD";
BA_DEF_ BO_ "CANFD_BRS" ENUM "0","1";
BA_DEF_ SG_ "GenSigSNA" STRING;
BA_DEF_ SG_ "SystemSignalLongSymbol" STRING;
BA_DEF_ SG_ "Confidence" ENUM "validated","plausible","layout-only","contradicted";
BA_DEF_DEF_ "BusType" "CAN";
BA_DEF_DEF_ "DBName" "";
BA_DEF_DEF_ "Baudrate" 500000;
BA_DEF_DEF_ "BaudrateCANFD" 2000000;
BA_DEF_DEF_ "Manufacturer" "";
BA_DEF_DEF_ "FirmwareVersion" "";
BA_DEF_DEF_ "VehicleModel" "";
BA_DEF_DEF_ "ECU" "";
BA_DEF_DEF_ "GenMsgCycleTime" 0;
BA_DEF_DEF_ "GenMsgSendType" "NoMsgSendType";
BA_DEF_DEF_ "VFrameFormat" "StandardCAN";
BA_DEF_DEF_ "CANFD_BRS" "1";
BA_DEF_DEF_ "GenSigSNA" "";
BA_DEF_DEF_ "SystemSignalLongSymbol" "";
BA_DEF_DEF_ "Confidence" "layout-only";
BA_ "DBName" "AllModels_CH";
BA_ "Manufacturer" "Tesla";
BA_ "FirmwareVersion" "2025.20.8";
BA_ "VehicleModel" "Model 3 / Model Y";
BA_ "ECU" BU_ APP "APP";
BA_ "ECU" BU_ APS "APS";
BA_ "ECU" BU_ DAS "DAS";
BA_ "ECU" BU_ EPAS3S "EPAS3S";
BA_ "ECU" BU_ EPASTS "EPASTS";
BA_ "ECU" BU_ ESP "ESP";
BA_ "ECU" BU_ GTW "GTW";
BA_ "ECU" BU_ IBST "IBST";
BA_ "ECU" BU_ IDB "IDB";
BA_ "ECU" BU_ PARK "PARK";
BA_ "ECU" BU_ RADC "RADC";
BA_ "ECU" BU_ RCM "RCM";
BA_ "ECU" BU_ RCM3 "RCM3";
BA_ "ECU" BU_ RCU "RCU";
BA_ "ECU" BU_ TPMS "TPMS";
BA_ "ECU" BU_ USM "USM";
BA_ "GenMsgCycleTime" BO_ 1045 500;
BA_ "GenMsgSendType" BO_ 1045 0;
BA_ "GenMsgCycleTime" BO_ 1020 1000;
BA_ "GenMsgSendType" BO_ 1020 0;
BA_ "GenMsgCycleTime" BO_ 1018 500;
BA_ "GenMsgSendType" BO_ 1018 0;
BA_ "GenMsgCycleTime" BO_ 1043 500;
BA_ "GenMsgSendType" BO_ 1043 0;
BA_ "GenMsgCycleTime" BO_ 1061 1000;
BA_ "GenMsgSendType" BO_ 1061 0;
BA_ "GenMsgCycleTime" BO_ 843 100;
BA_ "GenMsgSendType" BO_ 843 0;
BA_ "GenMsgCycleTime" BO_ 1353 1000;
BA_ "GenMsgSendType" BO_ 1353 0;
BA_ "GenMsgCycleTime" BO_ 907 100;
BA_ "GenMsgSendType" BO_ 907 0;
BA_ "GenMsgCycleTime" BO_ 605 500;
BA_ "GenMsgSendType" BO_ 605 0;
BA_ "GenMsgCycleTime" BO_ 859 100;
BA_ "GenMsgSendType" BO_ 859 0;
BA_ "GenMsgCycleTime" BO_ 809 1000;
BA_ "GenMsgSendType" BO_ 809 0;
BA_ "GenMsgCycleTime" BO_ 873 1000;
BA_ "GenMsgSendType" BO_ 873 0;
BA_ "GenMsgCycleTime" BO_ 1065 1000;
BA_ "GenMsgSendType" BO_ 1065 0;
BA_ "GenMsgCycleTime" BO_ 1097 1000;
BA_ "GenMsgSendType" BO_ 1097 0;
BA_ "GenMsgCycleTime" BO_ 637 100;
BA_ "GenMsgSendType" BO_ 637 0;
BA_ "GenMsgCycleTime" BO_ 992 100;
BA_ "GenMsgSendType" BO_ 992 0;
BA_ "GenMsgCycleTime" BO_ 1510 1000;
BA_ "GenMsgSendType" BO_ 1510 0;
BA_ "GenMsgCycleTime" BO_ 811 1000;
BA_ "GenMsgSendType" BO_ 811 0;
BA_ "GenMsgCycleTime" BO_ 876 1000;
BA_ "GenMsgSendType" BO_ 876 0;
BA_ "GenMsgCycleTime" BO_ 1113 1000;
BA_ "GenMsgSendType" BO_ 1113 0;
BA_ "GenMsgCycleTime" BO_ 848 1000;
BA_ "GenMsgSendType" BO_ 848 0;
BA_ "GenMsgCycleTime" BO_ 1497 333;
BA_ "GenMsgSendType" BO_ 1497 0;
BA_ "GenMsgCycleTime" BO_ 1337 1000;
BA_ "GenMsgSendType" BO_ 1337 0;
BA_ "GenMsgCycleTime" BO_ 569 100;
BA_ "GenMsgSendType" BO_ 569 0;
BA_ "GenMsgCycleTime" BO_ 921 500;
BA_ "GenMsgSendType" BO_ 921 0;
BA_ "GenMsgCycleTime" BO_ 905 500;
BA_ "GenMsgSendType" BO_ 905 0;
BA_ "GenMsgCycleTime" BO_ 586 100;
BA_ "GenMsgSendType" BO_ 586 0;
BA_ "GenMsgCycleTime" BO_ 810 1000;
BA_ "GenMsgSendType" BO_ 810 0;
BA_ "GenMsgCycleTime" BO_ 874 1000;
BA_ "GenMsgSendType" BO_ 874 0;
BA_ "Confidence" SG_ 1045 APP_backupDashCamFeedGood 0;
BA_ "Confidence" SG_ 1045 APP_backupDashCamFrameRate 0;
BA_ "Confidence" SG_ 1020 APP_decisionTemperature 0;
BA_ "Confidence" SG_ 1020 APP_pascalTemperature 0;
BA_ "Confidence" SG_ 1020 APP_parkerATemperature 0;
BA_ "Confidence" SG_ 1020 APP_parkerBTemperature 0;
BA_ "Confidence" SG_ 1020 APP_pascalExtTemperature 0;
BA_ "Confidence" SG_ 1020 APP_parkerExtTemperature 0;
BA_ "Confidence" SG_ 1020 APP_pascalHeaterDecision 0;
BA_ "Confidence" SG_ 1018 APP_mainCameraLUX 0;
BA_ "GenSigSNA" SG_ 1018 APP_mainCameraLUX "255";
BA_ "Confidence" SG_ 1018 APP_narrowCameraLUX 0;
BA_ "GenSigSNA" SG_ 1018 APP_narrowCameraLUX "255";
BA_ "Confidence" SG_ 1018 APP_fisheyeCameraLUX 0;
BA_ "GenSigSNA" SG_ 1018 APP_fisheyeCameraLUX "255";
BA_ "Confidence" SG_ 1018 APP_lRepeatCameraLUX 0;
BA_ "GenSigSNA" SG_ 1018 APP_lRepeatCameraLUX "255";
BA_ "Confidence" SG_ 1018 APP_rRepeatCameraLUX 0;
BA_ "GenSigSNA" SG_ 1018 APP_rRepeatCameraLUX "255";
BA_ "Confidence" SG_ 1018 APP_lPillarCameraLUX 0;
BA_ "GenSigSNA" SG_ 1018 APP_lPillarCameraLUX "255";
BA_ "Confidence" SG_ 1018 APP_rPillarCameraLUX 0;
BA_ "GenSigSNA" SG_ 1018 APP_rPillarCameraLUX "255";
BA_ "Confidence" SG_ 1018 APP_backupCameraLUX 0;
BA_ "GenSigSNA" SG_ 1018 APP_backupCameraLUX "255";
BA_ "Confidence" SG_ 1043 APP_mainDashCamFeedGood 0;
BA_ "Confidence" SG_ 1043 APP_mainDashCamFrameRate 0;
BA_ "Confidence" SG_ 1043 APP_lRepeatDashCamFeedGood 0;
BA_ "Confidence" SG_ 1043 APP_lRepeatDashCamFrameRate 0;
BA_ "Confidence" SG_ 1043 APP_rRepeatDashCamFeedGood 0;
BA_ "Confidence" SG_ 1043 APP_rRepeatDashCamFrameRate 0;
BA_ "Confidence" SG_ 1061 APP_factoryGoalLatitude 0;
BA_ "Confidence" SG_ 1061 APP_factoryGoalLongitude 0;
BA_ "Confidence" SG_ 1061 APP_factoryGoalSpeed 0;
BA_ "Confidence" SG_ 843 APP_frontLeftParkAssist 0;
BA_ "GenSigSNA" SG_ 843 APP_frontLeftParkAssist "255";
BA_ "Confidence" SG_ 843 APP_frontLeftMiddleParkAssist 0;
BA_ "GenSigSNA" SG_ 843 APP_frontLeftMiddleParkAssist "255";
BA_ "Confidence" SG_ 843 APP_frontMiddleParkAssist 0;
BA_ "GenSigSNA" SG_ 843 APP_frontMiddleParkAssist "255";
BA_ "Confidence" SG_ 843 APP_frontRightMiddleParkAssist 0;
BA_ "GenSigSNA" SG_ 843 APP_frontRightMiddleParkAssist "255";
BA_ "Confidence" SG_ 843 APP_frontRightParkAssist 0;
BA_ "GenSigSNA" SG_ 843 APP_frontRightParkAssist "255";
BA_ "Confidence" SG_ 843 APP_parkAssistStatus 0;
BA_ "GenSigSNA" SG_ 843 APP_parkAssistStatus "3";
BA_ "Confidence" SG_ 843 APP_useParkDistancesFromAP 0;
BA_ "Confidence" SG_ 1353 APP_infoIndex 1;
BA_ "Confidence" SG_ 1353 APP_buildType 0;
BA_ "Confidence" SG_ 907 APP_rearLeftParkAssist 0;
BA_ "GenSigSNA" SG_ 907 APP_rearLeftParkAssist "255";
BA_ "Confidence" SG_ 907 APP_rearLeftMiddleParkAssist 0;
BA_ "GenSigSNA" SG_ 907 APP_rearLeftMiddleParkAssist "255";
BA_ "Confidence" SG_ 907 APP_rearMiddleParkAssist 0;
BA_ "GenSigSNA" SG_ 907 APP_rearMiddleParkAssist "255";
BA_ "Confidence" SG_ 907 APP_rearRightMiddleParkAssist 0;
BA_ "GenSigSNA" SG_ 907 APP_rearRightMiddleParkAssist "255";
BA_ "Confidence" SG_ 907 APP_rearRightParkAssist 0;
BA_ "GenSigSNA" SG_ 907 APP_rearRightParkAssist "255";
BA_ "Confidence" SG_ 605 APP_tcFeatureState 0;
BA_ "Confidence" SG_ 605 APP_tcStateMachine 0;
BA_ "Confidence" SG_ 605 APP_tcControlSource 0;
BA_ "Confidence" SG_ 605 APP_tcControlType 0;
BA_ "Confidence" SG_ 605 APP_tcControlDistance 0;
BA_ "GenSigSNA" SG_ 605 APP_tcControlDistance "255";
BA_ "Confidence" SG_ 605 APP_tcControlLightState 0;
BA_ "Confidence" SG_ 605 APP_tcContinuationReason 0;
BA_ "Confidence" SG_ 605 APP_tcConfirmationType 0;
BA_ "Confidence" SG_ 605 APP_tcWarningSuppressionReason 0;
BA_ "Confidence" SG_ 605 APP_tcUnavailableReason 0;
BA_ "Confidence" SG_ 605 APP_tcVisionLight 0;
BA_ "Confidence" SG_ 605 APP_tcVisionSign 0;
BA_ "Confidence" SG_ 605 APP_tcVisionRoadMarking 0;
BA_ "Confidence" SG_ 605 APP_tcVisionLine 0;
BA_ "Confidence" SG_ 859 APP_visionOcsStatusChecksum 0;
BA_ "Confidence" SG_ 859 APP_visionOcsStateRaw 0;
BA_ "Confidence" SG_ 859 APP_visionOcsEmptyProbRaw 0;
BA_ "GenSigSNA" SG_ 859 APP_visionOcsEmptyProbRaw "255";
BA_ "Confidence" SG_ 859 APP_visionOcsChildProbRaw 0;
BA_ "GenSigSNA" SG_ 859 APP_visionOcsChildProbRaw "255";
BA_ "Confidence" SG_ 859 APP_visionOcsAdultProbRaw 0;
BA_ "GenSigSNA" SG_ 859 APP_visionOcsAdultProbRaw "255";
BA_ "Confidence" SG_ 859 APP_visionOcsFrontPasClsVisionSt 0;
BA_ "SystemSignalLongSymbol" SG_ 859 APP_visionOcsFrontPasClsVisionSt "APP_visionOcsFrontPasClsVisionStateFlt";
BA_ "Confidence" SG_ 859 APP_visionOcsStatusCounter 0;
BA_ "Confidence" SG_ 637 APS_eacAllow 0;
BA_ "GenSigSNA" SG_ 637 APS_eacAllow "3";
BA_ "Confidence" SG_ 637 APS_eacMonitorCounter 0;
BA_ "Confidence" SG_ 637 APS_eacMonitorChecksum 0;
BA_ "Confidence" SG_ 992 APS_A_lowPowerRequest 0;
BA_ "Confidence" SG_ 992 APS_A_lowPowerRequestor 0;
BA_ "Confidence" SG_ 992 APS_A_forcePowerOffRequest 0;
BA_ "Confidence" SG_ 992 APS_B_lowPowerRequest 0;
BA_ "Confidence" SG_ 992 APS_B_lowPowerRequestor 0;
BA_ "Confidence" SG_ 992 APS_B_forcePowerOffRequest 0;
BA_ "Confidence" SG_ 1510 APS_A_cam12v0Voltage 0;
BA_ "GenSigSNA" SG_ 1510 APS_A_cam12v0Voltage "4095";
BA_ "Confidence" SG_ 1510 APS_B_cam12v0Voltage 0;
BA_ "GenSigSNA" SG_ 1510 APS_B_cam12v0Voltage "4095";
BA_ "Confidence" SG_ 1510 APS_A_turboMaxTemperature 0;
BA_ "GenSigSNA" SG_ 1510 APS_A_turboMaxTemperature "128";
BA_ "Confidence" SG_ 1510 APS_A_turboProbeType 0;
BA_ "GenSigSNA" SG_ 1510 APS_A_turboProbeType "63";
BA_ "Confidence" SG_ 1510 APS_B_turboMaxTemperature 0;
BA_ "GenSigSNA" SG_ 1510 APS_B_turboMaxTemperature "128";
BA_ "Confidence" SG_ 1510 APS_B_turboProbeType 0;
BA_ "GenSigSNA" SG_ 1510 APS_B_turboProbeType "63";
BA_ "SystemSignalLongSymbol" SG_ 848 APS_w245_eloopRxFromUnexpectedSo "APS_w245_eloopRxFromUnexpectedSourceMAC";
BA_ "SystemSignalLongSymbol" SG_ 848 APS_w246_ethloopSwitchPortLinkDo "APS_w246_ethloopSwitchPortLinkDown";
BA_ "SystemSignalLongSymbol" SG_ 848 APS_w250_ethloopSwitchMemUsageTo "APS_w250_ethloopSwitchMemUsageTooHighPort2";
BA_ "SystemSignalLongSymbol" SG_ 848 APS_w251_ethloopSwitchMemUsageTo "APS_w251_ethloopSwitchMemUsageTooHighPort3";
BA_ "Confidence" SG_ 1465 DAS_alertID 1;
BA_ "Confidence" SG_ 1465 DAS_alertState 1;
BA_ "Confidence" SG_ 1465 DAS_sw073_escalateLDWreason 1;
BA_ "Confidence" SG_ 1465 DAS_sw073_freespaceLeftC0 1;
BA_ "Confidence" SG_ 1465 DAS_sw073_freespaceRightC0 1;
BA_ "Confidence" SG_ 1465 DAS_sw073_freespaceLeftC1 1;
BA_ "Confidence" SG_ 1465 DAS_sw073_freespaceRightC1 1;
BA_ "Confidence" SG_ 1465 DAS_sw073_freespaceLeftFarZ 1;
BA_ "Confidence" SG_ 1465 DAS_sw073_freespaceRightFarZ 1;
BA_ "Confidence" SG_ 1497 DAS_carLogMultiplexer 1;
BA_ "Confidence" SG_ 1497 DAS_radarTarget5_dx 0;
BA_ "Confidence" SG_ 1497 DAS_radarTarget1_dx 0;
BA_ "Confidence" SG_ 1497 DAS_radarTarget1_VxRel 0;
BA_ "Confidence" SG_ 1497 DAS_mobileyeVehAebFlag 0;
BA_ "Confidence" SG_ 1497 DAS_mobileyePedAebFlag 0;
BA_ "Confidence" SG_ 1497 DAS_mobileyeIPSOapproved 0;
BA_ "Confidence" SG_ 1497 DAS_fcmSteeringOverride 0;
BA_ "Confidence" SG_ 1497 DAS_fcmCollisionStage3Checks 0;
BA_ "Confidence" SG_ 1497 DAS_fcmThreatAssesmentMode 0;
BA_ "Confidence" SG_ 1497 DAS_constructionArea 0;
BA_ "Confidence" SG_ 1497 DAS_restrictionLowSpeedTraffic 0;
BA_ "Confidence" SG_ 1497 DAS_associated_rad_object 0;
BA_ "Confidence" SG_ 1497 DAS_LC_handsOnReason 0;
BA_ "Confidence" SG_ 1497 DAS_ACC_camStatus 0;
BA_ "Confidence" SG_ 1497 DAS_aeb_not_activating_reason 0;
BA_ "Confidence" SG_ 1497 DAS_handsOnDetected 0;
BA_ "GenSigSNA" SG_ 1497 DAS_handsOnDetected "0";
BA_ "Confidence" SG_ 1497 DAS_driveOnNavUnavailableReason 0;
BA_ "Confidence" SG_ 1497 DAS_accUnavailableReason 0;
BA_ "Confidence" SG_ 1497 DAS_pmmNotActivatingReason 0;
BA_ "Confidence" SG_ 1497 DAS_desiredTarget_dx 0;
BA_ "GenSigSNA" SG_ 1497 DAS_desiredTarget_dx "255";
BA_ "Confidence" SG_ 1497 DAS_radarTarget2_dx 0;
BA_ "Confidence" SG_ 1497 DAS_radarTarget3_dx 0;
BA_ "Confidence" SG_ 1497 DAS_radarTarget4_dx 0;
BA_ "Confidence" SG_ 1497 DAS_closestInLaneTargetDx 0;
BA_ "Confidence" SG_ 1497 DAS_secondInLaneTargetDx 0;
BA_ "Confidence" SG_ 1497 DAS_closestLeftLaneTargetDx 0;
BA_ "Confidence" SG_ 1497 DAS_closestRightLaneTargetDx 0;
BA_ "Confidence" SG_ 1497 DAS_closestInLaneTargetVxRel 0;
BA_ "Confidence" SG_ 1337 DAS_infoIndex 1;
BA_ "Confidence" SG_ 1337 DAS_infoBuildType 0;
BA_ "Confidence" SG_ 1337 DAS_infoBuildConfigID 0;
BA_ "Confidence" SG_ 1337 DAS_infoHardwareID 0;
BA_ "Confidence" SG_ 1337 DAS_infoComponentID 0;
BA_ "Confidence" SG_ 1337 DAS_infoPcbaID 0;
BA_ "Confidence" SG_ 1337 DAS_infoAssemblyID 0;
BA_ "Confidence" SG_ 1337 DAS_infoUsageID 0;
BA_ "Confidence" SG_ 1337 DAS_infoSubUsageID 0;
BA_ "Confidence" SG_ 1337 DAS_infoApplicationCRC 0;
BA_ "Confidence" SG_ 1337 DAS_infoAppGitHashBytes 0;
BA_ "Confidence" SG_ 1337 DAS_infoBootGitHashBytes 0;
BA_ "Confidence" SG_ 569 DAS_leftLaneExists 0;
BA_ "Confidence" SG_ 569 DAS_rightLaneExists 0;
BA_ "Confidence" SG_ 569 DAS_virtualLaneWidth 0;
BA_ "Confidence" SG_ 569 DAS_virtualLaneViewRange 0;
BA_ "Confidence" SG_ 569 DAS_virtualLaneC0 0;
BA_ "Confidence" SG_ 569 DAS_virtualLaneC1 0;
BA_ "Confidence" SG_ 569 DAS_virtualLaneC2 0;
BA_ "Confidence" SG_ 569 DAS_virtualLaneC3 0;
BA_ "Confidence" SG_ 569 DAS_leftLineUsage 0;
BA_ "Confidence" SG_ 569 DAS_rightLineUsage 0;
BA_ "Confidence" SG_ 569 DAS_leftFork 0;
BA_ "Confidence" SG_ 569 DAS_rightFork 0;
BA_ "Confidence" SG_ 569 DAS_lanesCounter 0;
BA_ "Confidence" SG_ 921 DAS_autopilotState 0;
BA_ "GenSigSNA" SG_ 921 DAS_autopilotState "15";
BA_ "Confidence" SG_ 921 DAS_blindSpotRearLeft 0;
BA_ "GenSigSNA" SG_ 921 DAS_blindSpotRearLeft "3";
BA_ "Confidence" SG_ 921 DAS_blindSpotRearRight 0;
BA_ "GenSigSNA" SG_ 921 DAS_blindSpotRearRight "3";
BA_ "Confidence" SG_ 921 DAS_fusedSpeedLimit 0;
BA_ "GenSigSNA" SG_ 921 DAS_fusedSpeedLimit "0";
BA_ "Confidence" SG_ 921 DAS_suppressSpeedWarning 0;
BA_ "Confidence" SG_ 921 DAS_summonObstacle 0;
BA_ "Confidence" SG_ 921 DAS_summonClearedGate 0;
BA_ "Confidence" SG_ 921 DAS_visionOnlySpeedLimit 0;
BA_ "GenSigSNA" SG_ 921 DAS_visionOnlySpeedLimit "0";
BA_ "Confidence" SG_ 921 DAS_heaterState 0;
BA_ "GenSigSNA" SG_ 921 DAS_heaterState "0";
BA_ "Confidence" SG_ 921 DAS_forwardCollisionWarning 0;
BA_ "GenSigSNA" SG_ 921 DAS_forwardCollisionWarning "3";
BA_ "Confidence" SG_ 921 DAS_autoparkReady 0;
BA_ "Confidence" SG_ 921 DAS_autoParked 0;
BA_ "Confidence" SG_ 921 DAS_autoparkActive 0;
BA_ "Confidence" SG_ 921 DAS_summonFwdLeashReached 0;
BA_ "Confidence" SG_ 921 DAS_summonRvsLeashReached 0;
BA_ "Confidence" SG_ 921 DAS_lssState 0;
BA_ "Confidence" SG_ 921 DAS_sideCollisionAvoid 0;
BA_ "GenSigSNA" SG_ 921 DAS_sideCollisionAvoid "3";
BA_ "Confidence" SG_ 921 DAS_sideCollisionWarning 0;
BA_ "Confidence" SG_ 921 DAS_sideCollisionInhibit 0;
BA_ "Confidence" SG_ 921 DAS_laneDepartureWarning 0;
BA_ "GenSigSNA" SG_ 921 DAS_laneDepartureWarning "5";
BA_ "Confidence" SG_ 921 DAS_fleetSpeedState 0;
BA_ "Confidence" SG_ 921 DAS_autopilotHandsOnState 0;
BA_ "GenSigSNA" SG_ 921 DAS_autopilotHandsOnState "15";
BA_ "Confidence" SG_ 921 DAS_autoLaneChangeState 0;
BA_ "GenSigSNA" SG_ 921 DAS_autoLaneChangeState "31";
BA_ "Confidence" SG_ 921 DAS_summonAvailable 0;
BA_ "Confidence" SG_ 921 DAS_statusCounter 0;
BA_ "Confidence" SG_ 921 DAS_statusChecksum 0;
BA_ "Confidence" SG_ 905 DAS_accSpeedLimit 0;
BA_ "GenSigSNA" SG_ 905 DAS_accSpeedLimit "511";
BA_ "Confidence" SG_ 905 DAS_versionIdentifier 0;
BA_ "Confidence" SG_ 905 DAS_pmmObstacleSeverity 0;
BA_ "GenSigSNA" SG_ 905 DAS_pmmObstacleSeverity "7";
BA_ "Confidence" SG_ 905 DAS_pmmLoggingRequest 0;
BA_ "Confidence" SG_ 905 DAS_activationFailureStatus 0;
BA_ "Confidence" SG_ 905 DAS_pmmUltrasonicsFaultReason 0;
BA_ "Confidence" SG_ 905 DAS_pmmRadarFaultReason 0;
BA_ "Confidence" SG_ 905 DAS_pmmSysFaultReason 0;
BA_ "Confidence" SG_ 905 DAS_pmmCameraFaultReason 0;
BA_ "Confidence" SG_ 905 DAS_ACC_report 0;
BA_ "Confidence" SG_ 905 DAS_relaxCruiseLimits 0;
BA_ "Confidence" SG_ 905 DAS_csaState 0;
BA_ "Confidence" SG_ 905 DAS_radarTelemetry 0;
BA_ "Confidence" SG_ 905 DAS_robState 0;
BA_ "Confidence" SG_ 905 DAS_driverInteractionLevel 0;
BA_ "Confidence" SG_ 905 DAS_ppOffsetDesiredRamp 0;
BA_ "Confidence" SG_ 905 DAS_longCollisionWarning 0;
BA_ "GenSigSNA" SG_ 905 DAS_longCollisionWarning "15";
BA_ "Confidence" SG_ 905 DAS_status2Counter 0;
BA_ "Confidence" SG_ 905 DAS_status2Checksum 0;
BA_ "Confidence" SG_ 586 DAS_autosteerVehiclesUsage 0;
BA_ "Confidence" SG_ 586 DAS_autosteerHPPUsage 0;
BA_ "Confidence" SG_ 586 DAS_autosteerNavigationUsage 0;
BA_ "Confidence" SG_ 586 DAS_autosteerModelUsage 0;
BA_ "Confidence" SG_ 586 DAS_autosteerBottsDotsUsage 0;
BA_ "Confidence" SG_ 586 DAS_offsetSide 0;
BA_ "Confidence" SG_ 586 DAS_roadSurfaceType 0;
BA_ "GenSigSNA" SG_ 586 DAS_roadSurfaceType "0";
BA_ "Confidence" SG_ 586 DAS_autosteerHealthAnomalyLevel 0;
BA_ "Confidence" SG_ 586 DAS_autosteerHealthState 0;
BA_ "Confidence" SG_ 586 DAS_lastLinePreferenceReason 0;
BA_ "Confidence" SG_ 586 DAS_plannerState 0;
BA_ "Confidence" SG_ 586 DAS_lastAutosteerAbortReason 0;
BA_ "Confidence" SG_ 586 DAS_devAppInterfaceEnabled 0;
BA_ "Confidence" SG_ 586 DAS_navAvailable 0;
BA_ "Confidence" SG_ 586 DAS_navDistance 0;
BA_ "Confidence" SG_ 586 DAS_accSmartSpeedActive 0;
BA_ "Confidence" SG_ 586 DAS_accSmartSpeedState 0;
BA_ "GenSigSNA" SG_ 586 DAS_accSmartSpeedState "7";
BA_ "Confidence" SG_ 586 DAS_ulcInProgress 0;
BA_ "Confidence" SG_ 586 DAS_trafficAwareSetSpeedInUse 0;
BA_ "Confidence" SG_ 586 DAS_isaSystemState 0;
BA_ "Confidence" SG_ 586 DAS_behaviorType 0;
BA_ "Confidence" SG_ 586 DAS_ulcType 0;
BA_ "Confidence" SG_ 586 DAS_rearVehDetectedThisCycle 0;
BA_ "Confidence" SG_ 586 DAS_rearLeftVehDetectedCurrent 0;
BA_ "Confidence" SG_ 586 DAS_rearRightVehDetectedTrip 0;
BA_ "Confidence" SG_ 586 DAS_rearLeftVehDetectedTrip 0;
VAL_ 1020 APP_decisionTemperature 0 "UNKNOWN" ;
VAL_ 1020 APP_pascalTemperature 0 "UNKNOWN" ;
VAL_ 1020 APP_parkerATemperature 0 "UNKNOWN" ;
VAL_ 1020 APP_parkerBTemperature 0 "UNKNOWN" ;
VAL_ 1020 APP_pascalExtTemperature 0 "UNKNOWN" ;
VAL_ 1020 APP_parkerExtTemperature 0 "UNKNOWN" ;
VAL_ 1020 APP_pascalHeaterDecision 1 "ON" 0 "OFF" ;
VAL_ 1018 APP_mainCameraLUX 255 "SNA" 254 "SATURATED" ;
VAL_ 1018 APP_narrowCameraLUX 255 "SNA" 254 "SATURATED" ;
VAL_ 1018 APP_fisheyeCameraLUX 255 "SNA" 254 "SATURATED" ;
VAL_ 1018 APP_lRepeatCameraLUX 255 "SNA" 254 "SATURATED" ;
VAL_ 1018 APP_rRepeatCameraLUX 255 "SNA" 254 "SATURATED" ;
VAL_ 1018 APP_lPillarCameraLUX 255 "SNA" 254 "SATURATED" ;
VAL_ 1018 APP_rPillarCameraLUX 255 "SNA" 254 "SATURATED" ;
VAL_ 1018 APP_backupCameraLUX 255 "SNA" 254 "SATURATED" ;
VAL_ 843 APP_frontLeftParkAssist 255 "SNA" ;
VAL_ 843 APP_frontLeftMiddleParkAssist 255 "SNA" ;
VAL_ 843 APP_frontMiddleParkAssist 255 "SNA" ;
VAL_ 843 APP_frontRightMiddleParkAssist 255 "SNA" ;
VAL_ 843 APP_frontRightParkAssist 255 "SNA" ;
VAL_ 843 APP_parkAssistStatus 3 "SNA" 2 "TEMPORARY_FAILURE" 1 "ENABLED" 0 "DISABLED" ;
VAL_ 1353 APP_infoIndex 3 "AP_BOOT_COUNT" 2 "AP_GITHASH" 1 "FW_GITHASH" 0 "AP_BUILD_TYPE" ;
VAL_ 1353 APP_buildType 3 "AP_BUILDTYPE_REPO" 1 "AP_BUILDTYPE_LOCAL" 0 "AP_BUILDTYPE_SIGNED" ;
VAL_ 907 APP_rearLeftParkAssist 255 "SNA" ;
VAL_ 907 APP_rearLeftMiddleParkAssist 255 "SNA" ;
VAL_ 907 APP_rearMiddleParkAssist 255 "SNA" ;
VAL_ 907 APP_rearRightMiddleParkAssist 255 "SNA" ;
VAL_ 907 APP_rearRightParkAssist 255 "SNA" ;
VAL_ 605 APP_tcFeatureState 3 "TC_ACTIVE" 2 "TC_AVAILABLE" 1 "TC_UNAVAILABLE" 0 "TC_DISABLED" ;
VAL_ 605 APP_tcStateMachine 6 "TCSM_CONTINUING" 5 "TCSM_STOPPED" 4 "TCSM_STOPPING" 3 "TCSM_WARNING" 2 "TCSM_AWARE" 1 "TCSM_STANDBY" 0 "TCSM_DISABLED" ;
VAL_ 605 APP_tcControlSource 3 "TC_SOURCE_MAP_AND_VISION" 2 "TC_SOURCE_VISION" 1 "TC_SOURCE_MAP" 0 "TC_SOURCE_NONE" ;
VAL_ 605 APP_tcControlType 22 "TC_TYPE_T_ARM" 21 "TC_TYPE_BEV_JUNCTION" 20 "TC_TYPE_T_IMPLICIT_BY_GEOM" 19 "TC_TYPE_T_IMPLICIT_BY_NAME" 18 "TC_TYPE_T_IMPLICIT" 17 "TC_TYPE_NO_STOP" 16 "TC_TYPE_BIKE_MERGE_FROM_RIGHT" 15 "TC_TYPE_BIKE_MERGE_FROM_LEFT" 14 "TC_TYPE_ALL_WAY_STOP_SIGN" 13 "TC_TYPE_TRAFFIC_RULE" 12 "TC_TYPE_SPEED_HUMP" 11 "TC_TYPE_SPEED_BUMP" 10 "TC_TYPE_RAMP_METER" 9 "TC_TYPE_PEDESTRIAN_CROSSING" 8 "TC_TYPE_SUICIDE_LEFT" 7 "TC_TYPE_KEEP_CLEAR_EXIT" 6 "TC_TYPE_KEEP_CLEAR_ENTER" 5 "TC_TYPE_CROSSWALK" 4 "TC_TYPE_YIELD" 3 "TC_TYPE_TRAFFIC_LIGHT" 2 "TC_TYPE_STOP_SIGN" 1 "TC_TYPE_UNKNOWN" 0 "TC_TYPE_INVALID" ;
VAL_ 605 APP_tcControlDistance 255 "SNA" ;
VAL_ 605 APP_tcControlLightState 6 "TC_LIGHTSTATE_OTHER" 5 "TC_LIGHTSTAET_WHITE" 4 "TC_LIGHTSTATE_OFF" 3 "TC_LIGHTSTATE_YELLOW" 2 "TC_LIGHTSTATE_GREEN" 1 "TC_LIGHTSTATE_RED" 0 "TC_LIGHTSTATE_NONE" ;
VAL_ 605 APP_tcContinuationReason 13 "TC_CONTINUE_CONTROL_UNAVAILABLE" 12 "TC_CONTINUE_SUMMON_TIMEOUT" 11 "TC_CONTINUE_CLEAR_TO_GO" 10 "TC_CONTINUE_WARNING_TIMEOUT" 9 "TC_CONTINUE_INVALID_MAP_OR_VISION_CONTROL" 8 "TC_CONTINUE_PASSED_STOP" 7 "TC_CONTINUE_ASSUMED_DRIVER_STOPPED" 6 "TC_CONTINUE_AP_ACTIVATED_ON_HARD_STOP" 5 "TC_CONTINUE_VISION_SIGNALS" 4 "TC_CONTINUE_REQUIRED_DECEL_TOO_HIGH" 3 "TC_CONTINUE_USER_INPUT_ON_RED" 2 "TC_CONTINUE_USER_INPUT_ON_GREEN" 1 "TC_CONTINUE_GREEN_LIGHT_WITH_CIPV" 0 "TC_CONTINUE_NONE" ;
VAL_ 605 APP_tcConfirmationType 2 "TC_CONFIRM_PEDAL" 1 "TC_CONFIRM_STALK" 0 "TC_CONFIRM_NONE" ;
VAL_ 605 APP_tcWarningSuppressionReason 18 "TC_WARNING_SUPPRESS_TOO_FAR_FROM_PREDICTED_JUNCTION" 17 "TC_WARNING_SUPPRESS_NOT_SUPPORTED_BY_MEASUREMENTS" 16 "TC_WARNING_SUPPRESS_NO_ASSOCIATED_VISION_LINE" 15 "TC_WARNING_SUPPRESS_AMBIGUOUS_VISION_TYPE" 14 "TC_WARNING_SUPPRESS_CIPV_DID_NOT_STOP" 13 "TC_WARNING_SUPPRESS_STALE_SIGN_DETECTION" 12 "TC_WARNING_SUPPRESS_WRONG_MAP_TYPE" 11 "TC_WARNING_SUPPRESS_LIGHT_UNASSOCIATED" 10 "TC_WARNING_SUPPRESS_CIPV_CONTINUING" 9 "TC_WARNING_SUPPRESS_PEDAL_OVERRIDE" 8 "TC_WARNING_SUPPRESS_LOCALIZATION_DEGRADED" 7 "TC_WARNING_SUPPRESS_HARD_TURN" 6 "TC_WARNING_SUPPRESS_ASSUMED_YELLOW" 5 "TC_WARNING_SUPPRESS_DRIVER_SLOWING_DOWN" 4 "TC_WARNING_SUPPRESS_BELOW_MIN_SPEED" 3 "TC_WARNING_SUPPRESS_SLOWDOWN_PLANNED" 2 "TC_WARNING_SUPPRESS_INSUFFICIENT_DATA" 1 "TC_WARNING_SUPPRESS_FEATURE_DISABLED" 0 "TC_WARNING_SUPPRESS_NONE" ;
VAL_ 605 APP_tcUnavailableReason 9 "AP_UNAVAILBLE_SUN_GLARE_ON_ROAD_RESTRICTED" 8 "AP_UNAVAILBLE_CAMERA_BLINDED_ON_ROAD_RESTRICTED" 7 "AP_UNAVAILBLE_GPS_DEGRADED" 6 "AP_UNAVAILBLE_ROAD_ESTIMATOR_UNHEALTHY" 5 "AP_UNAVAILBLE_SUN_GLARE" 4 "AP_UNAVAILBLE_CAMERA_BLINDED" 3 "AP_UNAVAILBLE_ROAD_CLASS" 2 "AP_UNAVAILBLE_LOST_MAP_LOCALIZATION" 1 "AP_UNAVAILBLE_MCU_DISABLED" 0 "AP_UNAVAILBLE_NONE" ;
VAL_ 859 APP_visionOcsStateRaw 3 "ADULT" 2 "CHILD" 1 "EMPTY" 0 "UNKNOWN" ;
VAL_ 859 APP_visionOcsEmptyProbRaw 255 "SNA" ;
VAL_ 859 APP_visionOcsChildProbRaw 255 "SNA" ;
VAL_ 859 APP_visionOcsAdultProbRaw 255 "SNA" ;
VAL_ 859 APP_visionOcsFrontPasClsVisionSt 3 "ADULT" 2 "CHILD" 1 "EMPTY" 0 "UNKNOWN" ;
VAL_ 637 APS_eacAllow 3 "APS_EAC_SNA" 2 "APS_EAC_RESERVED" 1 "APS_EAC_ALLOW" 0 "APS_EAC_INHIBIT" ;
VAL_ 992 APS_A_lowPowerRequest 5 "APS_LOW_POWER_COLD_RESET" 4 "APS_LOW_POWER_SOC_WARM_RESET" 3 "APS_LOW_POWER_AP_WARM_RESET" 2 "APS_LOW_POWER_OFF" 1 "APS_LOW_POWER_SUSPEND" 0 "APS_LOW_POWER_NONE" ;
VAL_ 992 APS_A_lowPowerRequestor 10 "APS_LOW_POWER_REQ_COUNT" 9 "APS_LOW_POWER_REQ_SGK_PGOOD_IRQ" 8 "APS_LOW_POWER_REQ_SGK_CONSOLE" 7 "APS_LOW_POWER_REQ_SGK_SLEEP" 6 "APS_LOW_POWER_REQ_SGK_UDS" 5 "APS_LOW_POWER_REQ_SGK_BRIDGE" 4 "APS_LOW_POWER_REQ_SGK_FM" 3 "APS_LOW_POWER_REQ_SGK_POWER" 2 "APS_LOW_POWER_REQ_AP_MAILBOX" 1 "APS_LOW_POWER_REQ_AP_ATF" 0 "APS_LOW_POWER_REQ_NONE" ;
VAL_ 992 APS_B_lowPowerRequest 5 "APS_LOW_POWER_COLD_RESET" 4 "APS_LOW_POWER_SOC_WARM_RESET" 3 "APS_LOW_POWER_AP_WARM_RESET" 2 "APS_LOW_POWER_OFF" 1 "APS_LOW_POWER_SUSPEND" 0 "APS_LOW_POWER_NONE" ;
VAL_ 992 APS_B_lowPowerRequestor 10 "APS_LOW_POWER_REQ_COUNT" 9 "APS_LOW_POWER_REQ_SGK_PGOOD_IRQ" 8 "APS_LOW_POWER_REQ_SGK_CONSOLE" 7 "APS_LOW_POWER_REQ_SGK_SLEEP" 6 "APS_LOW_POWER_REQ_SGK_UDS" 5 "APS_LOW_POWER_REQ_SGK_BRIDGE" 4 "APS_LOW_POWER_REQ_SGK_FM" 3 "APS_LOW_POWER_REQ_SGK_POWER" 2 "APS_LOW_POWER_REQ_AP_MAILBOX" 1 "APS_LOW_POWER_REQ_AP_ATF" 0 "APS_LOW_POWER_REQ_NONE" ;
VAL_ 1510 APS_A_cam12v0Voltage 4095 "SNA" ;
VAL_ 1510 APS_B_cam12v0Voltage 4095 "SNA" ;
VAL_ 1510 APS_A_turboMaxTemperature -128 "SNA" ;
VAL_ 1510 APS_A_turboProbeType 63 "SNA" ;
VAL_ 1510 APS_B_turboMaxTemperature -128 "SNA" ;
VAL_ 1510 APS_B_turboProbeType 63 "SNA" ;
VAL_ 1465 DAS_alertID 232 "w232_laneChangeRequested" 231 "w231_idfEvent" 230 "w230_alcUltrasoundBlocked" 229 "w229_alcUltrasoundDamaged" 228 "w228_DEPRECATED" 227 "w227_virtualWallBlocked" 226 "w226_lcCamCalNeededSpeedLmt" 225 "w225_lcDegradedVisSpeedLmt" 224 "w224_accCameraCalibration" 223 "w223_accObjectInPath" 222 "w222_accCameraBlind" 221 "w221_accRadarBlind" 220 "w220_lcTempUnavailableRoad" 219 "w219_lcTempUnavailableSpeed" 218 "w218_lcSpeedExceededLimit" 217 "w217_lcUnavailableSpeeding" 216 "w216_driverOverriding" 215 "w215_contDriverNotIntracting" 214 "w214_driverNotIntracting" 213 "w213_autosteerStruckOut" 212 "w212_lcUnavailableStrikeOut" 211 "w211_accNoSeatBelt" 210 "w210_camObstrcted" 209 "w209_autoSummonRequest" 208 "w208_rackDetected" 207 "w207_autosteerUnavailable" 206 "w206_autosteerNotEnabled" 205 "w205_apcFinalRear" 204 "w204_apcFinalFront" 203 "w203_apcActivation" 202 "w202_scwNoisyEnvironment" 201 "w201_lcAborting" 200 "w200_lcSlowdown" 199 "w199_apcAbort" 198 "w198_tsrUnavailable" 197 "w197_redLightWarning" 196 "w196_stopSignWarning" 195 "w195_scwUnavailable" 194 "w194_accDriverResumeRqrd" 193 "w193_camWindshieldUnclean" 181 "w181_rRepeatCamCalSaved" 180 "w180_lRepeatCamCalSaved" 179 "w179_rPillarCamCalSaved" 178 "w178_lPillarCamCalSaved" 177 "w177_fisheyeCamCalSaved" 175 "w175_rRepeatCamExtNotCal" 174 "w174_lRepeatCamExtNotCal" 173 "w173_rPillarCamExtNotCal" 172 "w172_lPillarCamExtNotCal" 171 "w171_fisheyeCamExtNotCal" 144 "w144_selfieCamInitFault" 143 "w143_IDF_event" 142 "w142_fwdCamPitchProblem" 141 "w141_ECU_Thermal_Issue" 140 "w140_backupCamInitFault" 139 "w139_rRepeatCamInitFault" 138 "w138_lRepeatCamInitFault" 137 "w137_rPillarCamInitFault" 136 "w136_lPillarCamInitFault" 135 "w135_fisheyeCamInitFault" 134 "w134_narrowCamInitFault" 133 "w133_mainCamInitFault" 132 "w132_narrowCamCalSaved" 131 "w131_mainCamCalSaved" 130 "w130_narrowCamExtNotCal" 129 "w129_mainCamExtNotCal" 106 "w106_torsionBarCalibrated" 105 "w105_DEPRECATED" 104 "w104_DEPRECATED" 103 "w103_robExperimentalAEB" 102 "w102_DEPRECATED" 101 "w101_DEPRECATED" 100 "w100_DEPRECATED" 99 "w099_DEPRECATED" 98 "w098_DEPRECATED" 97 "w097_DEPRECATED" 96 "w096_DEPRECATED" 95 "w095_DEPRECATED" 94 "w094_DEPRECATED" 93 "w093_DEPRECATED" 92 "w092_DEPRECATED" 91 "w091_DEPRECATED" 90 "w090_DEPRECATED" 89 "w089_DEPRECATED" 88 "w088_DEPRECATED" 87 "w087_DEPRECATED" 86 "w086_robCollision" 85 "w085_pmmSteering" 84 "w084_pmmIPSO" 83 "w083_inPathRADObject" 82 "w082_inPathFSviolation" 81 "w081_pmmActiveBraking" 80 "w080_accFailedActivation" 79 "w079_edrAvailable" 78 "w078_pmmActive2" 77 "w077_pmmActive" 76 "w076_mobilEyeSetC" 75 "w075_scMia" 74 "w074_inPathStationaryObst" 73 "w073_issueEscalatedLDW" 72 "w072_selfparkComplete" 71 "w071_selfparkStarted" 70 "w070_apcIncompleteCal" 69 "w069_apcSpaceMasked" 68 "w068_vlInconsistency" 67 "w067_steeringAlignment" 66 "w066_deserializerLockLost" 65 "w065_deserializerOvercurrent" 64 "w064_epasMia" 63 "w063_parkVersionMismatch" 62 "w062_radcAlignment" 61 "w061_airSuspensionMia" 60 "w060_fcw_event" 59 "w059_parkMia" 58 "w058_epbMia" 57 "w057_mcuMia" 56 "w056_diMia" 55 "w055_radcVersionMismatch" 54 "w054_camAutofix" 53 "w053_radcCommIssue" 52 "w052_radcSensorIssue" 51 "w051_radcEcuIssue" 50 "w050_aeb_event" 49 "w049_eyeqVersionMismatch" 48 "w048_DAS_Features_Disabled" 47 "w047_edrEvent" 46 "w046_eepromRecordAbsent" 45 "w045_radMia" 44 "w044_appMobileyeFailure" 43 "w043_camLongRunTime" 42 "w042_autopilotAborting" 41 "w041_autopilotRateSaturated" 40 "w040_autopilotAngleSaturated" 39 "w039_sdm_rcm_Mia" 38 "w038_camFailure" 37 "w037_camTacIssue" 36 "w036_bdyMia" 35 "w035_espMia" 34 "w034_sccmMia" 33 "w033_gtwMia" 32 "w032_canTxError" 31 "w031_canRxError" 30 "w030_Heater_Issue" 29 "w029_spi_tx_error" 28 "w028_spi_rx_error" 27 "w027_ECU_Reset_Fault" 26 "w026_ECU_timingIssue" 25 "w025_LC_Steering_Override" 24 "w024_ECU_Watchdog_Reset" 23 "w023_ECU_Cam_Statemismatc" 22 "w022_ECU_EEPROM_Failure" 21 "w021_ECU_Temperature_Issue" 20 "w020_ECU_checkstopError" 19 "w019_ECU_Stack_Overflow" 18 "w018_ECU_Power_Issue" 17 "w017_Cam_Msg_MIA" 16 "w016_aeb_e_event" 15 "w015_Camera_Failsafes" 14 "w014_swAssert" 13 "w013_Cam_Watchdog" 12 "w012_Cam_BootFailure" 11 "w011_scaEvent" 10 "w010_radcCalibIssue" 9 "w009_aebFault" 8 "w008_parkDisabled" 7 "w007_ahlbDisabled" 6 "w006_aebCancelled" 5 "w005_fcwCancelled" 4 "w004_accDisabled" 3 "w003_isaDisabled" 2 "w002_ldwDisabled" 0 "ALERT_DO_NOT_USE_ZERO" ;
VAL_ 1465 DAS_alertState 1 "SET" 0 "CLEARED" ;
VAL_ 1465 DAS_sw073_escalateLDWreason 4 "SELFIE" 3 "STW_TAKEOVER" 2 "DOUBLE_PULL" 1 "SINGLE_PULL" 0 "NONE" ;
VAL_ 1497 DAS_carLogMultiplexer 3 "PROFILER" 2 "FCM" 1 "RADAR" 0 "FEATURE_STATE" ;
VAL_ 1497 DAS_radarTarget5_dx 0 "NO_TARGET" ;
VAL_ 1497 DAS_radarTarget1_dx 0 "NO_TARGET" ;
VAL_ 1497 DAS_radarTarget1_VxRel 0 "NO_TARGET" ;
VAL_ 1497 DAS_associated_rad_object 3 "ACC1" 2 "ACC5" 1 "OTHER" 0 "NONE" ;
VAL_ 1497 DAS_LC_handsOnReason 63 "VISUAL_DCAS_BOUNDARY_CONDITION" 62 "VISUAL_DCAS_STRICT_PHONE_USE" 61 "VISUAL_DCAS_EYES_ON_REQUEST_FAST" 60 "VISUAL_EYE_GAZE_AVERSION" 59 "VISUAL_NO_EYE_GAZE_DEVIATION" 58 "CHIME1_DCAS_STRICT_PHONE_USE" 57 "VISUAL_DCAS_EYES_ON_REQUEST" 56 "CHIME1_DCAS_EYES_ON_REQUEST_FAST" 55 "CHIME1_DCAS_EYES_ON_REQUEST" 54 "CHIME1_NO_EYE_GAZE_DEVIATION" 53 "VISUAL_ATTN_MONITORING_UNAVAILABLE" 52 "VISUAL_DRIVER_HANDS_NOT_READY" 51 "VISUAL_TIMEOUT_SUNGLASSES" 50 "CHIME1_REACHING_AFTER_AP_ACTIVATION" 49 "VISUAL_DRIVER_POSSIBLY_DISTRACTED" 48 "VISUAL_DRIVER_LOW_ATTENTION_SCORE" 47 "VISUAL_DRIVER_LOSS_OF_ATTENTION" 46 "VISUAL_VRU_FAILSAFE" 45 "VISUAL_VRU_IN_DRIVE_SPACE" 44 "CHIME1_UPCOMING_TRAFFIC_CONTROL" 43 "CHIME1_HANDS_OFF_AFTER_AP_ACTIVATION" 42 "VISUAL_UPCOMING_TRAFFIC_CONTROL" 41 "CHIME1_DISTRACTED_AFTER_AP_ACTIVATION" 40 "VISUAL_DRIVER_STATE_UNKNOWN" 39 "VISUAL_TIMEOUT_DRIVER_NOT_LIVELY" 38 "VISUAL_TIMEOUT_TORQUE_OFFSET_UNCALIBRATED" 37 "CHIME1_REFERENCE_LATERAL_ERROR" 36 "CHIME1_STREET_CAR" 35 "CHIME1_SEALED_MERGE_WARNING" 34 "CHIME1_CAUTION_LIGHTS" 33 "CHIME1_CAPTIVE_EXIT" 32 "CHIME1_CRITICAL_TRAFFIC_CONTROL" 31 "VISUAL_POOR_VISIBILITY" 30 "CHIME1_DRIVER_DISTRACTED" 29 "DEFEAT_DEVICE_DETECTED" 28 "VISUAL_TRAFFIC_CONTROLS" 27 "CHIME1_EXTREME_WEATHER" 26 "VISUAL_POOR_WEATHER" 25 "VISUAL_STOP_AND_GO" 24 "VISUAL_TIMEOUT_HOMOLOGATION" 23 "VISUAL_ULC_REQUEST" 22 "CHIME1_TOLL_BOOTH" 21 "CHIME1_STATIONARY_RADAR" 20 "CHIME1_DRIVABLE_SPACE_VIOLATION" 19 "CHIME1_RE_DEGRADED_MEASUREMENTS" 18 "CHIME1_NO_LINES" 17 "VISUAL_ALC" 16 "VISUAL_LATERAL_ACCELERATION" 15 "VISUAL_TIMEOUT_ACCELERATOR" 14 "VISUAL_TIMEOUT_RESTRICTED" 13 "VISUAL_TIMEOUT_NO_CIPV" 12 "VISUAL_TIMEOUT_CIPV" 11 "VISUAL_TIMEOUT_CUTOUT_CIPV" 10 "VISUAL_TIMEOUT_CONSTRUCTION" 9 "VISUAL_TIMEOUT_LOW_SPEED" 8 "VISUAL_TIMEOUT_MED_SPEED" 7 "VISUAL_TIMEOUT_HI_SPEED" 6 "VISUAL_TIMEOUT_LONG_TERM" 5 "VISUAL_DRIVER_NOT_PRESENT" 4 "VISUAL_FUSION_MODEL" 3 "VISUAL_FUSION_NAV" 2 "CHIME1_CONSTRUCTION" 1 "CHIME1_ANGLE_SATURATION" 0 "LC_HANDS_ON_REASON_NONE" ;
VAL_ 1497 DAS_ACC_camStatus 3 "ACC_CAM_STATUS_FAULT" 2 "ACC_CAM_STATUS_SQUINTING" 1 "ACC_CAM_STATUS_BLIND" 0 "ACC_CAM_STATUS_HEALTHY" ;
VAL_ 1497 DAS_aeb_not_activating_reason 22 "LCM_AEB_SENSORS_DO_NOT_AGREE" 21 "LCM_AEB_NOT_RADAR_CIPV" 20 "LCM_AEB_LANE_ASSIGNMENT_AGE" 19 "LCM_AEB_COLLISION_COURSE_TIME" 18 "LCM_AEB_TRACK_CONSISTENCY" 17 "LCM_AEB_DRIVABLE_SPACE" 16 "LCM_AEB_PATH_OVERLAP" 15 "LCM_AEB_RAD_NOT_ASSOCIATED" 14 "LCM_AEB_CAM_NOT_ASSOCIATED" 13 "LCM_AEB_CAMERA_CROSS_CHECK" 12 "LCM_AEB_YOUNG_TRACK" 11 "LCM_AEB_OTHER" 10 "LCM_AEB_ACTIVE" 9 "LCM_AEB_OVERRIDE" 8 "LCM_AEB_DELAYED_EVADING_DISTANCE" 7 "LCM_AEB_DELAYED_REQUIRED_ACCELERATION" 6 "LCM_AEB_CURRENT_REQUIRED_ACCELERATION" 5 "LCM_AEB_COLLISION_OVERLAP_RATIO" 4 "LCM_AEB_RELATIVE_VELOCITY" 3 "LCM_AEB_ABSOLUTE_ACCELERATION" 2 "LCM_AEB_NO_COLLISION_OBJECT" 1 "LCM_AEB_UNAVAILABLE" 0 "LCM_AEB_FAULT" ;
VAL_ 1497 DAS_handsOnDetected 2 "HANDS_ON_DETECTED" 1 "HANDS_ON_NOT_DETECTED" 0 "HANDS_ON_SNA" ;
VAL_ 1497 DAS_driveOnNavUnavailableReason 25 "DON_BLINKER_FAULTED" 24 "DON_UNAVAILABLE_AUDIO" 23 "DON_SCENE_TAG_SUN_GLARE" 22 "DON_SCENE_TAG_SEVERE_WEATHER" 21 "DON_SCENE_TAG_LENS_FLARE" 20 "DON_SCENE_TAG_FULLY_BLOCKED" 19 "DON_SCENE_TAG_FOG" 18 "DON_SCENE_TAG_BLURRY" 17 "DON_SCENE_TAG_BAD_CAMERA" 16 "DON_NAV_ROUTE_NOT_ACTIVE" 15 "DON_FEATURE_NOT_ENABLED" 14 "DON_AUTOPILOT_UNAVAILABLE" 13 "DON_INCOMPATIBLE_WAY" 12 "DON_HIGH_CURVATURE" 11 "DON_TOLLBOOTH_DETECTED" 10 "DON_CONSTRUCTION_DETECTED" 9 "DON_AUTO_WIPER_ACTIVE" 8 "DON_IMPLAUSIBLE_MAP_DATA" 7 "DON_GPS_DEGRADED" 6 "DON_ULTRASONICS_INVALID" 5 "DON_EDGE_LOCALIZATION_FAILED" 4 "DON_ROUTE_DOWNLOAD_FAILED" 3 "DON_UNAVAILABLE_CAMERA_BLOCKED" 2 "DON_CAMERA_UNAVAILABLE" 1 "DON_INVALID_NAV_GOAL" 0 "DON_UNAVAILABLE_NONE" ;
VAL_ 1497 DAS_accUnavailableReason 76 "ACC_UNAVAILABLE_REASON_SEATBELT_UNBUCKLED" 75 "ACC_UNAVAILABLE_REASON_DOOR_OPEN" 74 "ACC_UNAVAILABLE_REASON_FRUNK_OPEN" 73 "ACC_UNAVAILABLE_REASON_TRUNK_OPEN" 72 "ACC_UNAVAILABLE_REASON_OFF_ROAD_MODE_ACTIVE" 71 "ACC_UNAVAILABLE_REASON_SUPPRESS_FOR_RECENT_SCROLL_WHEEL_INTERACTION" 70 "ACC_UNAVAILABLE_REASON_SUPPRESS_FOR_RECENT_AUTOPARK_ACTIVATION" 69 "ACC_UNAVAILABLE_REASON_USER_SETTINGS_NOT_SUPPORTED" 68 "ACC_UNAVAILABLE_REASON_AUTOSTEER_INACTIVE_FOR_SINGLE_CLICK" 67 "ACC_UNAVAILABLE_REASON_AUTOSTEER_UNAVAILABLE_FOR_SINGLE_CLICK" 66 "ACC_UNAVAILABLE_REASON_TASK_FLOW_TRACE_TIMEOUT_SLAM" 65 "ACC_UNAVAILABLE_REASON_TASK_FLOW_TRACE_TIMEOUT_LOCALIZATION" 64 "ACC_UNAVAILABLE_REASON_TASK_FLOW_TRACE_TIMEOUT_STATIC_WORLD" 63 "ACC_UNAVAILABLE_REASON_TASK_FLOW_TRACE_TIMEOUT_DYNAMIC_WORLD" 62 "ACC_UNAVAILABLE_REASON_TASK_FLOW_TRACE_TIMEOUT_UNKNOWN" 61 "ACC_UNAVAILABLE_REASON_EXTENDED_COMPUTE_INACTIVE_PCIE_LINK_HEALTH" 60 "ACC_UNAVAILABLE_REASON_EXTENDED_COMPUTE_INACTIVE_ETHERNET_LINK_HEALTH" 59 "ACC_UNAVAILABLE_REASON_EXTENDED_COMPUTE_INACTIVE_OTHER_SOC_HEALTH_CRITICAL" 58 "ACC_UNAVAILABLE_REASON_EXTENDED_COMPUTE_INACTIVE_OTHER_SOC_HEALTH_UNKNOWN" 57 "ACC_UNAVAILABLE_REASON_AHB_MANUAL_OVERRIDE" 56 "ACC_UNAVAILABLE_REASON_EXTENDED_COMPUTE_INACTIVE" 55 "ACC_UNAVAILABLE_REASON_DRIVER_NOT_PRESENT" 54 "ACC_UNAVAILABLE_REASON_LOW_ODOMETRY" 53 "ACC_UNAVAILABLE_REASON_PERCEPTION_HEALTH_STALE" 52 "ACC_UNAVAILABLE_REASON_PERCEPTION_HEALTH_POST_PROCESSING" 51 "ACC_UNAVAILABLE_REASON_RECENT_USER_CANCELLATION" 50 "ACC_UNAVAILABLE_REASON_CITY_STREETS_REF_TOO_SHORT" 49 "ACC_UNAVAILABLE_REASON_INVALID_BEHAVIOR" 48 "ACC_UNAVAILABLE_REASON_RECENT_GEAR_SHIFT" 47 "ACC_UNAVAILABLE_REASON_IBOOSTER_MIA" 46 "ACC_UNAVAILABLE_INTEGRATOR_HEALTH_CRITICAL" 45 "ACC_UNAVAILABLE_REASON_UNKNOWN" 44 "ACC_UNAVAILABLE_REASON_RADAR_VERSION_MISMATCH" 43 "ACC_UNAVAILABLE_REASON_AP_NOT_CONFIGURED" 42 "ACC_UNAVAILABLE_REASON_INVALID_VEHICLE_SPEED" 41 "ACC_UNAVAILABLE_REASON_INVALID_DI_PEDAL_POS" 40 "ACC_UNAVAILABLE_REASON_W048_FEATURES_DISABLED" 39 "ACC_UNAVAILABLE_REASON_FAILED_AUTOSTEER_ACTIVATION" 38 "ACC_UNAVAILABLE_REASON_AEB_ACTIVE" 37 "ACC_UNAVAILABLE_REASON_AVAILABILITY_CHECK_HYSTERESIS" 36 "ACC_UNAVAILABLE_REASON_SONIC_OBSTACLE_DETECTED" 35 "ACC_UNAVAILABLE_REASON_TRACKED_OBSTACLE_DETECTED" 34 "ACC_UNAVAILABLE_REASON_STEERING_WHEEL_ANGLE" 33 "ACC_UNAVAILABLE_REASON_ROAD_CLASS" 32 "ACC_UNAVAILABLE_REASON_BELOW_MIN_SPEED" 31 "ACC_UNAVAILABLE_REASON_PEDESTRIAN_PRESENT_OR_NO_VEHICLE" 30 "ACC_UNAVAILABLE_REASON_BELOW_MAX_UNAVAILABLE_SPEED" 29 "ACC_UNAVAILABLE_REASON_ESP_PARTY_MIA" 28 "ACC_UNAVAILABLE_REASON_EPAS_PARTY_MIA" 27 "ACC_UNAVAILABLE_REASON_DI_PARTY_MIA" 26 "ACC_UNAVAILABLE_REASON_ECU_THERMAL_ISSUE" 25 "ACC_UNAVAILABLE_REASON_CAMERA_FAILSAFES" 24 "ACC_UNAVAILABLE_REASON_ESP_MIA" 23 "ACC_UNAVAILABLE_REASON_EPAS_MIA" 22 "ACC_UNAVAILABLE_REASON_GTW_MIA" 21 "ACC_UNAVAILABLE_REASON_DI_MIA" 20 "ACC_UNAVAILABLE_REASON_NOT_IN_DRIVE" 19 "ACC_UNAVAILABLE_REASON_CONTROLLER_INDETERMINATE" 18 "ACC_UNAVAILABLE_REASON_CONTROLLER_REFERENCE_TOO_SHORT" 17 "ACC_UNAVAILABLE_REASON_CONTROLLER_BAD_UPDATE" 16 "ACC_UNAVAILABLE_REASON_CONTROLLER_STALE_LOCALIZATION" 15 "ACC_UNAVAILABLE_REASON_CONTROLLER_STALE_REFERENCE" 14 "ACC_UNAVAILABLE_REASON_CONTROLLER_REFERENCE_UNHEALTHY" 13 "ACC_UNAVAILABLE_REASON_CONTROLLER_SOLVER_UNHEALTHY" 12 "ACC_UNAVAILABLE_REASON_CONTROLLER_NOT_ALLOWED" 11 "ACC_UNAVAILABLE_REASON_CAMERA_CALIBRATION" 10 "ACC_UNAVAILABLE_REASON_CAMERA_PITCH" 9 "ACC_UNAVAILABLE_REASON_CAMERA_BLOCKED" 8 "ACC_UNAVAILABLE_REASON_RADAR_MIA" 7 "ACC_UNAVAILABLE_REASON_RADAR_FAULT" 6 "ACC_UNAVAILABLE_REASON_RADAR_BLIND" 5 "ACC_UNAVAILABLE_REASON_PERCEPTION_HEALTH_VISION" 4 "ACC_UNAVAILABLE_REASON_PERCEPTION_HEALTH_RADAR" 3 "ACC_UNAVAILABLE_REASON_DI_CRUISE_STATE_CRITICAL" 2 "ACC_UNAVAILABLE_REASON_AUTOPARK_STATE" 1 "ACC_UNAVAILABLE_REASON_SYSTEM_HEALTH_CRITICAL" 0 "ACC_UNAVAILABLE_REASON_NONE" ;
VAL_ 1497 DAS_pmmNotActivatingReason 24 "PMM_NOT_ACTIVATING_OTHER" 23 "PMM_NOT_ACTIVATING_DI_STATUS" 22 "PMM_NOT_ACTIVATING_HARDWARE_NOT_SUPPORTED" 21 "PMM_NOT_ACTIVATING_DYNAMIC_BARRIER" 20 "PMM_NOT_ACTIVATING_TRAILER_MODE" 19 "PMM_NOT_ACTIVATING_DROPPED_CIPV" 18 "PMM_NOT_ACTIVATING_SPEED_DERIVATIVE" 17 "PMM_NOT_ACTIVATING_SCENE_TAG" 16 "PMM_NOT_ACTIVATING_MODE" 15 "PMM_NOT_ACTIVATING_SPEED_PROFILE" 14 "PMM_NOT_ACTIVATING_INSEVERE_CIPV" 13 "PMM_NOT_ACTIVATING_WHEEL_ACCELERATION" 12 "PMM_NOT_ACTIVATING_ULTRASONIC_VELOCITY" 11 "PMM_NOT_ACTIVATING_ULTRASONIC_DISTANCE" 10 "PMM_NOT_ACTIVATING_USER_DISABLED" 9 "PMM_NOT_ACTIVATING_ROAD" 8 "PMM_NOT_ACTIVATING_SDI_HEALTH" 7 "PMM_NOT_ACTIVATING_VEHICLE_SPEED" 6 "PMM_NOT_ACTIVATING_TRACK_MODE" 5 "PMM_NOT_ACTIVATING_GEAR" 4 "PMM_NOT_ACTIVATING_PEDAL_RATE" 3 "PMM_NOT_ACTIVATING_PEDAL_POS" 2 "PMM_NOT_ACTIVATING_OBSTACLE_GRID" 1 "PMM_NOT_ACTIVATING_APP_FEATURES_NOT_AVAILABLE" 0 "PMM_NOT_ACTIVATING_NONE" ;
VAL_ 1497 DAS_desiredTarget_dx 255 "SNA" ;
VAL_ 1497 DAS_radarTarget2_dx 0 "NO_TARGET" ;
VAL_ 1497 DAS_radarTarget3_dx 0 "NO_TARGET" ;
VAL_ 1497 DAS_radarTarget4_dx 0 "NO_TARGET" ;
VAL_ 1497 DAS_closestInLaneTargetDx 0 "NO_TARGET" ;
VAL_ 1497 DAS_secondInLaneTargetDx 0 "NO_TARGET" ;
VAL_ 1497 DAS_closestLeftLaneTargetDx 0 "NO_TARGET" ;
VAL_ 1497 DAS_closestRightLaneTargetDx 0 "NO_TARGET" ;
VAL_ 1497 DAS_closestInLaneTargetVxRel 0 "NO_TARGET" ;
VAL_ 1337 DAS_infoIndex 255 "END" 24 "EYEQ_FFS" 23 "EYEQ_APP" 20 "UDS_PROTOCOL_BOOTCRC" 19 "VERSION_DEPRECATED" 18 "BOOTLOADER_GITHASH" 17 "APP_GITHASH" 16 "EYEQ_BOOT" 15 "BOOTLOADER_CRC" 14 "BOOTLOADER_SVN" 13 "APP_CRC" 11 "PCBAID_ASSYID_USAGEID" 10 "BUILD_HWID_COMPONENTID" 9 "DEPRECATED_9" 8 "DEPRECATED_8" 7 "DEPRECATED_7" 6 "DEPRECATED_6" 5 "DEPRECATED_5" 4 "DEPRECATED_4" 3 "DEPRECATED_3" 2 "DEPRECATED_2" 1 "DEPRECATED_1" 0 "DEPRECATED_0" ;
VAL_ 1337 DAS_infoBuildType 4 "INFO_MFG_BUILD" 3 "INFO_TRACEABLE_CI_BUILD" 2 "INFO_LOCAL_BUILD" 1 "INFO_PLATFORM_BUILD" 0 "INFO_UNKNOWN_BUILD" ;
VAL_ 569 DAS_leftLineUsage 3 "BLACKLISTED" 2 "FUSED" 1 "AVAILABLE" 0 "REJECTED_UNAVAILABLE" ;
VAL_ 569 DAS_rightLineUsage 3 "BLACKLISTED" 2 "FUSED" 1 "AVAILABLE" 0 "REJECTED_UNAVAILABLE" ;
VAL_ 569 DAS_leftFork 3 "FORK_UNAVAILABLE" 2 "FORK_SELECTED" 1 "FORK_AVAILABLE" 0 "FORK_NONE" ;
VAL_ 569 DAS_rightFork 3 "FORK_UNAVAILABLE" 2 "FORK_SELECTED" 1 "FORK_AVAILABLE" 0 "FORK_NONE" ;
VAL_ 921 DAS_autopilotState 15 "SNA" 14 "FAULT" 9 "ABORTED" 8 "ABORTING" 6 "ACTIVE_FSD" 5 "ACTIVE_NAV" 4 "ACTIVE_RESTRICTED" 3 "ACTIVE_NOMINAL" 2 "AVAILABLE" 1 "UNAVAILABLE" 0 "DISABLED" ;
VAL_ 921 DAS_blindSpotRearLeft 3 "SNA" 2 "WARNING_LEVEL_2" 1 "WARNING_LEVEL_1" 0 "NO_WARNING" ;
VAL_ 921 DAS_blindSpotRearRight 3 "SNA" 2 "WARNING_LEVEL_2" 1 "WARNING_LEVEL_1" 0 "NO_WARNING" ;
VAL_ 921 DAS_fusedSpeedLimit 31 "NONE" 0 "UNKNOWN_SNA" ;
VAL_ 921 DAS_suppressSpeedWarning 1 "Suppress_Speed_Warning" 0 "Do_Not_Suppress" ;
VAL_ 921 DAS_visionOnlySpeedLimit 31 "NONE" 0 "UNKNOWN_SNA" ;
VAL_ 921 DAS_heaterState 1 "HEATER_ON" 0 "HEATER_OFF_SNA" ;
VAL_ 921 DAS_forwardCollisionWarning 3 "SNA" 1 "FORWARD_COLLISION_WARNING" 0 "NONE" ;
VAL_ 921 DAS_autoparkReady 1 "AUTOPARK_READY" 0 "AUTOPARK_UNAVAILABLE" ;
VAL_ 921 DAS_lssState 7 "LSS_STATE_OFF" 6 "LSS_STATE_ABORT" 5 "LSS_STATE_BLINDSPOT" 4 "LSS_STATE_MONITOR" 3 "LSS_STATE_ELK" 2 "LSS_STATE_LKA" 1 "LSS_STATE_LDW" 0 "LSS_STATE_FAULT" ;
VAL_ 921 DAS_sideCollisionAvoid 3 "SNA" 2 "AVOID_RIGHT" 1 "AVOID_LEFT" 0 "NONE" ;
VAL_ 921 DAS_sideCollisionWarning 3 "WARN_LEFT_RIGHT" 2 "WARN_RIGHT" 1 "WARN_LEFT" 0 "NONE" ;
VAL_ 921 DAS_sideCollisionInhibit 1 "INHIBIT" 0 "NO_INHIBIT" ;
VAL_ 921 DAS_laneDepartureWarning 5 "SNA" 4 "RIGHT_WARNING_SEVERE" 3 "LEFT_WARNING_SEVERE" 2 "RIGHT_WARNING" 1 "LEFT_WARNING" 0 "NONE" ;
VAL_ 921 DAS_fleetSpeedState 3 "FLEETSPEED_HOLD" 2 "FLEETSPEED_ACTIVE" 1 "FLEETSPEED_AVAILABLE" 0 "FLEETSPEED_UNAVAILABLE" ;
VAL_ 921 DAS_autopilotHandsOnState 15 "LC_HANDS_ON_SNA" 10 "LC_HANDS_ON_REQD_ESCALATED_CHIME_2" 9 "LC_HANDS_ON_REQD_ESCALATED_CHIME_1" 8 "LC_HANDS_ON_SUSPENDED" 7 "LC_HANDS_ON_REQD_STRUCK_OUT" 6 "LC_HANDS_ON_REQD_SLOWING" 5 "LC_HANDS_ON_REQD_CHIME_2" 4 "LC_HANDS_ON_REQD_CHIME_1" 3 "LC_HANDS_ON_REQD_VISUAL" 2 "LC_HANDS_ON_REQD_NOT_DETECTED" 1 "LC_HANDS_ON_REQD_DETECTED" 0 "LC_HANDS_ON_NOT_REQD" ;
VAL_ 921 DAS_autoLaneChangeState 31 "ALC_SNA" 30 "ALC_ABORT_MISSION_PLAN_INVALID" 29 "ALC_ABORT_TIMEOUT" 28 "ALC_WAITING_HANDS_ON" 27 "ALC_BLOCKED_LANE_TYPE_R" 26 "ALC_BLOCKED_LANE_TYPE_L" 25 "ALC_BLOCKED_VEH_TTC_AND_USS_R" 24 "ALC_BLOCKED_VEH_TTC_R" 23 "ALC_BLOCKED_VEH_TTC_AND_USS_L" 22 "ALC_BLOCKED_VEH_TTC_L" 21 "ALC_UNAVAILABLE_SOLID_LANE_LINE" 20 "ALC_ABORT_OTHER_REASON" 19 "ALC_ABORT_BLINKER_TURNED_OFF" 18 "ALC_ABORT_LC_HEALTH_BAD" 17 "ALC_ABORT_POOR_VIEW_RANGE" 16 "ALC_ABORT_SIDE_OBSTACLE_PRESENT_R" 15 "ALC_ABORT_SIDE_OBSTACLE_PRESENT_L" 14 "ALC_WAITING_FOR_FWD_OBST_TO_PASS_R" 13 "ALC_WAITING_FOR_FWD_OBST_TO_PASS_L" 12 "ALC_WAITING_FOR_SIDE_OBST_TO_PASS_R" 11 "ALC_WAITING_FOR_SIDE_OBST_TO_PASS_L" 10 "ALC_IN_PROGRESS_R" 9 "ALC_IN_PROGRESS_L" 8 "ALC_AVAILABLE_BOTH" 7 "ALC_AVAILABLE_ONLY_R" 6 "ALC_AVAILABLE_ONLY_L" 5 "ALC_UNAVAILABLE_VEHICLE_SPEED" 4 "ALC_UNAVAILABLE_EXITING_HIGHWAY" 3 "ALC_UNAVAILABLE_TP_FOLLOW" 2 "ALC_UNAVAILABLE_SONICS_INVALID" 1 "ALC_UNAVAILABLE_NO_LANES" 0 "ALC_UNAVAILABLE_DISABLED" ;
VAL_ 905 DAS_accSpeedLimit 511 "SNA" 0 "NONE" ;
VAL_ 905 DAS_pmmObstacleSeverity 7 "PMM_SNA" 6 "PMM_ACCEL_LIMIT" 5 "PMM_CRASH_FRONT" 4 "PMM_CRASH_REAR" 3 "PMM_BRAKE_REQUEST" 2 "PMM_IMMINENT_FRONT" 1 "PMM_IMMINENT_REAR" 0 "PMM_NONE" ;
VAL_ 905 DAS_pmmLoggingRequest 1 "TRUE" 0 "FALSE" ;
VAL_ 905 DAS_activationFailureStatus 2 "LC_ACTIVATION_FAILED_2" 1 "LC_ACTIVATION_FAILED_1" 0 "LC_ACTIVATION_IDLE" ;
VAL_ 905 DAS_pmmUltrasonicsFaultReason 4 "PMM_ULTRASONICS_INVALID_MIA" 3 "PMM_ULTRASONICS_BLOCKED_BOTH" 2 "PMM_ULTRASONICS_BLOCKED_REAR" 1 "PMM_ULTRASONICS_BLOCKED_FRONT" 0 "PMM_ULTRASONICS_NO_FAULT" ;
VAL_ 905 DAS_pmmRadarFaultReason 2 "PMM_RADAR_INVALID_MIA" 1 "PMM_RADAR_BLOCKED_FRONT" 0 "PMM_RADAR_NO_FAULT" ;
VAL_ 905 DAS_pmmSysFaultReason 7 "PMM_FAULT_BRAKE_PEDAL_INHIBIT" 6 "PMM_FAULT_ROAD_TYPE" 5 "PMM_FAULT_DISABLED_BY_USER" 4 "PMM_FAULT_STEERING_ANGLE_RATE" 3 "PMM_FAULT_DI_FAULT" 2 "PMM_FAULT_SPEED" 1 "PMM_FAULT_DAS_DISABLED" 0 "PMM_FAULT_NONE" ;
VAL_ 905 DAS_pmmCameraFaultReason 2 "PMM_CAMERA_INVALID_MIA" 1 "PMM_CAMERA_BLOCKED_FRONT" 0 "PMM_CAMERA_NO_FAULT" ;
VAL_ 905 DAS_ACC_report 24 "ACC_REPORT_BEHAVIOR_REPORT" 23 "ACC_REPORT_CAMERA_ONLY" 22 "ACC_REPORT_RADAR_OBJ_FIVE" 21 "ACC_REPORT_CIPV_CUTTING_OUT" 20 "ACC_REPORT_MCVLR_IN_PATH" 19 "ACC_REPORT_MCVLR_DPP" 18 "ACC_REPORT_FLEET_SPEEDS" 17 "ACC_REPORT_TARGET_MCP" 16 "ACC_REPORT_RADAR_OBJ_TWO" 15 "ACC_REPORT_RADAR_OBJ_ONE" 14 "ACC_REPORT_LC_EXTERNAL_STATE_ACTIVE_RESTRICTED" 13 "ACC_REPORT_LC_EXTERNAL_STATE_ABORTED" 12 "ACC_REPORT_LC_EXTERNAL_STATE_ABORTING" 11 "ACC_REPORT_LC_HANDS_ON_REQD_STRUCK_OUT" 10 "ACC_REPORT_CSA" 9 "ACC_REPORT_TARGET_TYPE_FAULT" 8 "ACC_REPORT_TARGET_TYPE_IPSO" 7 "ACC_REPORT_TARGET_TYPE_TRAFFIC_LIGHT" 6 "ACC_REPORT_TARGET_TYPE_STOP_SIGN" 5 "ACC_REPORT_TARGET_CUTIN" 4 "ACC_REPORT_TARGET_MCVR" 3 "ACC_REPORT_TARGET_MCVL" 2 "ACC_REPORT_TARGET_IN_FRONT_OF_CIPV" 1 "ACC_REPORT_TARGET_CIPV" 0 "ACC_REPORT_TARGET_NONE" ;
VAL_ 905 DAS_csaState 3 "CSA_EXTERNAL_STATE_HOLD" 2 "CSA_EXTERNAL_STATE_ENABLE" 1 "CSA_EXTERNAL_STATE_AVAILABLE" 0 "CSA_EXTERNAL_STATE_UNAVAILABLE" ;
VAL_ 905 DAS_radarTelemetry 2 "RADAR_TELEMETRY_URGENT" 1 "RADAR_TELEMETRY_NORMAL" 0 "RADAR_TELEMETRY_IDLE" ;
VAL_ 905 DAS_robState 3 "ROB_STATE_MAPLESS" 2 "ROB_STATE_ACTIVE" 1 "ROB_STATE_MEASURE" 0 "ROB_STATE_INHIBITED" ;
VAL_ 905 DAS_driverInteractionLevel 2 "CONTINUED_DRIVER_NOT_INTERACTING" 1 "DRIVER_NOT_INTERACTING" 0 "DRIVER_INTERACTING" ;
VAL_ 905 DAS_ppOffsetDesiredRamp 128 "PP_NO_OFFSET" ;
VAL_ 905 DAS_longCollisionWarning 15 "FCM_LONG_COLLISION_WARNING_SNA" 12 "FCM_LONG_COLLISION_WARNING_VEHICLE_CIPV2" 11 "FCM_LONG_COLLISION_WARNING_VEHICLE_MCVR2" 10 "FCM_LONG_COLLISION_WARNING_VEHICLE_MCVR" 9 "FCM_LONG_COLLISION_WARNING_VEHICLE_MCVL2" 8 "FCM_LONG_COLLISION_WARNING_VEHICLE_MCVL" 7 "FCM_LONG_COLLISION_WARNING_VEHICLE_CUTIN" 6 "FCM_LONG_COLLISION_WARNING_VEHICLE_CIPV" 5 "FCM_LONG_COLLISION_WARNING_TFL_STOPLINE" 4 "FCM_LONG_COLLISION_WARNING_STOPSIGN_STOPLINE" 3 "FCM_LONG_COLLISION_WARNING_IPSO" 2 "FCM_LONG_COLLISION_WARNING_PEDESTRIAN" 1 "FCM_LONG_COLLISION_WARNING_VEHICLE_UNKNOWN" 0 "FCM_LONG_COLLISION_WARNING_NONE" ;
VAL_ 586 DAS_autosteerVehiclesUsage 3 "BLACKLISTED" 2 "FUSED" 1 "AVAILABLE" 0 "REJECTED_UNAVAILABLE" ;
VAL_ 586 DAS_autosteerHPPUsage 3 "BLACKLISTED" 2 "FUSED" 1 "AVAILABLE" 0 "REJECTED_UNAVAILABLE" ;
VAL_ 586 DAS_autosteerNavigationUsage 3 "BLACKLISTED" 2 "FUSED" 1 "AVAILABLE" 0 "REJECTED_UNAVAILABLE" ;
VAL_ 586 DAS_autosteerModelUsage 3 "BLACKLISTED" 2 "FUSED" 1 "AVAILABLE" 0 "REJECTED_UNAVAILABLE" ;
VAL_ 586 DAS_autosteerBottsDotsUsage 3 "BLACKLISTED" 2 "FUSED" 1 "AVAILABLE" 0 "REJECTED_UNAVAILABLE" ;
VAL_ 586 DAS_offsetSide 3 "OFFSET_BOTH_OBJECTS" 2 "OFFSET_LEFT_OBJECT" 1 "OFFSET_RIGHT_OBJECT" 0 "NO_OFFSET" ;
VAL_ 586 DAS_roadSurfaceType 2 "ROAD_SURFACE_ENHANCED" 1 "ROAD_SURFACE_NORMAL" 0 "ROAD_SURFACE_SNA" ;
VAL_ 586 DAS_autosteerHealthState 5 "HEALTH_FAULT" 4 "HEALTH_ABORTING" 3 "HEALTH_SEVERELY_DEGRADED" 2 "HEALTH_DEGRADED" 1 "HEALTH_NOMINAL" 0 "HEALTH_UNAVAILABLE" ;
VAL_ 586 DAS_lastLinePreferenceReason 15 "NONE" 5 "COUNTRY_DRIVING_SIDE" 4 "AVOID_ONCOMING_LANES" 3 "NAVIGATION_BRANCH" 2 "NEIGHBOR_LANE_PROBABILIY" 1 "AGREEMENT_WITH_NEIGHBOR_LANES" 0 "OTHER_LANE_DISAGREES_WITH_MODEL" ;
VAL_ 586 DAS_plannerState 7 "TP_EXTSTATE_LANECHANGE_ABORT" 6 "TP_EXTSTATE_LANECHANGE_WAIT_FOR_FWD_OBSTACLE" 5 "TP_EXTSTATE_LANECHANGE_WAIT_FOR_SIDE_OBSTACLE" 4 "TP_EXTSTATE_LANECHANGE_IN_PROGRESS" 3 "TP_EXTSTATE_LANECHANGE_REQUESTED" 2 "TP_EXTSTATE_FOLLOW" 1 "TP_EXTSTATE_VL" 0 "TP_EXTSTATE_DISABLED" ;
VAL_ 586 DAS_lastAutosteerAbortReason 36 "UI_ABORT_REASON_AHB_MANUAL_OVERRIDE" 35 "UI_ABORT_REASON_DRIVER_NOT_PRESENT" 34 "UI_ABORT_REASON_USER_OVERRIDE_STRIKEOUT" 33 "UI_ABORT_REASON_SEATBELT_UNBUCKLED" 32 "UI_ABORT_REASON_AEB" 31 "UI_ABORT_REASON_NO_ABORT" 30 "UI_ABORT_REASON_CAMERA_FAILSAFES" 29 "UI_ABORT_REASON_ACC_CANCEL" 28 "UI_ABORT_REASON_EPAS_ERROR_CODE" 27 "UI_ABORT_REASON_PLANNER_OUTPUT_INVALID" 26 "UI_ABORT_REASON_FOLLOWER_OUTPUT_INVALID" 25 "UI_ABORT_REASON_VEHICLE_SPEED_ABOVE_MAX" 24 "UI_ABORT_REASON_DRIVING_OFF_NAV" 23 "UI_ABORT_REASON_CID_SWITCH_DISABLED" 22 "UI_ABORT_REASON_CRUISE_FAULT" 21 "UI_ABORT_REASON_COMPONENT_MIA" 20 "UI_ABORT_REASON_EPAS_EAC_DENIED" 19 "UI_ABORT_REASON_SIDE_COLLISION_IMMINENT" 18 "UI_ABORT_REASON_TRAILER_MODE" 17 "UI_ABORT_REASON_CAM_WATCHDOG" 16 "UI_ABORT_REASON_CAM_MSG_MIA" 15 "UI_ABORT_REASON_ME_MAIN_STATE_NOT_VISION" 14 "UI_ABORT_REASON_APP_ME_STATE_NOT_VISION" 2 "UI_ABORT_REASON_HM_STEERING_ERROR" 1 "UI_ABORT_REASON_HM_VIRTUAL_LANE_NO_INPUTS" 0 "UI_ABORT_REASON_HM_LANE_VIEW_RANGE" ;
VAL_ 586 DAS_navAvailable 1 "DAS_NAV_AVAILABLE" 0 "DAS_NAV_UNAVAILABLE" ;
VAL_ 586 DAS_accSmartSpeedState 7 "SNA" 5 "OFFRAMP_DELAY" 4 "SET_SPEED_SET_REQUESTED" 3 "ACTIVE_ONRAMP" 2 "ACTIVE_INTEGRATING" 1 "ACTIVE_OFFRAMP" 0 "NOT_ACTIVE" ;
VAL_ 586 DAS_ulcInProgress 1 "ULC_ACTIVE" 0 "ULC_INACTIVE" ;
VAL_ 586 DAS_isaSystemState 3 "ISA_UNAVAILABLE" 2 "ISA_INVALID" 1 "ISA_ASSUMED_LIMITS" 0 "ISA_NOMINAL" ;
VAL_ 586 DAS_behaviorType 3 "DAS_BEHAVIOR_LANE_CHANGE_RIGHT" 2 "DAS_BEHAVIOR_LANE_CHANGE_LEFT" 1 "DAS_BEHAVIOR_IN_LANE" 0 "DAS_BEHAVIOR_INVALID" ;
VAL_ 586 DAS_ulcType 2 "ULC_TYPE_SPEED" 1 "ULC_TYPE_NAV" 0 "ULC_TYPE_NONE" ;
VAL_ 586 DAS_rearVehDetectedThisCycle 1 "VEHICLE_DETECTED" 0 "VEHICLE_NOT_DETECTED" ;
VAL_ 586 DAS_rearLeftVehDetectedCurrent 1 "VEHICLE_DETECTED" 0 "VEHICLE_NOT_DETECTED" ;
VAL_ 586 DAS_rearRightVehDetectedTrip 1 "VEHICLE_DETECTED" 0 "VEHICLE_NOT_DETECTED" ;
VAL_ 586 DAS_rearLeftVehDetectedTrip 1 "VEHICLE_DETECTED" 0 "VEHICLE_NOT_DETECTED" ;
